VERSION ""

NS_ :

BS_:

BU_: Dummy_FO TestTool_FO LRR_FO RFSRR_FO LFSRR_FO RSRR_FO VIS_FO EOCM_F_FO

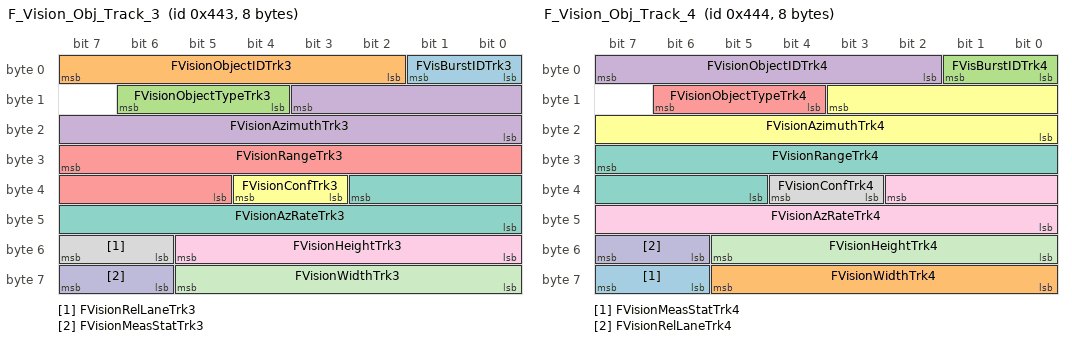
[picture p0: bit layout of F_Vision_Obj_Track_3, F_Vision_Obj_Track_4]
BO_ 1091 F_Vision_Obj_Track_3: 8 VIS_FO
 SG_ FVisBurstIDTrk3 : 1|2@0+ (1,0) [0|3] ""  EOCM_F_FO
 SG_ FVisionObjectIDTrk3 : 7|6@0+ (1,0) [0|63] ""  EOCM_F_FO
 SG_ FVisionObjectTypeTrk3 : 14|3@0+ (1,0) [0|0] ""  EOCM_F_FO
 SG_ FVisionAzimuthTrk3 : 11|12@0- (0.125,0) [-256|255.875] "deg"  EOCM_F_FO
 SG_ FVisionRangeTrk3 : 31|11@0+ (0.125,0) [0|255.875] "m"  EOCM_F_FO
 SG_ FVisionConfTrk3 : 36|2@0+ (1,0) [0|0] ""  EOCM_F_FO
 SG_ FVisionAzRateTrk3 : 34|11@0- (0.125,0) [-128|127.875] "deg/s"  EOCM_F_FO
 SG_ FVisionRelLaneTrk3 : 55|2@0+ (1,0) [0|0] ""  EOCM_F_FO
 SG_ FVisionHeightTrk3 : 53|6@0+ (0.25,0) [0|15.75] "m"  EOCM_F_FO
 SG_ FVisionMeasStatTrk3 : 63|2@0+ (1,0) [0|0] ""  EOCM_F_FO
 SG_ FVisionWidthTrk3 : 61|6@0+ (0.25,0) [0|15.75] "m"  EOCM_F_FO

BO_ 1092 F_Vision_Obj_Track_4: 8 VIS_FO
 SG_ FVisionMeasStatTrk4 : 63|2@0+ (1,0) [0|0] ""  EOCM_F_FO
 SG_ FVisionWidthTrk4 : 61|6@0+ (0.25,0) [0|15.75] "m"  EOCM_F_FO
 SG_ FVisBurstIDTrk4 : 1|2@0+ (1,0) [0|3] ""  EOCM_F_FO
 SG_ FVisionObjectIDTrk4 : 7|6@0+ (1,0) [0|63] ""  EOCM_F_FO
 SG_ FVisionObjectTypeTrk4 : 14|3@0+ (1,0) [0|0] ""  EOCM_F_FO
 SG_ FVisionAzimuthTrk4 : 11|12@0- (0.125,0) [-256|255.875] "deg"  EOCM_F_FO
 SG_ FVisionRangeTrk4 : 31|11@0+ (0.125,0) [0|255.875] "m"  EOCM_F_FO
 SG_ FVisionConfTrk4 : 36|2@0+ (1,0) [0|0] ""  EOCM_F_FO
 SG_ FVisionAzRateTrk4 : 34|11@0- (0.125,0) [-128|127.875] "deg/s"  EOCM_F_FO
 SG_ FVisionRelLaneTrk4 : 55|2@0+ (1,0) [0|0] ""  EOCM_F_FO
 SG_ FVisionHeightTrk4 : 53|6@0+ (0.25,0) [0|15.75] "m"  EOCM_F_FO

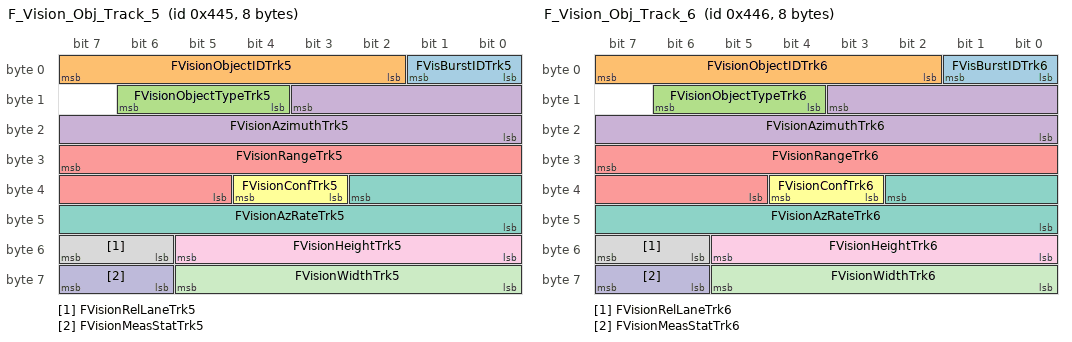
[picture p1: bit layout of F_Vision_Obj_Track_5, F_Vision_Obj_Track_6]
BO_ 1093 F_Vision_Obj_Track_5: 8 VIS_FO
 SG_ FVisBurstIDTrk5 : 1|2@0+ (1,0) [0|3] ""  EOCM_F_FO
 SG_ FVisionObjectIDTrk5 : 7|6@0+ (1,0) [0|63] ""  EOCM_F_FO
 SG_ FVisionObjectTypeTrk5 : 14|3@0+ (1,0) [0|0] ""  EOCM_F_FO
 SG_ FVisionAzimuthTrk5 : 11|12@0- (0.125,0) [-256|255.875] "deg"  EOCM_F_FO
 SG_ FVisionRangeTrk5 : 31|11@0+ (0.125,0) [0|255.875] "m"  EOCM_F_FO
 SG_ FVisionConfTrk5 : 36|2@0+ (1,0) [0|0] ""  EOCM_F_FO
 SG_ FVisionAzRateTrk5 : 34|11@0- (0.125,0) [-128|127.875] "deg/s"  EOCM_F_FO
 SG_ FVisionRelLaneTrk5 : 55|2@0+ (1,0) [0|0] ""  EOCM_F_FO
 SG_ FVisionHeightTrk5 : 53|6@0+ (0.25,0) [0|15.75] "m"  EOCM_F_FO
 SG_ FVisionMeasStatTrk5 : 63|2@0+ (1,0) [0|0] ""  EOCM_F_FO
 SG_ FVisionWidthTrk5 : 61|6@0+ (0.25,0) [0|15.75] "m"  EOCM_F_FO

BO_ 1094 F_Vision_Obj_Track_6: 8 VIS_FO
 SG_ FVisBurstIDTrk6 : 1|2@0+ (1,0) [0|3] ""  EOCM_F_FO
 SG_ FVisionObjectIDTrk6 : 7|6@0+ (1,0) [0|63] ""  EOCM_F_FO
 SG_ FVisionObjectTypeTrk6 : 14|3@0+ (1,0) [0|0] ""  EOCM_F_FO
 SG_ FVisionAzimuthTrk6 : 11|12@0- (0.125,0) [-256|255.875] "deg"  EOCM_F_FO
 SG_ FVisionRangeTrk6 : 31|11@0+ (0.125,0) [0|255.875] "m"  EOCM_F_FO
 SG_ FVisionConfTrk6 : 36|2@0+ (1,0) [0|0] ""  EOCM_F_FO
 SG_ FVisionAzRateTrk6 : 34|11@0- (0.125,0) [-128|127.875] "deg/s"  EOCM_F_FO
 SG_ FVisionRelLaneTrk6 : 55|2@0+ (1,0) [0|0] ""  EOCM_F_FO
 SG_ FVisionHeightTrk6 : 53|6@0+ (0.25,0) [0|15.75] "m"  EOCM_F_FO
 SG_ FVisionMeasStatTrk6 : 63|2@0+ (1,0) [0|0] ""  EOCM_F_FO
 SG_ FVisionWidthTrk6 : 61|6@0+ (0.25,0) [0|15.75] "m"  EOCM_F_FO

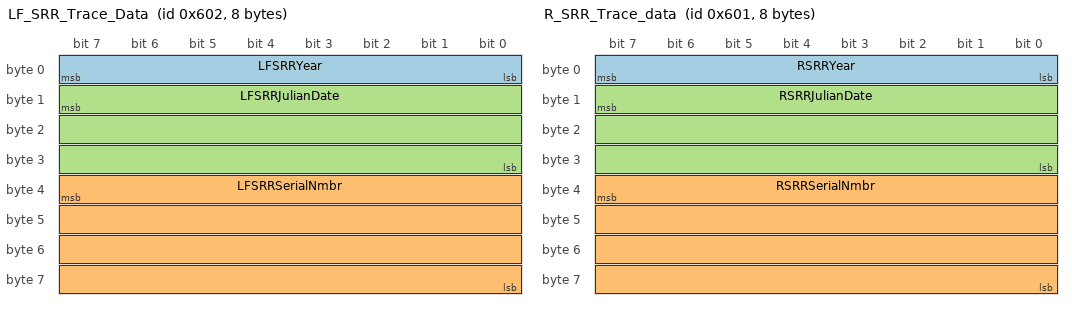
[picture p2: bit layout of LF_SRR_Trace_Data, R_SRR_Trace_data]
BO_ 1538 LF_SRR_Trace_Data: 8 LFSRR_FO
 SG_ LFSRRYear : 7|8@0+ (1,0) [0|0] ""  EOCM_F_FO
 SG_ LFSRRSerialNmbr : 39|32@0+ (1,0) [0|0] ""  EOCM_F_FO
 SG_ LFSRRJulianDate : 15|24@0+ (1,0) [0|0] ""  EOCM_F_FO

BO_ 1537 R_SRR_Trace_data: 8 RSRR_FO
 SG_ RSRRYear : 7|8@0+ (1,0) [0|0] ""  EOCM_F_FO
 SG_ RSRRSerialNmbr : 39|32@0+ (1,0) [0|0] ""  EOCM_F_FO
 SG_ RSRRJulianDate : 15|24@0+ (1,0) [0|0] ""  EOCM_F_FO

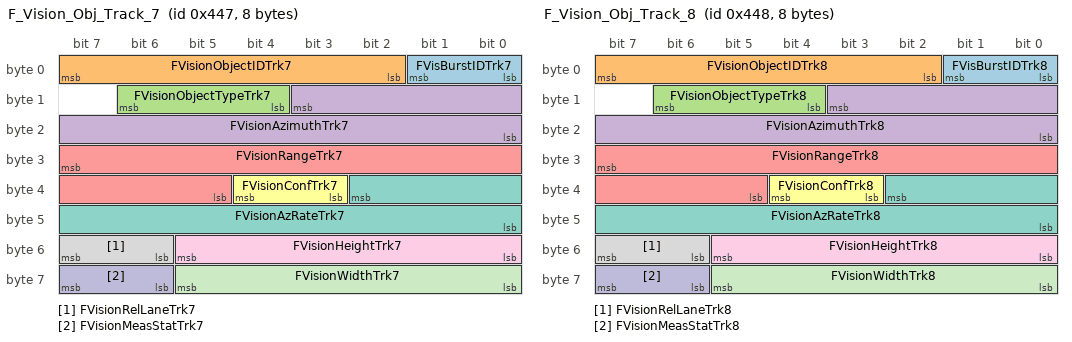
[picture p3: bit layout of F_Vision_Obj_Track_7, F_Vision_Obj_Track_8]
BO_ 1095 F_Vision_Obj_Track_7: 8 VIS_FO
 SG_ FVisBurstIDTrk7 : 1|2@0+ (1,0) [0|3] ""  EOCM_F_FO
 SG_ FVisionObjectIDTrk7 : 7|6@0+ (1,0) [0|63] ""  EOCM_F_FO
 SG_ FVisionObjectTypeTrk7 : 14|3@0+ (1,0) [0|0] ""  EOCM_F_FO
 SG_ FVisionAzimuthTrk7 : 11|12@0- (0.125,0) [-256|255.875] "deg"  EOCM_F_FO
 SG_ FVisionRangeTrk7 : 31|11@0+ (0.125,0) [0|255.875] "m"  EOCM_F_FO
 SG_ FVisionConfTrk7 : 36|2@0+ (1,0) [0|0] ""  EOCM_F_FO
 SG_ FVisionAzRateTrk7 : 34|11@0- (0.125,0) [-128|127.875] "deg/s"  EOCM_F_FO
 SG_ FVisionRelLaneTrk7 : 55|2@0+ (1,0) [0|0] ""  EOCM_F_FO
 SG_ FVisionHeightTrk7 : 53|6@0+ (0.25,0) [0|15.75] "m"  EOCM_F_FO
 SG_ FVisionMeasStatTrk7 : 63|2@0+ (1,0) [0|0] ""  EOCM_F_FO
 SG_ FVisionWidthTrk7 : 61|6@0+ (0.25,0) [0|15.75] "m"  EOCM_F_FO

BO_ 1096 F_Vision_Obj_Track_8: 8 VIS_FO
 SG_ FVisBurstIDTrk8 : 1|2@0+ (1,0) [0|3] ""  EOCM_F_FO
 SG_ FVisionObjectIDTrk8 : 7|6@0+ (1,0) [0|63] ""  EOCM_F_FO
 SG_ FVisionObjectTypeTrk8 : 14|3@0+ (1,0) [0|0] ""  EOCM_F_FO
 SG_ FVisionAzimuthTrk8 : 11|12@0- (0.125,0) [-256|255.875] "deg"  EOCM_F_FO
 SG_ FVisionRangeTrk8 : 31|11@0+ (0.125,0) [0|255.875] "m"  EOCM_F_FO
 SG_ FVisionConfTrk8 : 36|2@0+ (1,0) [0|0] ""  EOCM_F_FO
 SG_ FVisionAzRateTrk8 : 34|11@0- (0.125,0) [-128|127.875] "deg/s"  EOCM_F_FO
 SG_ FVisionRelLaneTrk8 : 55|2@0+ (1,0) [0|0] ""  EOCM_F_FO
 SG_ FVisionHeightTrk8 : 53|6@0+ (0.25,0) [0|15.75] "m"  EOCM_F_FO
 SG_ FVisionMeasStatTrk8 : 63|2@0+ (1,0) [0|0] ""  EOCM_F_FO
 SG_ FVisionWidthTrk8 : 61|6@0+ (0.25,0) [0|15.75] "m"  EOCM_F_FO

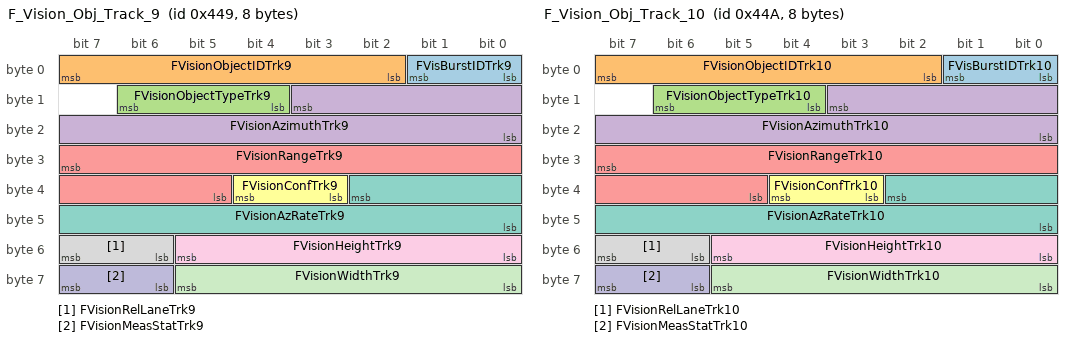
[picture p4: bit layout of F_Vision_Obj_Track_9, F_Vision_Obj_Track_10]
BO_ 1097 F_Vision_Obj_Track_9: 8 VIS_FO
 SG_ FVisBurstIDTrk9 : 1|2@0+ (1,0) [0|3] ""  EOCM_F_FO
 SG_ FVisionObjectIDTrk9 : 7|6@0+ (1,0) [0|63] ""  EOCM_F_FO
 SG_ FVisionObjectTypeTrk9 : 14|3@0+ (1,0) [0|0] ""  EOCM_F_FO
 SG_ FVisionAzimuthTrk9 : 11|12@0- (0.125,0) [-256|255.875] "deg"  EOCM_F_FO
 SG_ FVisionRangeTrk9 : 31|11@0+ (0.125,0) [0|255.875] "m"  EOCM_F_FO
 SG_ FVisionConfTrk9 : 36|2@0+ (1,0) [0|0] ""  EOCM_F_FO
 SG_ FVisionAzRateTrk9 : 34|11@0- (0.125,0) [-128|127.875] "deg/s"  EOCM_F_FO
 SG_ FVisionRelLaneTrk9 : 55|2@0+ (1,0) [0|0] ""  EOCM_F_FO
 SG_ FVisionHeightTrk9 : 53|6@0+ (0.25,0) [0|15.75] "m"  EOCM_F_FO
 SG_ FVisionMeasStatTrk9 : 63|2@0+ (1,0) [0|0] ""  EOCM_F_FO
 SG_ FVisionWidthTrk9 : 61|6@0+ (0.25,0) [0|15.75] "m"  EOCM_F_FO

BO_ 1098 F_Vision_Obj_Track_10: 8 VIS_FO
 SG_ FVisBurstIDTrk10 : 1|2@0+ (1,0) [0|3] ""  EOCM_F_FO
 SG_ FVisionObjectIDTrk10 : 7|6@0+ (1,0) [0|63] ""  EOCM_F_FO
 SG_ FVisionObjectTypeTrk10 : 14|3@0+ (1,0) [0|0] ""  EOCM_F_FO
 SG_ FVisionAzimuthTrk10 : 11|12@0- (0.125,0) [-256|255.875] "deg"  EOCM_F_FO
 SG_ FVisionRangeTrk10 : 31|11@0+ (0.125,0) [0|255.875] "m"  EOCM_F_FO
 SG_ FVisionConfTrk10 : 36|2@0+ (1,0) [0|0] ""  EOCM_F_FO
 SG_ FVisionAzRateTrk10 : 34|11@0- (0.125,0) [-128|127.875] "deg/s"  EOCM_F_FO
 SG_ FVisionRelLaneTrk10 : 55|2@0+ (1,0) [0|0] ""  EOCM_F_FO
 SG_ FVisionHeightTrk10 : 53|6@0+ (0.25,0) [0|15.75] "m"  EOCM_F_FO
 SG_ FVisionMeasStatTrk10 : 63|2@0+ (1,0) [0|0] ""  EOCM_F_FO
 SG_ FVisionWidthTrk10 : 61|6@0+ (0.25,0) [0|15.75] "m"  EOCM_F_FO

BO_ 1120 F_LRR_Obj_Header: 8 LRR_FO
 SG_ FLRRRollingCount : 7|2@0+ (1,0) [0|3] ""  EOCM_F_FO
 SG_ FLRRModeCmdFdbk : 23|3@0+ (1,0) [0|0] ""  EOCM_F_FO
 SG_ FLRRNumValidTargets : 20|5@0+ (1,0) [0|31] ""  EOCM_F_FO
 SG_ FLRRTimeStampV : 31|1@0+ (1,0) [0|1] ""  EOCM_F_FO
 SG_ FLRRTimeStamp : 2|11@0+ (1,0) [0|2047] "ms"  EOCM_F_FO
 SG_ FLRRRoadTypeInfo : 5|3@0+ (1,0) [0|7] ""  EOCM_F_FO
 SG_ FLRRBurstChecksum : 55|16@0+ (1,0) [0|65535] ""  EOCM_F_FO
 SG_ FLRRDiagSpare : 30|1@0+ (1,0) [0|1] ""  EOCM_F_FO
 SG_ FLRRVltgOutRngLo : 44|1@0+ (1,0) [0|1] ""  EOCM_F_FO
 SG_ FLRRVltgOutRngHi : 43|1@0+ (1,0) [0|1] ""  EOCM_F_FO
 SG_ FLRRSvcAlgnInPrcs : 38|1@0+ (1,0) [0|1] ""  EOCM_F_FO
 SG_ FLRRSnsrBlckd : 45|1@0+ (1,0) [0|1] ""  EOCM_F_FO
 SG_ FLRRSnstvFltPrsntInt : 24|1@0+ (1,0) [0|1] ""  EOCM_F_FO
 SG_ FLRRPlntAlgnInProc : 37|1@0+ (1,0) [0|1] ""  EOCM_F_FO
 SG_ FLRRMsalgnYawRt : 47|1@0+ (1,0) [0|1] ""  EOCM_F_FO
 SG_ FLRRMsalgnYawLt : 46|1@0+ (1,0) [0|1] ""  EOCM_F_FO
 SG_ FLRRMsalgnRllRt : 35|1@0+ (1,0) [0|1] ""  EOCM_F_FO
 SG_ FLRRMsalgnRllLt : 34|1@0+ (1,0) [0|1] ""  EOCM_F_FO
 SG_ FLRRMsalgnPtchUp : 32|1@0+ (1,0) [0|1] ""  EOCM_F_FO
 SG_ FLRRMsalgnPtchDn : 33|1@0+ (1,0) [0|1] ""  EOCM_F_FO
 SG_ FLRRInitDiagCmplt : 40|1@0+ (1,0) [0|1] ""  EOCM_F_FO
 SG_ FLRRHWFltPrsntInt : 25|1@0+ (1,0) [0|1] ""  EOCM_F_FO
 SG_ FLRRExtIntrfrnc : 36|1@0+ (1,0) [0|1] ""  EOCM_F_FO
 SG_ FLRRCANSgnlSpvFld : 29|1@0+ (1,0) [0|1] ""  EOCM_F_FO
 SG_ FLRRCANRxErr : 28|1@0+ (1,0) [0|1] ""  EOCM_F_FO
 SG_ FLRRCANIDAddrsUnsbl : 27|1@0+ (1,0) [0|1] ""  EOCM_F_FO
 SG_ FLRRAmbTmpOutRngLw : 42|1@0+ (1,0) [0|1] ""  EOCM_F_FO
 SG_ FLRRAmbTmpOutRngHi : 41|1@0+ (1,0) [0|1] ""  EOCM_F_FO
 SG_ FLRRAntTngFltPrsnt : 26|1@0+ (1,0) [0|1] ""  EOCM_F_FO
 SG_ FLRRAlgnFltPrsnt : 39|1@0+ (1,0) [0|1] ""  EOCM_F_FO

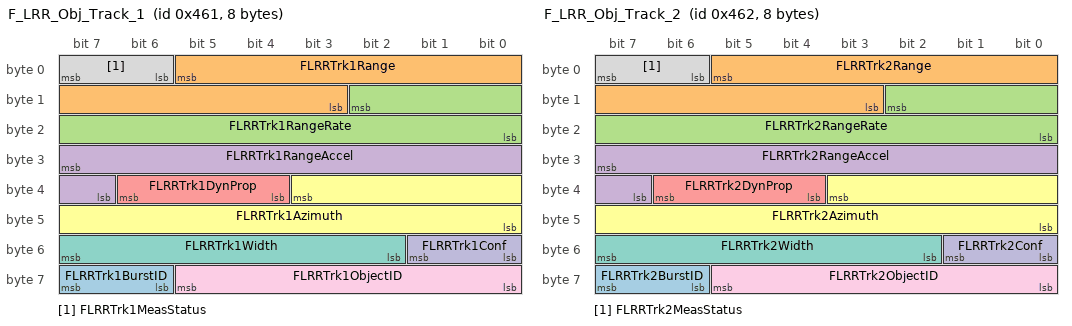
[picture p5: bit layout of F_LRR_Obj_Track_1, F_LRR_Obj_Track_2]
BO_ 1121 F_LRR_Obj_Track_1: 8 LRR_FO
 SG_ FLRRTrk1BurstID : 63|2@0+ (1,0) [0|3] ""  EOCM_F_FO
 SG_ FLRRTrk1Range : 5|11@0+ (0.125,0) [0|255.875] "m"  EOCM_F_FO
 SG_ FLRRTrk1RangeRate : 10|11@0- (0.125,0) [-128|127.875] "m/s"  EOCM_F_FO
 SG_ FLRRTrk1RangeAccel : 31|9@0- (0.125,0) [-32|31.875] "m/s^2"  EOCM_F_FO
 SG_ FLRRTrk1DynProp : 38|3@0+ (1,0) [0|0] ""  EOCM_F_FO
 SG_ FLRRTrk1Azimuth : 35|12@0- (0.125,0) [-256|255.875] "deg"  EOCM_F_FO
 SG_ FLRRTrk1Width : 55|6@0+ (0.25,0) [0|15.75] "m"  EOCM_F_FO
 SG_ FLRRTrk1MeasStatus : 7|2@0+ (1,0) [0|0] ""  EOCM_F_FO
 SG_ FLRRTrk1ObjectID : 61|6@0+ (1,0) [0|63] ""  EOCM_F_FO
 SG_ FLRRTrk1Conf : 49|2@0+ (1,0) [0|0] ""  EOCM_F_FO

BO_ 1122 F_LRR_Obj_Track_2: 8 LRR_FO
 SG_ FLRRTrk2BurstID : 63|2@0+ (1,0) [0|3] ""  EOCM_F_FO
 SG_ FLRRTrk2Range : 5|11@0+ (0.125,0) [0|255.875] "m"  EOCM_F_FO
 SG_ FLRRTrk2RangeRate : 10|11@0- (0.125,0) [-128|127.875] "m/s"  EOCM_F_FO
 SG_ FLRRTrk2RangeAccel : 31|9@0- (0.125,0) [-32|31.875] "m/s^2"  EOCM_F_FO
 SG_ FLRRTrk2DynProp : 38|3@0+ (1,0) [0|0] ""  EOCM_F_FO
 SG_ FLRRTrk2Azimuth : 35|12@0- (0.125,0) [-256|255.875] "deg"  EOCM_F_FO
 SG_ FLRRTrk2Width : 55|6@0+ (0.25,0) [0|15.75] "m"  EOCM_F_FO
 SG_ FLRRTrk2MeasStatus : 7|2@0+ (1,0) [0|0] ""  EOCM_F_FO
 SG_ FLRRTrk2ObjectID : 61|6@0+ (1,0) [0|63] ""  EOCM_F_FO
 SG_ FLRRTrk2Conf : 49|2@0+ (1,0) [0|0] ""  EOCM_F_FO

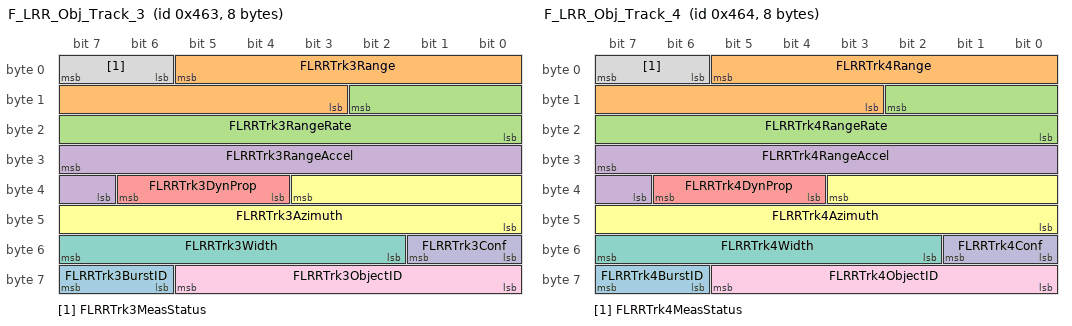
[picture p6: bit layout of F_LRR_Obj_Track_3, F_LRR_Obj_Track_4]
BO_ 1123 F_LRR_Obj_Track_3: 8 LRR_FO
 SG_ FLRRTrk3BurstID : 63|2@0+ (1,0) [0|3] ""  EOCM_F_FO
 SG_ FLRRTrk3Range : 5|11@0+ (0.125,0) [0|255.875] "m"  EOCM_F_FO
 SG_ FLRRTrk3RangeRate : 10|11@0- (0.125,0) [-128|127.875] "m/s"  EOCM_F_FO
 SG_ FLRRTrk3RangeAccel : 31|9@0- (0.125,0) [-32|31.875] "m/s^2"  EOCM_F_FO
 SG_ FLRRTrk3DynProp : 38|3@0+ (1,0) [0|0] ""  EOCM_F_FO
 SG_ FLRRTrk3Azimuth : 35|12@0- (0.125,0) [-256|255.875] "deg"  EOCM_F_FO
 SG_ FLRRTrk3Width : 55|6@0+ (0.25,0) [0|15.75] "m"  EOCM_F_FO
 SG_ FLRRTrk3MeasStatus : 7|2@0+ (1,0) [0|0] ""  EOCM_F_FO
 SG_ FLRRTrk3ObjectID : 61|6@0+ (1,0) [0|63] ""  EOCM_F_FO
 SG_ FLRRTrk3Conf : 49|2@0+ (1,0) [0|0] ""  EOCM_F_FO

BO_ 1124 F_LRR_Obj_Track_4: 8 LRR_FO
 SG_ FLRRTrk4BurstID : 63|2@0+ (1,0) [0|3] ""  EOCM_F_FO
 SG_ FLRRTrk4Range : 5|11@0+ (0.125,0) [0|255.875] "m"  EOCM_F_FO
 SG_ FLRRTrk4RangeRate : 10|11@0- (0.125,0) [-128|127.875] "m/s"  EOCM_F_FO
 SG_ FLRRTrk4RangeAccel : 31|9@0- (0.125,0) [-32|31.875] "m/s^2"  EOCM_F_FO
 SG_ FLRRTrk4DynProp : 38|3@0+ (1,0) [0|0] ""  EOCM_F_FO
 SG_ FLRRTrk4Azimuth : 35|12@0- (0.125,0) [-256|255.875] "deg"  EOCM_F_FO
 SG_ FLRRTrk4Width : 55|6@0+ (0.25,0) [0|15.75] "m"  EOCM_F_FO
 SG_ FLRRTrk4MeasStatus : 7|2@0+ (1,0) [0|0] ""  EOCM_F_FO
 SG_ FLRRTrk4ObjectID : 61|6@0+ (1,0) [0|63] ""  EOCM_F_FO
 SG_ FLRRTrk4Conf : 49|2@0+ (1,0) [0|0] ""  EOCM_F_FO

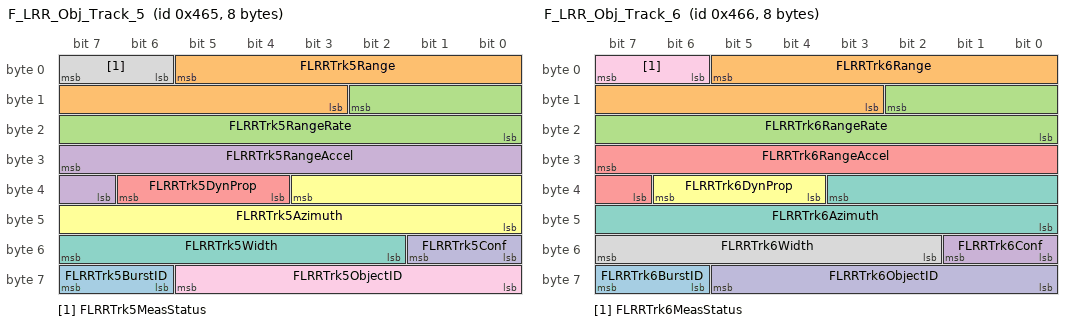
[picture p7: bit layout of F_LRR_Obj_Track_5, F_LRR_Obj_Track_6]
BO_ 1125 F_LRR_Obj_Track_5: 8 LRR_FO
 SG_ FLRRTrk5BurstID : 63|2@0+ (1,0) [0|3] ""  EOCM_F_FO
 SG_ FLRRTrk5Range : 5|11@0+ (0.125,0) [0|255.875] "m"  EOCM_F_FO
 SG_ FLRRTrk5RangeRate : 10|11@0- (0.125,0) [-128|127.875] "m/s"  EOCM_F_FO
 SG_ FLRRTrk5RangeAccel : 31|9@0- (0.125,0) [-32|31.875] "m/s^2"  EOCM_F_FO
 SG_ FLRRTrk5DynProp : 38|3@0+ (1,0) [0|0] ""  EOCM_F_FO
 SG_ FLRRTrk5Azimuth : 35|12@0- (0.125,0) [-256|255.875] "deg"  EOCM_F_FO
 SG_ FLRRTrk5Width : 55|6@0+ (0.25,0) [0|15.75] "m"  EOCM_F_FO
 SG_ FLRRTrk5MeasStatus : 7|2@0+ (1,0) [0|0] ""  EOCM_F_FO
 SG_ FLRRTrk5ObjectID : 61|6@0+ (1,0) [0|63] ""  EOCM_F_FO
 SG_ FLRRTrk5Conf : 49|2@0+ (1,0) [0|0] ""  EOCM_F_FO

BO_ 1126 F_LRR_Obj_Track_6: 8 LRR_FO
 SG_ FLRRTrk6BurstID : 63|2@0+ (1,0) [0|3] ""  EOCM_F_FO
 SG_ FLRRTrk6Range : 5|11@0+ (0.125,0) [0|255.875] "m"  EOCM_F_FO
 SG_ FLRRTrk6RangeRate : 10|11@0- (0.125,0) [-128|127.875] "m/s"  EOCM_F_FO
 SG_ FLRRTrk6Conf : 49|2@0+ (1,0) [0|0] ""  EOCM_F_FO
 SG_ FLRRTrk6RangeAccel : 31|9@0- (0.125,0) [-32|31.875] "m/s^2"  EOCM_F_FO
 SG_ FLRRTrk6DynProp : 38|3@0+ (1,0) [0|0] ""  EOCM_F_FO
 SG_ FLRRTrk6Azimuth : 35|12@0- (0.125,0) [-256|255.875] "deg"  EOCM_F_FO
 SG_ FLRRTrk6Width : 55|6@0+ (0.25,0) [0|15.75] "m"  EOCM_F_FO
 SG_ FLRRTrk6MeasStatus : 7|2@0+ (1,0) [0|0] ""  EOCM_F_FO
 SG_ FLRRTrk6ObjectID : 61|6@0+ (1,0) [0|63] ""  EOCM_F_FO

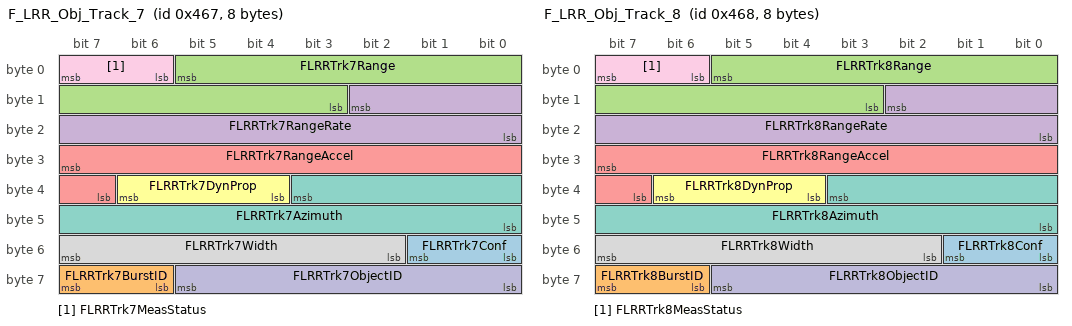
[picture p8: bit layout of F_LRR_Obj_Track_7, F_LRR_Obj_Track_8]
BO_ 1127 F_LRR_Obj_Track_7: 8 LRR_FO
 SG_ FLRRTrk7Conf : 49|2@0+ (1,0) [0|0] ""  EOCM_F_FO
 SG_ FLRRTrk7BurstID : 63|2@0+ (1,0) [0|3] ""  EOCM_F_FO
 SG_ FLRRTrk7Range : 5|11@0+ (0.125,0) [0|255.875] "m"  EOCM_F_FO
 SG_ FLRRTrk7RangeRate : 10|11@0- (0.125,0) [-128|127.875] "m/s"  EOCM_F_FO
 SG_ FLRRTrk7RangeAccel : 31|9@0- (0.125,0) [-32|31.875] "m/s^2"  EOCM_F_FO
 SG_ FLRRTrk7DynProp : 38|3@0+ (1,0) [0|0] ""  EOCM_F_FO
 SG_ FLRRTrk7Azimuth : 35|12@0- (0.125,0) [-256|255.875] "deg"  EOCM_F_FO
 SG_ FLRRTrk7Width : 55|6@0+ (0.25,0) [0|15.75] "m"  EOCM_F_FO
 SG_ FLRRTrk7MeasStatus : 7|2@0+ (1,0) [0|0] ""  EOCM_F_FO
 SG_ FLRRTrk7ObjectID : 61|6@0+ (1,0) [0|63] ""  EOCM_F_FO

BO_ 1128 F_LRR_Obj_Track_8: 8 LRR_FO
 SG_ FLRRTrk8Conf : 49|2@0+ (1,0) [0|0] ""  EOCM_F_FO
 SG_ FLRRTrk8BurstID : 63|2@0+ (1,0) [0|3] ""  EOCM_F_FO
 SG_ FLRRTrk8Range : 5|11@0+ (0.125,0) [0|255.875] "m"  EOCM_F_FO
 SG_ FLRRTrk8RangeRate : 10|11@0- (0.125,0) [-128|127.875] "m/s"  EOCM_F_FO
 SG_ FLRRTrk8RangeAccel : 31|9@0- (0.125,0) [-32|31.875] "m/s^2"  EOCM_F_FO
 SG_ FLRRTrk8DynProp : 38|3@0+ (1,0) [0|0] ""  EOCM_F_FO
 SG_ FLRRTrk8Azimuth : 35|12@0- (0.125,0) [-256|255.875] "deg"  EOCM_F_FO
 SG_ FLRRTrk8Width : 55|6@0+ (0.25,0) [0|15.75] "m"  EOCM_F_FO
 SG_ FLRRTrk8MeasStatus : 7|2@0+ (1,0) [0|0] ""  EOCM_F_FO
 SG_ FLRRTrk8ObjectID : 61|6@0+ (1,0) [0|63] ""  EOCM_F_FO

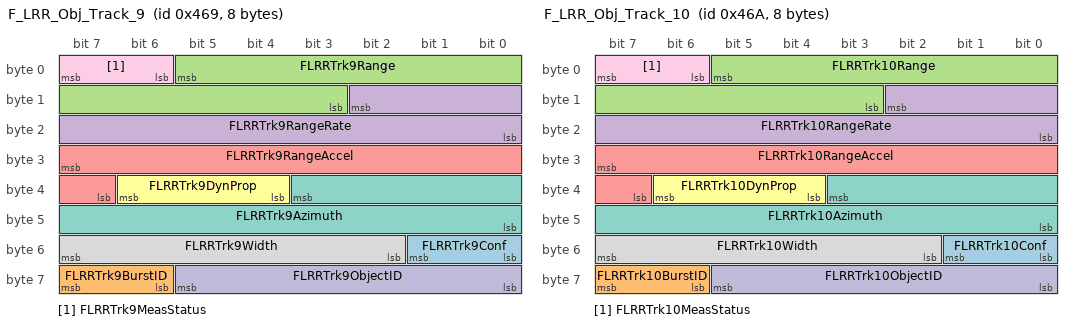
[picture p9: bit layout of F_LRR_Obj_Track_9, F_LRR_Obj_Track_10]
BO_ 1129 F_LRR_Obj_Track_9: 8 LRR_FO
 SG_ FLRRTrk9Conf : 49|2@0+ (1,0) [0|0] ""  EOCM_F_FO
 SG_ FLRRTrk9BurstID : 63|2@0+ (1,0) [0|3] ""  EOCM_F_FO
 SG_ FLRRTrk9Range : 5|11@0+ (0.125,0) [0|255.875] "m"  EOCM_F_FO
 SG_ FLRRTrk9RangeRate : 10|11@0- (0.125,0) [-128|127.875] "m/s"  EOCM_F_FO
 SG_ FLRRTrk9RangeAccel : 31|9@0- (0.125,0) [-32|31.875] "m/s^2"  EOCM_F_FO
 SG_ FLRRTrk9DynProp : 38|3@0+ (1,0) [0|0] ""  EOCM_F_FO
 SG_ FLRRTrk9Azimuth : 35|12@0- (0.125,0) [-256|255.875] "deg"  EOCM_F_FO
 SG_ FLRRTrk9Width : 55|6@0+ (0.25,0) [0|15.75] "m"  EOCM_F_FO
 SG_ FLRRTrk9MeasStatus : 7|2@0+ (1,0) [0|0] ""  EOCM_F_FO
 SG_ FLRRTrk9ObjectID : 61|6@0+ (1,0) [0|63] ""  EOCM_F_FO

BO_ 1130 F_LRR_Obj_Track_10: 8 LRR_FO
 SG_ FLRRTrk10Conf : 49|2@0+ (1,0) [0|0] ""  EOCM_F_FO
 SG_ FLRRTrk10BurstID : 63|2@0+ (1,0) [0|3] ""  EOCM_F_FO
 SG_ FLRRTrk10Range : 5|11@0+ (0.125,0) [0|255.875] "m"  EOCM_F_FO
 SG_ FLRRTrk10RangeRate : 10|11@0- (0.125,0) [-128|127.875] "m/s"  EOCM_F_FO
 SG_ FLRRTrk10RangeAccel : 31|9@0- (0.125,0) [-32|31.875] "m/s^2"  EOCM_F_FO
 SG_ FLRRTrk10DynProp : 38|3@0+ (1,0) [0|0] ""  EOCM_F_FO
 SG_ FLRRTrk10Azimuth : 35|12@0- (0.125,0) [-256|255.875] "deg"  EOCM_F_FO
 SG_ FLRRTrk10Width : 55|6@0+ (0.25,0) [0|15.75] "m"  EOCM_F_FO
 SG_ FLRRTrk10MeasStatus : 7|2@0+ (1,0) [0|0] ""  EOCM_F_FO
 SG_ FLRRTrk10ObjectID : 61|6@0+ (1,0) [0|63] ""  EOCM_F_FO

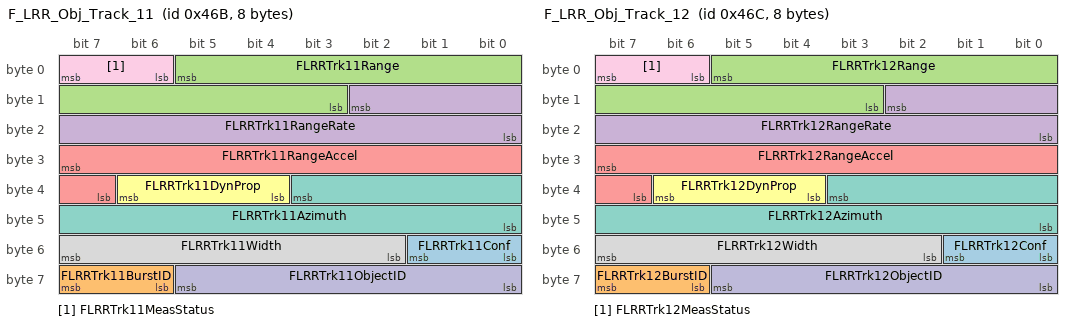
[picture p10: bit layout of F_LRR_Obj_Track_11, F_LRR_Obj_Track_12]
BO_ 1131 F_LRR_Obj_Track_11: 8 LRR_FO
 SG_ FLRRTrk11Conf : 49|2@0+ (1,0) [0|0] ""  EOCM_F_FO
 SG_ FLRRTrk11BurstID : 63|2@0+ (1,0) [0|3] ""  EOCM_F_FO
 SG_ FLRRTrk11Range : 5|11@0+ (0.125,0) [0|255.875] "m"  EOCM_F_FO
 SG_ FLRRTrk11RangeRate : 10|11@0- (0.125,0) [-128|127.875] "m/s"  EOCM_F_FO
 SG_ FLRRTrk11RangeAccel : 31|9@0- (0.125,0) [-32|31.875] "m/s^2"  EOCM_F_FO
 SG_ FLRRTrk11DynProp : 38|3@0+ (1,0) [0|0] ""  EOCM_F_FO
 SG_ FLRRTrk11Azimuth : 35|12@0- (0.125,0) [-256|255.875] "deg"  EOCM_F_FO
 SG_ FLRRTrk11Width : 55|6@0+ (0.25,0) [0|15.75] "m"  EOCM_F_FO
 SG_ FLRRTrk11MeasStatus : 7|2@0+ (1,0) [0|0] ""  EOCM_F_FO
 SG_ FLRRTrk11ObjectID : 61|6@0+ (1,0) [0|63] ""  EOCM_F_FO

BO_ 1132 F_LRR_Obj_Track_12: 8 LRR_FO
 SG_ FLRRTrk12Conf : 49|2@0+ (1,0) [0|0] ""  EOCM_F_FO
 SG_ FLRRTrk12BurstID : 63|2@0+ (1,0) [0|3] ""  EOCM_F_FO
 SG_ FLRRTrk12Range : 5|11@0+ (0.125,0) [0|255.875] "m"  EOCM_F_FO
 SG_ FLRRTrk12RangeRate : 10|11@0- (0.125,0) [-128|127.875] "m/s"  EOCM_F_FO
 SG_ FLRRTrk12RangeAccel : 31|9@0- (0.125,0) [-32|31.875] "m/s^2"  EOCM_F_FO
 SG_ FLRRTrk12DynProp : 38|3@0+ (1,0) [0|0] ""  EOCM_F_FO
 SG_ FLRRTrk12Azimuth : 35|12@0- (0.125,0) [-256|255.875] "deg"  EOCM_F_FO
 SG_ FLRRTrk12Width : 55|6@0+ (0.25,0) [0|15.75] "m"  EOCM_F_FO
 SG_ FLRRTrk12MeasStatus : 7|2@0+ (1,0) [0|0] ""  EOCM_F_FO
 SG_ FLRRTrk12ObjectID : 61|6@0+ (1,0) [0|63] ""  EOCM_F_FO

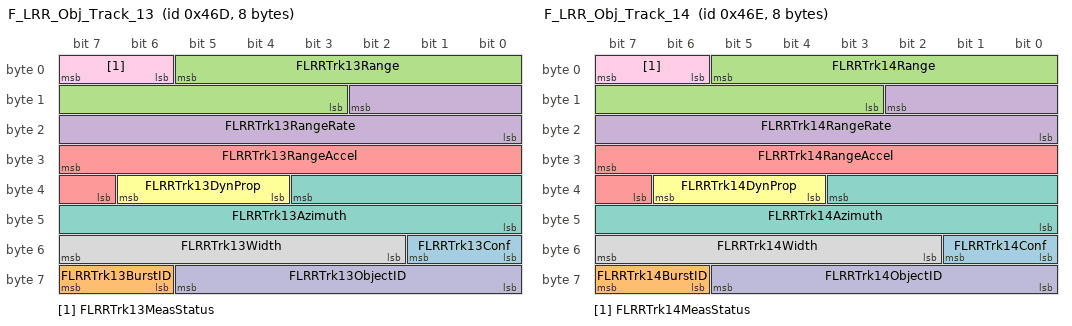
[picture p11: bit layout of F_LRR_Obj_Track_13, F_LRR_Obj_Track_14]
BO_ 1133 F_LRR_Obj_Track_13: 8 LRR_FO
 SG_ FLRRTrk13Conf : 49|2@0+ (1,0) [0|0] ""  EOCM_F_FO
 SG_ FLRRTrk13BurstID : 63|2@0+ (1,0) [0|3] ""  EOCM_F_FO
 SG_ FLRRTrk13Range : 5|11@0+ (0.125,0) [0|255.875] "m"  EOCM_F_FO
 SG_ FLRRTrk13RangeRate : 10|11@0- (0.125,0) [-128|127.875] "m/s"  EOCM_F_FO
 SG_ FLRRTrk13RangeAccel : 31|9@0- (0.125,0) [-32|31.875] "m/s^2"  EOCM_F_FO
 SG_ FLRRTrk13DynProp : 38|3@0+ (1,0) [0|0] ""  EOCM_F_FO
 SG_ FLRRTrk13Azimuth : 35|12@0- (0.125,0) [-256|255.875] "deg"  EOCM_F_FO
 SG_ FLRRTrk13Width : 55|6@0+ (0.25,0) [0|15.75] "m"  EOCM_F_FO
 SG_ FLRRTrk13MeasStatus : 7|2@0+ (1,0) [0|0] ""  EOCM_F_FO
 SG_ FLRRTrk13ObjectID : 61|6@0+ (1,0) [0|63] ""  EOCM_F_FO

BO_ 1134 F_LRR_Obj_Track_14: 8 LRR_FO
 SG_ FLRRTrk14Conf : 49|2@0+ (1,0) [0|0] ""  EOCM_F_FO
 SG_ FLRRTrk14BurstID : 63|2@0+ (1,0) [0|3] ""  EOCM_F_FO
 SG_ FLRRTrk14Range : 5|11@0+ (0.125,0) [0|255.875] "m"  EOCM_F_FO
 SG_ FLRRTrk14RangeRate : 10|11@0- (0.125,0) [-128|127.875] "m/s"  EOCM_F_FO
 SG_ FLRRTrk14RangeAccel : 31|9@0- (0.125,0) [-32|31.875] "m/s^2"  EOCM_F_FO
 SG_ FLRRTrk14DynProp : 38|3@0+ (1,0) [0|0] ""  EOCM_F_FO
 SG_ FLRRTrk14Azimuth : 35|12@0- (0.125,0) [-256|255.875] "deg"  EOCM_F_FO
 SG_ FLRRTrk14Width : 55|6@0+ (0.25,0) [0|15.75] "m"  EOCM_F_FO
 SG_ FLRRTrk14MeasStatus : 7|2@0+ (1,0) [0|0] ""  EOCM_F_FO
 SG_ FLRRTrk14ObjectID : 61|6@0+ (1,0) [0|63] ""  EOCM_F_FO

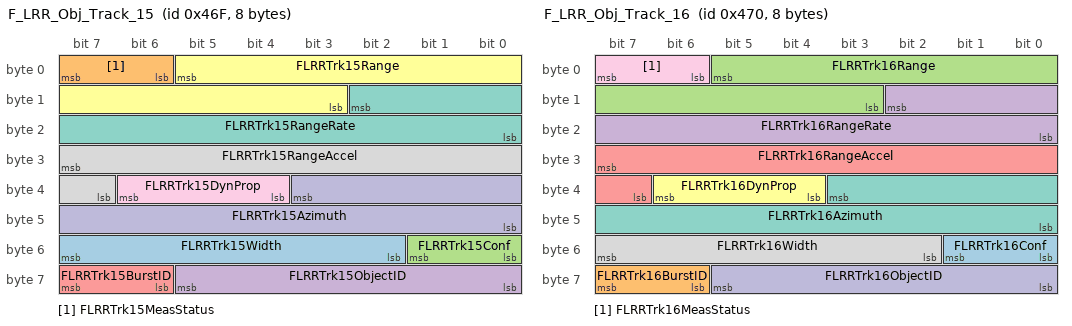
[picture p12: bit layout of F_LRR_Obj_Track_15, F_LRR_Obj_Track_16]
BO_ 1135 F_LRR_Obj_Track_15: 8 LRR_FO
 SG_ FLRRTrk15Width : 55|6@0+ (0.25,0) [0|15.75] "m"  EOCM_F_FO
 SG_ FLRRTrk15MeasStatus : 7|2@0+ (1,0) [0|0] ""  EOCM_F_FO
 SG_ FLRRTrk15Conf : 49|2@0+ (1,0) [0|0] ""  EOCM_F_FO
 SG_ FLRRTrk15ObjectID : 61|6@0+ (1,0) [0|63] ""  EOCM_F_FO
 SG_ FLRRTrk15BurstID : 63|2@0+ (1,0) [0|3] ""  EOCM_F_FO
 SG_ FLRRTrk15Range : 5|11@0+ (0.125,0) [0|255.875] "m"  EOCM_F_FO
 SG_ FLRRTrk15RangeRate : 10|11@0- (0.125,0) [-128|127.875] "m/s"  EOCM_F_FO
 SG_ FLRRTrk15RangeAccel : 31|9@0- (0.125,0) [-32|31.875] "m/s^2"  EOCM_F_FO
 SG_ FLRRTrk15DynProp : 38|3@0+ (1,0) [0|0] ""  EOCM_F_FO
 SG_ FLRRTrk15Azimuth : 35|12@0- (0.125,0) [-256|255.875] "deg"  EOCM_F_FO

BO_ 1136 F_LRR_Obj_Track_16: 8 LRR_FO
 SG_ FLRRTrk16Conf : 49|2@0+ (1,0) [0|0] ""  EOCM_F_FO
 SG_ FLRRTrk16BurstID : 63|2@0+ (1,0) [0|3] ""  EOCM_F_FO
 SG_ FLRRTrk16Range : 5|11@0+ (0.125,0) [0|255.875] "m"  EOCM_F_FO
 SG_ FLRRTrk16RangeRate : 10|11@0- (0.125,0) [-128|127.875] "m/s"  EOCM_F_FO
 SG_ FLRRTrk16RangeAccel : 31|9@0- (0.125,0) [-32|31.875] "m/s^2"  EOCM_F_FO
 SG_ FLRRTrk16DynProp : 38|3@0+ (1,0) [0|0] ""  EOCM_F_FO
 SG_ FLRRTrk16Azimuth : 35|12@0- (0.125,0) [-256|255.875] "deg"  EOCM_F_FO
 SG_ FLRRTrk16Width : 55|6@0+ (0.25,0) [0|15.75] "m"  EOCM_F_FO
 SG_ FLRRTrk16MeasStatus : 7|2@0+ (1,0) [0|0] ""  EOCM_F_FO
 SG_ FLRRTrk16ObjectID : 61|6@0+ (1,0) [0|63] ""  EOCM_F_FO

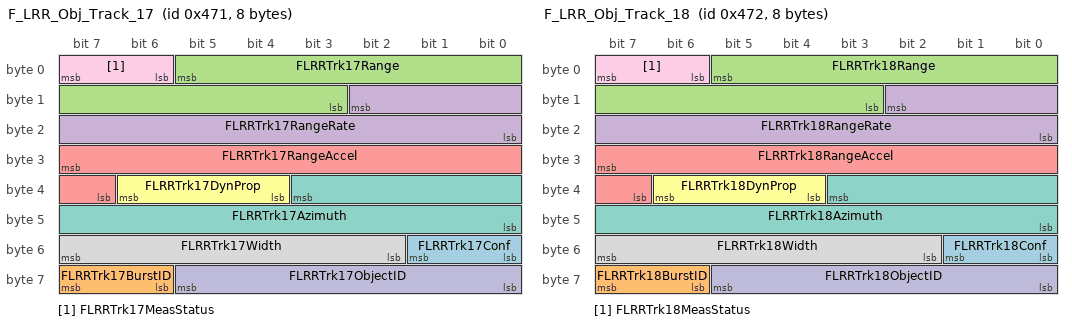
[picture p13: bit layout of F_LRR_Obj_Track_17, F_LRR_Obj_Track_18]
BO_ 1137 F_LRR_Obj_Track_17: 8 LRR_FO
 SG_ FLRRTrk17Conf : 49|2@0+ (1,0) [0|0] ""  EOCM_F_FO
 SG_ FLRRTrk17BurstID : 63|2@0+ (1,0) [0|3] ""  EOCM_F_FO
 SG_ FLRRTrk17Range : 5|11@0+ (0.125,0) [0|255.875] "m"  EOCM_F_FO
 SG_ FLRRTrk17RangeRate : 10|11@0- (0.125,0) [-128|127.875] "m/s"  EOCM_F_FO
 SG_ FLRRTrk17RangeAccel : 31|9@0- (0.125,0) [-32|31.875] "m/s^2"  EOCM_F_FO
 SG_ FLRRTrk17DynProp : 38|3@0+ (1,0) [0|0] ""  EOCM_F_FO
 SG_ FLRRTrk17Azimuth : 35|12@0- (0.125,0) [-256|255.875] "deg"  EOCM_F_FO
 SG_ FLRRTrk17Width : 55|6@0+ (0.25,0) [0|15.75] "m"  EOCM_F_FO
 SG_ FLRRTrk17MeasStatus : 7|2@0+ (1,0) [0|0] ""  EOCM_F_FO
 SG_ FLRRTrk17ObjectID : 61|6@0+ (1,0) [0|63] ""  EOCM_F_FO

BO_ 1138 F_LRR_Obj_Track_18: 8 LRR_FO
 SG_ FLRRTrk18Conf : 49|2@0+ (1,0) [0|0] ""  EOCM_F_FO
 SG_ FLRRTrk18BurstID : 63|2@0+ (1,0) [0|3] ""  EOCM_F_FO
 SG_ FLRRTrk18Range : 5|11@0+ (0.125,0) [0|255.875] "m"  EOCM_F_FO
 SG_ FLRRTrk18RangeRate : 10|11@0- (0.125,0) [-128|127.875] "m/s"  EOCM_F_FO
 SG_ FLRRTrk18RangeAccel : 31|9@0- (0.125,0) [-32|31.875] "m/s^2"  EOCM_F_FO
 SG_ FLRRTrk18DynProp : 38|3@0+ (1,0) [0|0] ""  EOCM_F_FO
 SG_ FLRRTrk18Azimuth : 35|12@0- (0.125,0) [-256|255.875] "deg"  EOCM_F_FO
 SG_ FLRRTrk18Width : 55|6@0+ (0.25,0) [0|15.75] "m"  EOCM_F_FO
 SG_ FLRRTrk18MeasStatus : 7|2@0+ (1,0) [0|0] ""  EOCM_F_FO
 SG_ FLRRTrk18ObjectID : 61|6@0+ (1,0) [0|63] ""  EOCM_F_FO

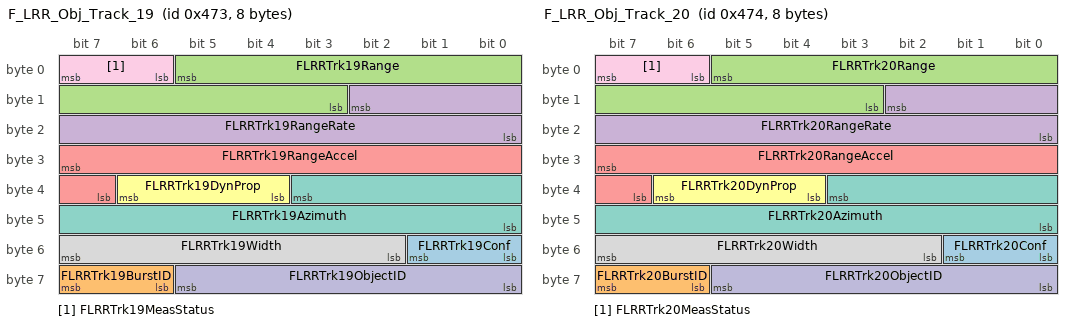
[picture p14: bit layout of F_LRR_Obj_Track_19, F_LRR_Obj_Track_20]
BO_ 1139 F_LRR_Obj_Track_19: 8 LRR_FO
 SG_ FLRRTrk19Conf : 49|2@0+ (1,0) [0|0] ""  EOCM_F_FO
 SG_ FLRRTrk19BurstID : 63|2@0+ (1,0) [0|3] ""  EOCM_F_FO
 SG_ FLRRTrk19Range : 5|11@0+ (0.125,0) [0|255.875] "m"  EOCM_F_FO
 SG_ FLRRTrk19RangeRate : 10|11@0- (0.125,0) [-128|127.875] "m/s"  EOCM_F_FO
 SG_ FLRRTrk19RangeAccel : 31|9@0- (0.125,0) [-32|31.875] "m/s^2"  EOCM_F_FO
 SG_ FLRRTrk19DynProp : 38|3@0+ (1,0) [0|0] ""  EOCM_F_FO
 SG_ FLRRTrk19Azimuth : 35|12@0- (0.125,0) [-256|255.875] "deg"  EOCM_F_FO
 SG_ FLRRTrk19Width : 55|6@0+ (0.25,0) [0|15.75] "m"  EOCM_F_FO
 SG_ FLRRTrk19MeasStatus : 7|2@0+ (1,0) [0|0] ""  EOCM_F_FO
 SG_ FLRRTrk19ObjectID : 61|6@0+ (1,0) [0|63] ""  EOCM_F_FO

BO_ 1140 F_LRR_Obj_Track_20: 8 LRR_FO
 SG_ FLRRTrk20Conf : 49|2@0+ (1,0) [0|0] ""  EOCM_F_FO
 SG_ FLRRTrk20BurstID : 63|2@0+ (1,0) [0|3] ""  EOCM_F_FO
 SG_ FLRRTrk20Range : 5|11@0+ (0.125,0) [0|255.875] "m"  EOCM_F_FO
 SG_ FLRRTrk20RangeRate : 10|11@0- (0.125,0) [-128|127.875] "m/s"  EOCM_F_FO
 SG_ FLRRTrk20RangeAccel : 31|9@0- (0.125,0) [-32|31.875] "m/s^2"  EOCM_F_FO
 SG_ FLRRTrk20DynProp : 38|3@0+ (1,0) [0|0] ""  EOCM_F_FO
 SG_ FLRRTrk20Azimuth : 35|12@0- (0.125,0) [-256|255.875] "deg"  EOCM_F_FO
 SG_ FLRRTrk20Width : 55|6@0+ (0.25,0) [0|15.75] "m"  EOCM_F_FO
 SG_ FLRRTrk20MeasStatus : 7|2@0+ (1,0) [0|0] ""  EOCM_F_FO
 SG_ FLRRTrk20ObjectID : 61|6@0+ (1,0) [0|63] ""  EOCM_F_FO

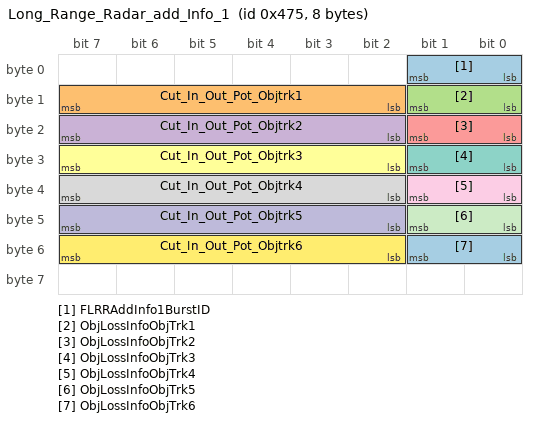
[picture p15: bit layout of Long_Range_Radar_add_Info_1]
BO_ 1141 Long_Range_Radar_add_Info_1: 8 LRR_FO
 SG_ FLRRAddInfo1BurstID : 1|2@0+ (1,0) [0|3] ""  EOCM_F_FO
 SG_ Cut_In_Out_Pot_Objtrk1 : 15|6@0+ (0.02,0) [0|1.26] ""  EOCM_F_FO
 SG_ ObjLossInfoObjTrk1 : 9|2@0+ (1,0) [0|0] ""  EOCM_F_FO
 SG_ Cut_In_Out_Pot_Objtrk2 : 23|6@0+ (0.02,0) [0|1.26] ""  EOCM_F_FO
 SG_ ObjLossInfoObjTrk2 : 17|2@0+ (1,0) [0|0] ""  EOCM_F_FO
 SG_ Cut_In_Out_Pot_Objtrk3 : 31|6@0+ (0.02,0) [0|1.26] ""  EOCM_F_FO
 SG_ ObjLossInfoObjTrk3 : 25|2@0+ (1,0) [0|0] ""  EOCM_F_FO
 SG_ Cut_In_Out_Pot_Objtrk4 : 39|6@0+ (0.02,0) [0|1.26] ""  EOCM_F_FO
 SG_ ObjLossInfoObjTrk4 : 33|2@0+ (1,0) [0|0] ""  EOCM_F_FO
 SG_ Cut_In_Out_Pot_Objtrk5 : 47|6@0+ (0.02,0) [0|1.26] ""  EOCM_F_FO
 SG_ ObjLossInfoObjTrk5 : 41|2@0+ (1,0) [0|0] ""  EOCM_F_FO
 SG_ Cut_In_Out_Pot_Objtrk6 : 55|6@0+ (0.02,0) [0|1.26] ""  EOCM_F_FO
 SG_ ObjLossInfoObjTrk6 : 49|2@0+ (1,0) [0|0] ""  EOCM_F_FO

BO_ 1321 F_Fwd_Fus_Obj_TrackB_9: 7 EOCM_F_FO
 SG_ FwdFusTrkBAnlgRlLn9 : 46|8@0- (0.1,0) [-12.8|12.7] ""  Dummy_FO
 SG_ FwdFusTrkB9RollingCnt : 7|2@0+ (1,0) [0|3] ""  Dummy_FO
 SG_ FwdFusTrkB9Width : 5|6@0+ (0.25,0) [0|15.75] "m"  Dummy_FO
 SG_ FwdFusTrkB9MsgIndex : 15|4@0+ (1,0) [0|15] ""  Dummy_FO
 SG_ FwdFusTrkB9DynProp : 11|3@0+ (1,0) [0|7] ""  Dummy_FO
 SG_ FwdFusTrkB9RelLnAccl : 8|9@0- (0.125,0) [-32|31.875] "m/s^2"  Dummy_FO
 SG_ FwdFusTrkB9RelLane : 31|2@0+ (1,0) [0|3] ""  Dummy_FO
 SG_ FwdFusTrkB9Height : 54|6@0+ (0.25,0) [0|15.75] "m"  Dummy_FO
 SG_ FFusTrkB9ObjSrcLFSrr : 29|1@0+ (1,0) [0|1] ""  Dummy_FO
 SG_ FFusTrkB9ObjSrcLCSrr : 28|1@0+ (1,0) [0|1] ""  Dummy_FO
 SG_ FFusTrkB9ObjSrcRCSrr : 27|1@0+ (1,0) [0|1] ""  Dummy_FO
 SG_ FFusTrkB9ObjSrcRFSrr : 26|1@0+ (1,0) [0|1] ""  Dummy_FO
 SG_ FFusTrkB9ObjSrcVIs : 25|1@0+ (1,0) [0|1] ""  Dummy_FO
 SG_ FwdFusTrkB9ObjSrcLrr : 24|1@0+ (1,0) [0|1] ""  Dummy_FO
 SG_ FwdFusTrkB9NmCycTrkd : 39|3@0+ (1,0) [0|7] ""  Dummy_FO
 SG_ FwdFusTrkB9LatPosDev : 36|3@0+ (1,0) [0|7] ""  Dummy_FO
 SG_ FwdFusTrkB9LngPosDev : 33|3@0+ (1,0) [0|7] ""  Dummy_FO

BO_ 1320 F_Fwd_Fus_Obj_TrackB_8: 7 EOCM_F_FO
 SG_ FwdFusTrkBAnlgRlLn8 : 46|8@0- (0.1,0) [-12.8|12.7] ""  Dummy_FO
 SG_ FwdFusTrkB8RollingCnt : 7|2@0+ (1,0) [0|3] ""  Dummy_FO
 SG_ FwdFusTrkB8Width : 5|6@0+ (0.25,0) [0|15.75] "m"  Dummy_FO
 SG_ FwdFusTrkB8MsgIndex : 15|4@0+ (1,0) [0|15] ""  Dummy_FO
 SG_ FwdFusTrkB8DynProp : 11|3@0+ (1,0) [0|7] ""  Dummy_FO
 SG_ FwdFusTrkB8RelLnAccl : 8|9@0- (0.125,0) [-32|31.875] "m/s^2"  Dummy_FO
 SG_ FwdFusTrkB8RelLane : 31|2@0+ (1,0) [0|3] ""  Dummy_FO
 SG_ FwdFusTrkB8Height : 54|6@0+ (0.25,0) [0|15.75] "m"  Dummy_FO
 SG_ FFusTrkB8ObjSrcLFSrr : 29|1@0+ (1,0) [0|1] ""  Dummy_FO
 SG_ FFusTrkB8ObjSrcLCSrr : 28|1@0+ (1,0) [0|1] ""  Dummy_FO
 SG_ FFusTrkB8ObjSrcRCSrr : 27|1@0+ (1,0) [0|1] ""  Dummy_FO
 SG_ FFusTrkB8ObjSrcRFSrr : 26|1@0+ (1,0) [0|1] ""  Dummy_FO
 SG_ FFusTrkB8ObjSrcVIs : 25|1@0+ (1,0) [0|1] ""  Dummy_FO
 SG_ FwdFusTrkB8ObjSrcLrr : 24|1@0+ (1,0) [0|1] ""  Dummy_FO
 SG_ FwdFusTrkB8NmCycTrkd : 39|3@0+ (1,0) [0|7] ""  Dummy_FO
 SG_ FwdFusTrkB8LatPosDev : 36|3@0+ (1,0) [0|7] ""  Dummy_FO
 SG_ FwdFusTrkB8LngPosDev : 33|3@0+ (1,0) [0|7] ""  Dummy_FO

BO_ 1319 F_Fwd_Fus_Obj_TrackB_7: 7 EOCM_F_FO
 SG_ FwdFusTrkBAnlgRlLn7 : 46|8@0- (0.1,0) [-12.8|12.7] ""  Dummy_FO
 SG_ FwdFusTrkB7RollingCnt : 7|2@0+ (1,0) [0|3] ""  Dummy_FO
 SG_ FwdFusTrkB7Width : 5|6@0+ (0.25,0) [0|15.75] "m"  Dummy_FO
 SG_ FwdFusTrkB7MsgIndex : 15|4@0+ (1,0) [0|15] ""  Dummy_FO
 SG_ FwdFusTrkB7DynProp : 11|3@0+ (1,0) [0|7] ""  Dummy_FO
 SG_ FwdFusTrkB7RelLnAccl : 8|9@0- (0.125,0) [-32|31.875] "m/s^2"  Dummy_FO
 SG_ FwdFusTrkB7RelLane : 31|2@0+ (1,0) [0|3] ""  Dummy_FO
 SG_ FwdFusTrkB7Height : 54|6@0+ (0.25,0) [0|15.75] "m"  Dummy_FO
 SG_ FFusTrkB7ObjSrcLFSrr : 29|1@0+ (1,0) [0|1] ""  Dummy_FO
 SG_ FFusTrkB7ObjSrcLCSrr : 28|1@0+ (1,0) [0|1] ""  Dummy_FO
 SG_ FFusTrkB7ObjSrcRCSrr : 27|1@0+ (1,0) [0|1] ""  Dummy_FO
 SG_ FFusTrkB7ObjSrcRFSrr : 26|1@0+ (1,0) [0|1] ""  Dummy_FO
 SG_ FFusTrkB7ObjSrcVIs : 25|1@0+ (1,0) [0|1] ""  Dummy_FO
 SG_ FwdFusTrkB7ObjSrcLrr : 24|1@0+ (1,0) [0|1] ""  Dummy_FO
 SG_ FwdFusTrkB7NmCycTrkd : 39|3@0+ (1,0) [0|7] ""  Dummy_FO
 SG_ FwdFusTrkB7LatPosDev : 36|3@0+ (1,0) [0|7] ""  Dummy_FO
 SG_ FwdFusTrkB7LngPosDev : 33|3@0+ (1,0) [0|7] ""  Dummy_FO

BO_ 1318 F_Fwd_Fus_Obj_TrackB_6: 7 EOCM_F_FO
 SG_ FwdFusTrkBAnlgRlLn6 : 46|8@0- (0.1,0) [-12.8|12.7] ""  Dummy_FO
 SG_ FwdFusTrkB6RollingCnt : 7|2@0+ (1,0) [0|3] ""  Dummy_FO
 SG_ FwdFusTrkB6Width : 5|6@0+ (0.25,0) [0|15.75] "m"  Dummy_FO
 SG_ FwdFusTrkB6MsgIndex : 15|4@0+ (1,0) [0|15] ""  Dummy_FO
 SG_ FwdFusTrkB6DynProp : 11|3@0+ (1,0) [0|7] ""  Dummy_FO
 SG_ FwdFusTrkB6RelLnAccl : 8|9@0- (0.125,0) [-32|31.875] "m/s^2"  Dummy_FO
 SG_ FwdFusTrkB6RelLane : 31|2@0+ (1,0) [0|3] ""  Dummy_FO
 SG_ FwdFusTrkB6Height : 54|6@0+ (0.25,0) [0|15.75] "m"  Dummy_FO
 SG_ FFusTrkB6ObjSrcLFSrr : 29|1@0+ (1,0) [0|1] ""  Dummy_FO
 SG_ FFusTrkB6ObjSrcLCSrr : 28|1@0+ (1,0) [0|1] ""  Dummy_FO
 SG_ FFusTrkB6ObjSrcRCSrr : 27|1@0+ (1,0) [0|1] ""  Dummy_FO
 SG_ FFusTrkB6ObjSrcRFSrr : 26|1@0+ (1,0) [0|1] ""  Dummy_FO
 SG_ FFusTrkB6ObjSrcVIs : 25|1@0+ (1,0) [0|1] ""  Dummy_FO
 SG_ FwdFusTrkB6ObjSrcLrr : 24|1@0+ (1,0) [0|1] ""  Dummy_FO
 SG_ FwdFusTrkB6NmCycTrkd : 39|3@0+ (1,0) [0|7] ""  Dummy_FO
 SG_ FwdFusTrkB6LatPosDev : 36|3@0+ (1,0) [0|7] ""  Dummy_FO
 SG_ FwdFusTrkB6LngPosDev : 33|3@0+ (1,0) [0|7] ""  Dummy_FO

BO_ 1317 F_Fwd_Fus_Obj_TrackB_5: 7 EOCM_F_FO
 SG_ FwdFusTrkBAnlgRlLn5 : 46|8@0- (0.1,0) [-12.8|12.7] ""  Dummy_FO
 SG_ FwdFusTrkB5RollingCnt : 7|2@0+ (1,0) [0|3] ""  Dummy_FO
 SG_ FwdFusTrkB5Width : 5|6@0+ (0.25,0) [0|15.75] "m"  Dummy_FO
 SG_ FwdFusTrkB5MsgIndex : 15|4@0+ (1,0) [0|15] ""  Dummy_FO
 SG_ FwdFusTrkB5DynProp : 11|3@0+ (1,0) [0|7] ""  Dummy_FO
 SG_ FwdFusTrkB5RelLnAccl : 8|9@0- (0.125,0) [-32|31.875] "m/s^2"  Dummy_FO
 SG_ FwdFusTrkB5RelLane : 31|2@0+ (1,0) [0|3] ""  Dummy_FO
 SG_ FwdFusTrkB5Height : 54|6@0+ (0.25,0) [0|15.75] "m"  Dummy_FO
 SG_ FFusTrkB5ObjSrcLFSrr : 29|1@0+ (1,0) [0|1] ""  Dummy_FO
 SG_ FFusTrkB5ObjSrcLCSrr : 28|1@0+ (1,0) [0|1] ""  Dummy_FO
 SG_ FFusTrkB5ObjSrcRCSrr : 27|1@0+ (1,0) [0|1] ""  Dummy_FO
 SG_ FFusTrkB5ObjSrcRFSrr : 26|1@0+ (1,0) [0|1] ""  Dummy_FO
 SG_ FFusTrkB5ObjSrcVIs : 25|1@0+ (1,0) [0|1] ""  Dummy_FO
 SG_ FwdFusTrkB5ObjSrcLrr : 24|1@0+ (1,0) [0|1] ""  Dummy_FO
 SG_ FwdFusTrkB5NmCycTrkd : 39|3@0+ (1,0) [0|7] ""  Dummy_FO
 SG_ FwdFusTrkB5LatPosDev : 36|3@0+ (1,0) [0|7] ""  Dummy_FO
 SG_ FwdFusTrkB5LngPosDev : 33|3@0+ (1,0) [0|7] ""  Dummy_FO

BO_ 1316 F_Fwd_Fus_Obj_TrackB_4: 7 EOCM_F_FO
 SG_ FwdFusTrkBAnlgRlLn4 : 46|8@0- (0.1,0) [-12.8|12.7] ""  Dummy_FO
 SG_ FwdFusTrkB4RollingCnt : 7|2@0+ (1,0) [0|3] ""  Dummy_FO
 SG_ FwdFusTrkB4Width : 5|6@0+ (0.25,0) [0|15.75] "m"  Dummy_FO
 SG_ FwdFusTrkB4MsgIndex : 15|4@0+ (1,0) [0|15] ""  Dummy_FO
 SG_ FwdFusTrkB4DynProp : 11|3@0+ (1,0) [0|7] ""  Dummy_FO
 SG_ FwdFusTrkB4RelLnAccl : 8|9@0- (0.125,0) [-32|31.875] "m/s^2"  Dummy_FO
 SG_ FwdFusTrkB4RelLane : 31|2@0+ (1,0) [0|3] ""  Dummy_FO
 SG_ FwdFusTrkB4Height : 54|6@0+ (0.25,0) [0|15.75] "m"  Dummy_FO
 SG_ FFusTrkB4ObjSrcLFSrr : 29|1@0+ (1,0) [0|1] ""  Dummy_FO
 SG_ FFusTrkB4ObjSrcLCSrr : 28|1@0+ (1,0) [0|1] ""  Dummy_FO
 SG_ FFusTrkB4ObjSrcRCSrr : 27|1@0+ (1,0) [0|1] ""  Dummy_FO
 SG_ FFusTrkB4ObjSrcRFSrr : 26|1@0+ (1,0) [0|1] ""  Dummy_FO
 SG_ FFusTrkB4ObjSrcVIs : 25|1@0+ (1,0) [0|1] ""  Dummy_FO
 SG_ FwdFusTrkB4ObjSrcLrr : 24|1@0+ (1,0) [0|1] ""  Dummy_FO
 SG_ FwdFusTrkB4NmCycTrkd : 39|3@0+ (1,0) [0|7] ""  Dummy_FO
 SG_ FwdFusTrkB4LatPosDev : 36|3@0+ (1,0) [0|7] ""  Dummy_FO
 SG_ FwdFusTrkB4LngPosDev : 33|3@0+ (1,0) [0|7] ""  Dummy_FO

BO_ 1315 F_Fwd_Fus_Obj_TrackB_3: 7 EOCM_F_FO
 SG_ FwdFusTrkBAnlgRlLn3 : 46|8@0- (0.1,0) [-12.8|12.7] ""  Dummy_FO
 SG_ FwdFusTrkB3RollingCnt : 7|2@0+ (1,0) [0|3] ""  Dummy_FO
 SG_ FwdFusTrkB3Width : 5|6@0+ (0.25,0) [0|15.75] "m"  Dummy_FO
 SG_ FwdFusTrkB3MsgIndex : 15|4@0+ (1,0) [0|15] ""  Dummy_FO
 SG_ FwdFusTrkB3DynProp : 11|3@0+ (1,0) [0|7] ""  Dummy_FO
 SG_ FwdFusTrkB3RelLnAccl : 8|9@0- (0.125,0) [-32|31.875] "m/s^2"  Dummy_FO
 SG_ FwdFusTrkB3RelLane : 31|2@0+ (1,0) [0|3] ""  Dummy_FO
 SG_ FwdFusTrkB3Height : 54|6@0+ (0.25,0) [0|15.75] "m"  Dummy_FO
 SG_ FFusTrkB3ObjSrcLFSrr : 29|1@0+ (1,0) [0|1] ""  Dummy_FO
 SG_ FFusTrkB3ObjSrcLCSrr : 28|1@0+ (1,0) [0|1] ""  Dummy_FO
 SG_ FFusTrkB3ObjSrcRCSrr : 27|1@0+ (1,0) [0|1] ""  Dummy_FO
 SG_ FFusTrkB3ObjSrcRFSrr : 26|1@0+ (1,0) [0|1] ""  Dummy_FO
 SG_ FFusTrkB3ObjSrcVIs : 25|1@0+ (1,0) [0|1] ""  Dummy_FO
 SG_ FwdFusTrkB3ObjSrcLrr : 24|1@0+ (1,0) [0|1] ""  Dummy_FO
 SG_ FwdFusTrkB3NmCycTrkd : 39|3@0+ (1,0) [0|7] ""  Dummy_FO
 SG_ FwdFusTrkB3LatPosDev : 36|3@0+ (1,0) [0|7] ""  Dummy_FO
 SG_ FwdFusTrkB3LngPosDev : 33|3@0+ (1,0) [0|7] ""  Dummy_FO

BO_ 1314 F_Fwd_Fus_Obj_TrackB_2: 7 EOCM_F_FO
 SG_ FwdFusTrkBAnlgRlLn2 : 46|8@0- (0.1,0) [-12.8|12.7] ""  Dummy_FO
 SG_ FwdFusTrkB2RollingCnt : 7|2@0+ (1,0) [0|3] ""  Dummy_FO
 SG_ FwdFusTrkB2Width : 5|6@0+ (0.25,0) [0|15.75] "m"  Dummy_FO
 SG_ FwdFusTrkB2MsgIndex : 15|4@0+ (1,0) [0|15] ""  Dummy_FO
 SG_ FwdFusTrkB2DynProp : 11|3@0+ (1,0) [0|7] ""  Dummy_FO
 SG_ FwdFusTrkB2RelLnAccl : 8|9@0- (0.125,0) [-32|31.875] "m/s^2"  Dummy_FO
 SG_ FwdFusTrkB2RelLane : 31|2@0+ (1,0) [0|3] ""  Dummy_FO
 SG_ FwdFusTrkB2Height : 54|6@0+ (0.25,0) [0|15.75] "m"  Dummy_FO
 SG_ FFusTrkB2ObjSrcLFSrr : 29|1@0+ (1,0) [0|1] ""  Dummy_FO
 SG_ FFusTrkB2ObjSrcLCSrr : 28|1@0+ (1,0) [0|1] ""  Dummy_FO
 SG_ FFusTrkB2ObjSrcRCSrr : 27|1@0+ (1,0) [0|1] ""  Dummy_FO
 SG_ FFusTrkB2ObjSrcRFSrr : 26|1@0+ (1,0) [0|1] ""  Dummy_FO
 SG_ FFusTrkB2ObjSrcVIs : 25|1@0+ (1,0) [0|1] ""  Dummy_FO
 SG_ FwdFusTrkB2ObjSrcLrr : 24|1@0+ (1,0) [0|1] ""  Dummy_FO
 SG_ FwdFusTrkB2NmCycTrkd : 39|3@0+ (1,0) [0|7] ""  Dummy_FO
 SG_ FwdFusTrkB2LatPosDev : 36|3@0+ (1,0) [0|7] ""  Dummy_FO
 SG_ FwdFusTrkB2LngPosDev : 33|3@0+ (1,0) [0|7] ""  Dummy_FO

BO_ 1327 F_Fwd_Fus_Obj_TrackB_15: 7 EOCM_F_FO
 SG_ FwdFusTrkBAnlgRlLn15 : 46|8@0- (0.1,0) [-12.8|12.7] ""  Dummy_FO
 SG_ FwdFusTrkB15RollingCnt : 7|2@0+ (1,0) [0|3] ""  Dummy_FO
 SG_ FwdFusTrkB15Width : 5|6@0+ (0.25,0) [0|15.75] "m"  Dummy_FO
 SG_ FwdFusTrkB15MsgIndex : 15|4@0+ (1,0) [0|15] ""  Dummy_FO
 SG_ FwdFusTrkB15DynProp : 11|3@0+ (1,0) [0|7] ""  Dummy_FO
 SG_ FwdFusTrkB15RelLnAccl : 8|9@0- (0.125,0) [-32|31.875] "m/s^2"  Dummy_FO
 SG_ FwdFusTrkB15RelLane : 31|2@0+ (1,0) [0|3] ""  Dummy_FO
 SG_ FwdFusTrkB15Height : 54|6@0+ (0.25,0) [0|15.75] "m"  Dummy_FO
 SG_ FFusTrkB15ObjSrcLFSrr : 29|1@0+ (1,0) [0|1] ""  Dummy_FO
 SG_ FFusTrkB15ObjSrcLCSrr : 28|1@0+ (1,0) [0|1] ""  Dummy_FO
 SG_ FFusTrkB15ObjSrcRCSrr : 27|1@0+ (1,0) [0|1] ""  Dummy_FO
 SG_ FFusTrkB15ObjSrcRFSrr : 26|1@0+ (1,0) [0|1] ""  Dummy_FO
 SG_ FFusTkB15ObjSrcVIs : 25|1@0+ (1,0) [0|1] ""  Dummy_FO
 SG_ FwdFusTrkB15ObjSrcLrr : 24|1@0+ (1,0) [0|1] ""  Dummy_FO
 SG_ FwdFusTrkB15NmCycTrkd : 39|3@0+ (1,0) [0|7] ""  Dummy_FO
 SG_ FwdFusTrkB15LatPosDev : 36|3@0+ (1,0) [0|7] ""  Dummy_FO
 SG_ FwdFusTrkB15LngPosDev : 33|3@0+ (1,0) [0|7] ""  Dummy_FO

BO_ 1326 F_Fwd_Fus_Obj_TrackB_14: 7 EOCM_F_FO
 SG_ FwdFusTrkBAnlgRlLn14 : 46|8@0- (0.1,0) [-12.8|12.7] ""  Dummy_FO
 SG_ FwdFusTrkB14RollingCnt : 7|2@0+ (1,0) [0|3] ""  Dummy_FO
 SG_ FwdFusTrkB14Width : 5|6@0+ (0.25,0) [0|15.75] "m"  Dummy_FO
 SG_ FwdFusTrkB14MsgIndex : 15|4@0+ (1,0) [0|15] ""  Dummy_FO
 SG_ FwdFusTrkB14DynProp : 11|3@0+ (1,0) [0|7] ""  Dummy_FO
 SG_ FwdFusTrkB14RelLnAccl : 8|9@0- (0.125,0) [-32|31.875] "m/s^2"  Dummy_FO
 SG_ FwdFusTrkB14RelLane : 31|2@0+ (1,0) [0|3] ""  Dummy_FO
 SG_ FwdFusTrkB14Height : 54|6@0+ (0.25,0) [0|15.75] "m"  Dummy_FO
 SG_ FFusTrkB14ObjSrcLFSrr : 29|1@0+ (1,0) [0|1] ""  Dummy_FO
 SG_ FFusTrkB14ObjSrcLCSrr : 28|1@0+ (1,0) [0|1] ""  Dummy_FO
 SG_ FFusTrkB14ObjSrcRCSrr : 27|1@0+ (1,0) [0|1] ""  Dummy_FO
 SG_ FFusTrkB14ObjSrcRFSrr : 26|1@0+ (1,0) [0|1] ""  Dummy_FO
 SG_ FFusTrkB14ObjSrcVIs : 25|1@0+ (1,0) [0|1] ""  Dummy_FO
 SG_ FwdFusTrkB14ObjSrcLrr : 24|1@0+ (1,0) [0|1] ""  Dummy_FO
 SG_ FwdFusTrkB14NmCycTrkd : 39|3@0+ (1,0) [0|7] ""  Dummy_FO
 SG_ FwdFusTrkB14LatPosDev : 36|3@0+ (1,0) [0|7] ""  Dummy_FO
 SG_ FwdFusTrkB14LngPosDev : 33|3@0+ (1,0) [0|7] ""  Dummy_FO

BO_ 1325 F_Fwd_Fus_Obj_TrackB_13: 7 EOCM_F_FO
 SG_ FwdFusTrkBAnlgRlLn13 : 46|8@0- (0.1,0) [-12.8|12.7] ""  Dummy_FO
 SG_ FwdFusTrkB13RollingCnt : 7|2@0+ (1,0) [0|3] ""  Dummy_FO
 SG_ FwdFusTrkB13Width : 5|6@0+ (0.25,0) [0|15.75] "m"  Dummy_FO
 SG_ FwdFusTrkB13MsgIndex : 15|4@0+ (1,0) [0|15] ""  Dummy_FO
 SG_ FwdFusTrkB13DynProp : 11|3@0+ (1,0) [0|7] ""  Dummy_FO
 SG_ FwdFusTrkB13RelLnAccl : 8|9@0- (0.125,0) [-32|31.875] "m/s^2"  Dummy_FO
 SG_ FwdFusTrkB13RelLane : 31|2@0+ (1,0) [0|3] ""  Dummy_FO
 SG_ FwdFusTrkB13Height : 54|6@0+ (0.25,0) [0|15.75] "m"  Dummy_FO
 SG_ FFusTrkB13ObjSrcLFSrr : 29|1@0+ (1,0) [0|1] ""  Dummy_FO
 SG_ FFusTrkB13ObjSrcLCSrr : 28|1@0+ (1,0) [0|1] ""  Dummy_FO
 SG_ FFusTrkB13ObjSrcRCSrr : 27|1@0+ (1,0) [0|1] ""  Dummy_FO
 SG_ FFusTrkB13ObjSrcRFSrr : 26|1@0+ (1,0) [0|1] ""  Dummy_FO
 SG_ FFusTrkB13ObjSrcVIs : 25|1@0+ (1,0) [0|1] ""  Dummy_FO
 SG_ FwdFusTrkB13ObjSrcLrr : 24|1@0+ (1,0) [0|1] ""  Dummy_FO
 SG_ FwdFusTrkB13NmCycTrkd : 39|3@0+ (1,0) [0|7] ""  Dummy_FO
 SG_ FwdFusTrkB13LatPosDev : 36|3@0+ (1,0) [0|7] ""  Dummy_FO
 SG_ FwdFusTrkB13LngPosDev : 33|3@0+ (1,0) [0|7] ""  Dummy_FO

BO_ 1324 F_Fwd_Fus_Obj_TrackB_12: 7 EOCM_F_FO
 SG_ FwdFusTrkBAnlgRlLn12 : 46|8@0- (0.1,0) [-12.8|12.7] ""  Dummy_FO
 SG_ FwdFusTrkB12RollingCnt : 7|2@0+ (1,0) [0|3] ""  Dummy_FO
 SG_ FwdFusTrkB12Width : 5|6@0+ (0.25,0) [0|15.75] "m"  Dummy_FO
 SG_ FwdFusTrkB12MsgIndex : 15|4@0+ (1,0) [0|15] ""  Dummy_FO
 SG_ FwdFusTrkB12DynProp : 11|3@0+ (1,0) [0|7] ""  Dummy_FO
 SG_ FwdFusTrkB12RelLnAccl : 8|9@0- (0.125,0) [-32|31.875] "m/s^2"  Dummy_FO
 SG_ FwdFusTrkB12RelLane : 31|2@0+ (1,0) [0|3] ""  Dummy_FO
 SG_ FwdFusTrkB12Height : 54|6@0+ (0.25,0) [0|15.75] "m"  Dummy_FO
 SG_ FFusTrkB12ObjSrcLFSrr : 29|1@0+ (1,0) [0|1] ""  Dummy_FO
 SG_ FFusTrkB12ObjSrcLCSrr : 28|1@0+ (1,0) [0|1] ""  Dummy_FO
 SG_ FFusTrkB12ObjSrcRCSrr : 27|1@0+ (1,0) [0|1] ""  Dummy_FO
 SG_ FFusTrkB12ObjSrcRFSrr : 26|1@0+ (1,0) [0|1] ""  Dummy_FO
 SG_ FFusTrkB12ObjSrcVIs : 25|1@0+ (1,0) [0|1] ""  Dummy_FO
 SG_ FwdFusTrkB12ObjSrcLrr : 24|1@0+ (1,0) [0|1] ""  Dummy_FO
 SG_ FwdFusTrkB12NmCycTrkd : 39|3@0+ (1,0) [0|7] ""  Dummy_FO
 SG_ FwdFusTrkB12LatPosDev : 36|3@0+ (1,0) [0|7] ""  Dummy_FO
 SG_ FwdFusTrkB12LngPosDev : 33|3@0+ (1,0) [0|7] ""  Dummy_FO

BA_DEF_ SG_  "VNSigSLHSSharedDiagnostic" ENUM  "No","Yes";
BA_DEF_ SG_  "SignalType" STRING ;
BA_DEF_ SG_  "PacketOrder" INT 0 65535;
BA_DEF_ SG_  "SignalLongName" STRING ;
BA_DEF_ SG_  "GenSigStartValue" INT 0 65535;
BA_DEF_ SG_  "VNSigAllNodes" ENUM  "No","Yes";
BA_DEF_ SG_  "GenSigSendType" ENUM  "not used","not used","not used","not used","not used","not used","not used","NoSigSendType","not used","not used","OnAnyChange","OnChangeIfActive","OnDelta";
BA_DEF_ SG_  "GenSigSendOnInit" ENUM  "Not Initialized","Application","Handler";
BA_DEF_ BO_  "GenMsgILSupport" ENUM  "No","Yes";
BA_DEF_ BO_  "TpApplType" STRING ;
BA_DEF_ BO_  "Prio" INT 0 7;
BA_DEF_ BO_  "MessageSubnet" ENUM  "LS","MS","HS","CE","PE","HV","FO";
BA_DEF_ BO_  "DiagState" ENUM  "No","Yes";
BA_DEF_ BO_  "GenMsgDelayTime" INT 0 100000;
BA_DEF_ BO_  "GenMsgCycleTime" INT 0 100000;
BA_DEF_ BO_  "GenMsgCycleTimeFast" INT 0 100000;
BA_DEF_ BO_  "GenMsgSendType" ENUM  "cyclicX","spontanX","cyclicIfActiveX","spontanWithDelay","cyclicAndSpontanX","cyclicAndSpontanWithDelay","spontanWithRepitition","cyclicIfActiveAndSpontanWD";
BA_DEF_ BO_  "DiagResponse" ENUM  "No","Yes";
BA_DEF_ BO_  "DiagRequest" ENUM  "No","Yes";
BA_DEF_ BO_  "NmMessage" ENUM  "No","Yes";
BA_DEF_REL_ BU_SG_REL_  "GenSigSuprvRespComment" STRING ;
BA_DEF_REL_ BU_SG_REL_  "GenSigVBitResp" ENUM  "No","Yes";
BA_DEF_REL_ BU_SG_REL_  "GenSigVBitRespComment" STRING ;
BA_DEF_REL_ BU_SG_REL_  "GenSigVDAFailComment" STRING ;
BA_DEF_REL_ BU_SG_REL_  "GenSigSuprvResp" ENUM  "None","Notify App","Substitute Default";
BA_DEF_REL_ BU_SG_REL_  "GenSigTimeoutMsg" HEX -2147483648 268435455;
BA_DEF_REL_ BU_SG_REL_  "GenSigTimeoutTime" INT 0 15000;
BA_DEF_DEF_  "VNSigSLHSSharedDiagnostic" "No";
BA_DEF_DEF_  "SignalType" "";
BA_DEF_DEF_  "PacketOrder" 0;
BA_DEF_DEF_  "SignalLongName" "";
BA_DEF_DEF_  "GenSigStartValue" 0;
BA_DEF_DEF_  "VNSigAllNodes" "No";
BA_DEF_DEF_  "GenSigSendType" "NoSigSendType";
BA_DEF_DEF_  "GenSigSendOnInit" "Not Initialized";
BA_DEF_DEF_  "GenMsgILSupport" "Yes";
BA_DEF_DEF_  "TpApplType" "";
BA_DEF_DEF_  "Prio" 4;
BA_DEF_DEF_  "MessageSubnet" "FO";
BA_DEF_DEF_  "DiagState" "No";
BA_DEF_DEF_  "GenMsgDelayTime" 0;
BA_DEF_DEF_  "GenMsgCycleTime" 0;
BA_DEF_DEF_  "GenMsgCycleTimeFast" 0;
BA_DEF_DEF_  "GenMsgSendType" "spontanX";
BA_DEF_DEF_  "DiagResponse" "No";
BA_DEF_DEF_  "DiagRequest" "No";
BA_DEF_DEF_  "NmMessage" "No";
BA_DEF_DEF_REL_ "GenSigSuprvRespComment" "";
BA_DEF_DEF_REL_ "GenSigVBitResp" "No";
BA_DEF_DEF_REL_ "GenSigVBitRespComment" "";
BA_DEF_DEF_REL_ "GenSigVDAFailComment" "";
BA_DEF_DEF_REL_ "GenSigSuprvResp" "None";
BA_DEF_DEF_REL_ "GenSigTimeoutMsg" 0;
BA_DEF_DEF_REL_ "GenSigTimeoutTime" 0;
BA_ "Prio" BO_ 1091 0;
BA_ "GenMsgDelayTime" BO_ 1091 55;
BA_ "Prio" BO_ 1092 0;
BA_ "GenMsgDelayTime" BO_ 1092 55;
BA_ "Prio" BO_ 1093 0;
BA_ "GenMsgDelayTime" BO_ 1093 55;
BA_ "Prio" BO_ 1094 0;
BA_ "GenMsgDelayTime" BO_ 1094 55;
BA_ "Prio" BO_ 1538 0;
BA_ "GenMsgDelayTime" BO_ 1538 10;
BA_ "Prio" BO_ 1537 0;
BA_ "GenMsgDelayTime" BO_ 1537 10;
BA_ "Prio" BO_ 1095 0;
BA_ "GenMsgDelayTime" BO_ 1095 55;
BA_ "Prio" BO_ 1096 0;
BA_ "GenMsgDelayTime" BO_ 1096 55;
BA_ "Prio" BO_ 1097 0;
BA_ "GenMsgDelayTime" BO_ 1097 55;
BA_ "Prio" BO_ 1098 0;
BA_ "GenMsgDelayTime" BO_ 1098 55;
BA_ "Prio" BO_ 1120 0;
BA_ "GenMsgDelayTime" BO_ 1120 60;
BA_ "Prio" BO_ 1121 0;
BA_ "GenMsgDelayTime" BO_ 1121 60;
BA_ "Prio" BO_ 1122 0;
BA_ "GenMsgDelayTime" BO_ 1122 60;
BA_ "Prio" BO_ 1123 0;
BA_ "GenMsgDelayTime" BO_ 1123 60;
BA_ "Prio" BO_ 1124 0;
BA_ "GenMsgDelayTime" BO_ 1124 60;
BA_ "Prio" BO_ 1125 0;
BA_ "GenMsgDelayTime" BO_ 1125 60;
BA_ "Prio" BO_ 1126 0;
BA_ "GenMsgDelayTime" BO_ 1126 60;
BA_ "Prio" BO_ 1127 0;
BA_ "GenMsgDelayTime" BO_ 1127 60;
BA_ "Prio" BO_ 1128 0;
BA_ "GenMsgDelayTime" BO_ 1128 60;
BA_ "Prio" BO_ 1129 0;
BA_ "GenMsgDelayTime" BO_ 1129 60;
BA_ "Prio" BO_ 1130 0;
BA_ "GenMsgDelayTime" BO_ 1130 60;
BA_ "Prio" BO_ 1131 0;
BA_ "GenMsgDelayTime" BO_ 1131 60;
BA_ "Prio" BO_ 1132 0;
BA_ "GenMsgDelayTime" BO_ 1132 60;
BA_ "Prio" BO_ 1133 0;
BA_ "GenMsgDelayTime" BO_ 1133 60;
BA_ "Prio" BO_ 1134 0;
BA_ "GenMsgDelayTime" BO_ 1134 60;
BA_ "Prio" BO_ 1135 0;
BA_ "GenMsgDelayTime" BO_ 1135 60;
BA_ "Prio" BO_ 1136 0;
BA_ "GenMsgDelayTime" BO_ 1136 60;
BA_ "Prio" BO_ 1137 0;
BA_ "GenMsgDelayTime" BO_ 1137 60;
BA_ "Prio" BO_ 1138 0;
BA_ "GenMsgDelayTime" BO_ 1138 60;
BA_ "Prio" BO_ 1139 0;
BA_ "GenMsgDelayTime" BO_ 1139 60;
BA_ "Prio" BO_ 1140 0;
BA_ "GenMsgDelayTime" BO_ 1140 60;
BA_ "Prio" BO_ 1141 0;
BA_ "GenMsgDelayTime" BO_ 1141 60;
BA_ "Prio" BO_ 1321 0;
BA_ "GenMsgCycleTime" BO_ 1321 80;
BA_ "GenMsgSendType" BO_ 1321 0;
BA_ "Prio" BO_ 1320 0;
BA_ "GenMsgCycleTime" BO_ 1320 80;
BA_ "GenMsgSendType" BO_ 1320 0;
BA_ "Prio" BO_ 1319 0;
BA_ "GenMsgCycleTime" BO_ 1319 80;
BA_ "GenMsgSendType" BO_ 1319 0;
BA_ "Prio" BO_ 1318 0;
BA_ "GenMsgCycleTime" BO_ 1318 80;
BA_ "GenMsgSendType" BO_ 1318 0;
BA_ "Prio" BO_ 1317 0;
BA_ "GenMsgCycleTime" BO_ 1317 80;
BA_ "GenMsgSendType" BO_ 1317 0;
BA_ "Prio" BO_ 1316 0;
BA_ "GenMsgCycleTime" BO_ 1316 80;
BA_ "GenMsgSendType" BO_ 1316 0;
BA_ "Prio" BO_ 1315 0;
BA_ "GenMsgCycleTime" BO_ 1315 80;
BA_ "GenMsgSendType" BO_ 1315 0;
BA_ "Prio" BO_ 1314 0;
BA_ "GenMsgCycleTime" BO_ 1314 80;
BA_ "GenMsgSendType" BO_ 1314 0;
BA_ "Prio" BO_ 1327 0;
BA_ "GenMsgCycleTime" BO_ 1327 80;
BA_ "GenMsgSendType" BO_ 1327 0;
BA_ "Prio" BO_ 1326 0;
BA_ "GenMsgCycleTime" BO_ 1326 80;
BA_ "GenMsgSendType" BO_ 1326 0;
BA_ "Prio" BO_ 1325 0;
BA_ "GenMsgCycleTime" BO_ 1325 80;
BA_ "GenMsgSendType" BO_ 1325 0;
BA_ "Prio" BO_ 1324 0;
BA_ "GenMsgCycleTime" BO_ 1324 80;
BA_ "GenMsgSendType" BO_ 1324 0;
BA_ "SignalType" SG_ 1091 FVisBurstIDTrk3 "UNM";
BA_ "SignalLongName" SG_ 1091 FVisBurstIDTrk3 "Front Vision Burst ID Track 3";
BA_ "VNSigAllNodes" SG_ 1091 FVisBurstIDTrk3 1;
BA_ "SignalType" SG_ 1091 FVisionObjectIDTrk3 "UNM";
BA_ "SignalLongName" SG_ 1091 FVisionObjectIDTrk3 "Forward Vision Object ID Track 3";
BA_ "VNSigAllNodes" SG_ 1091 FVisionObjectIDTrk3 1;
BA_ "SignalType" SG_ 1091 FVisionObjectTypeTrk3 "ENM";
BA_ "SignalLongName" SG_ 1091 FVisionObjectTypeTrk3 "Forward Vision Object Type Track 3";
BA_ "VNSigAllNodes" SG_ 1091 FVisionObjectTypeTrk3 1;
BA_ "SignalType" SG_ 1091 FVisionAzimuthTrk3 "SNM";
BA_ "SignalLongName" SG_ 1091 FVisionAzimuthTrk3 "Forward Vision Azimuth Track 3";
BA_ "VNSigAllNodes" SG_ 1091 FVisionAzimuthTrk3 1;
BA_ "SignalType" SG_ 1091 FVisionRangeTrk3 "UNM";
BA_ "SignalLongName" SG_ 1091 FVisionRangeTrk3 "Forward Vision Range Track 3";
BA_ "GenSigStartValue" SG_ 1091 FVisionRangeTrk3 1;
BA_ "VNSigAllNodes" SG_ 1091 FVisionRangeTrk3 1;
BA_ "SignalType" SG_ 1091 FVisionConfTrk3 "ENM";
BA_ "SignalLongName" SG_ 1091 FVisionConfTrk3 "Forward Vision Confidence Track 3";
BA_ "VNSigAllNodes" SG_ 1091 FVisionConfTrk3 1;
BA_ "SignalType" SG_ 1091 FVisionAzRateTrk3 "SNM";
BA_ "SignalLongName" SG_ 1091 FVisionAzRateTrk3 "Forward Vision Azimuth Rate Track 3";
BA_ "VNSigAllNodes" SG_ 1091 FVisionAzRateTrk3 1;
BA_ "SignalType" SG_ 1091 FVisionRelLaneTrk3 "ENM";
BA_ "SignalLongName" SG_ 1091 FVisionRelLaneTrk3 "Forward Vision Relative Lane Track 3";
BA_ "VNSigAllNodes" SG_ 1091 FVisionRelLaneTrk3 1;
BA_ "SignalType" SG_ 1091 FVisionHeightTrk3 "UNM";
BA_ "SignalLongName" SG_ 1091 FVisionHeightTrk3 "Forward Vision Height Track 3";
BA_ "GenSigStartValue" SG_ 1091 FVisionHeightTrk3 1;
BA_ "VNSigAllNodes" SG_ 1091 FVisionHeightTrk3 1;
BA_ "SignalType" SG_ 1091 FVisionMeasStatTrk3 "ENM";
BA_ "SignalLongName" SG_ 1091 FVisionMeasStatTrk3 "Forward Vision Measurement Status Track 3";
BA_ "VNSigAllNodes" SG_ 1091 FVisionMeasStatTrk3 1;
BA_ "SignalType" SG_ 1091 FVisionWidthTrk3 "UNM";
BA_ "SignalLongName" SG_ 1091 FVisionWidthTrk3 "Forward Vision Width Track 3";
BA_ "GenSigStartValue" SG_ 1091 FVisionWidthTrk3 1;
BA_ "VNSigAllNodes" SG_ 1091 FVisionWidthTrk3 1;
BA_ "SignalType" SG_ 1092 FVisionMeasStatTrk4 "ENM";
BA_ "SignalLongName" SG_ 1092 FVisionMeasStatTrk4 "Forward Vision Measurement Status Track 4";
BA_ "VNSigAllNodes" SG_ 1092 FVisionMeasStatTrk4 1;
BA_ "SignalType" SG_ 1092 FVisionWidthTrk4 "UNM";
BA_ "SignalLongName" SG_ 1092 FVisionWidthTrk4 "Forward Vision Width Track 4";
BA_ "GenSigStartValue" SG_ 1092 FVisionWidthTrk4 1;
BA_ "VNSigAllNodes" SG_ 1092 FVisionWidthTrk4 1;
BA_ "SignalType" SG_ 1092 FVisBurstIDTrk4 "UNM";
BA_ "SignalLongName" SG_ 1092 FVisBurstIDTrk4 "Front Vision Burst ID Track 4";
BA_ "VNSigAllNodes" SG_ 1092 FVisBurstIDTrk4 1;
BA_ "SignalType" SG_ 1092 FVisionObjectIDTrk4 "UNM";
BA_ "SignalLongName" SG_ 1092 FVisionObjectIDTrk4 "Forward Vision Object ID Track 4";
BA_ "VNSigAllNodes" SG_ 1092 FVisionObjectIDTrk4 1;
BA_ "SignalType" SG_ 1092 FVisionObjectTypeTrk4 "ENM";
BA_ "SignalLongName" SG_ 1092 FVisionObjectTypeTrk4 "Forward Vision Object Type Track 4";
BA_ "VNSigAllNodes" SG_ 1092 FVisionObjectTypeTrk4 1;
BA_ "SignalType" SG_ 1092 FVisionAzimuthTrk4 "SNM";
BA_ "SignalLongName" SG_ 1092 FVisionAzimuthTrk4 "Forward Vision Azimuth Track 4";
BA_ "VNSigAllNodes" SG_ 1092 FVisionAzimuthTrk4 1;
BA_ "SignalType" SG_ 1092 FVisionRangeTrk4 "UNM";
BA_ "SignalLongName" SG_ 1092 FVisionRangeTrk4 "Forward Vision Range Track 4";
BA_ "GenSigStartValue" SG_ 1092 FVisionRangeTrk4 1;
BA_ "VNSigAllNodes" SG_ 1092 FVisionRangeTrk4 1;
BA_ "SignalType" SG_ 1092 FVisionConfTrk4 "ENM";
BA_ "SignalLongName" SG_ 1092 FVisionConfTrk4 "Forward Vision Confidence Track 4";
BA_ "VNSigAllNodes" SG_ 1092 FVisionConfTrk4 1;
BA_ "SignalType" SG_ 1092 FVisionAzRateTrk4 "SNM";
BA_ "SignalLongName" SG_ 1092 FVisionAzRateTrk4 "Forward Vision Azimuth Rate Track 4";
BA_ "VNSigAllNodes" SG_ 1092 FVisionAzRateTrk4 1;
BA_ "SignalType" SG_ 1092 FVisionRelLaneTrk4 "ENM";
BA_ "SignalLongName" SG_ 1092 FVisionRelLaneTrk4 "Forward Vision Relative Lane Track 4";
BA_ "VNSigAllNodes" SG_ 1092 FVisionRelLaneTrk4 1;
BA_ "SignalType" SG_ 1092 FVisionHeightTrk4 "UNM";
BA_ "SignalLongName" SG_ 1092 FVisionHeightTrk4 "Forward Vision Height Track 4";
BA_ "GenSigStartValue" SG_ 1092 FVisionHeightTrk4 1;
BA_ "VNSigAllNodes" SG_ 1092 FVisionHeightTrk4 1;
BA_ "SignalType" SG_ 1093 FVisBurstIDTrk5 "UNM";
BA_ "SignalLongName" SG_ 1093 FVisBurstIDTrk5 "Front Vision Burst ID Track 5";
BA_ "VNSigAllNodes" SG_ 1093 FVisBurstIDTrk5 1;
BA_ "SignalType" SG_ 1093 FVisionObjectIDTrk5 "UNM";
BA_ "SignalLongName" SG_ 1093 FVisionObjectIDTrk5 "Forward Vision Object ID Track 5";
BA_ "VNSigAllNodes" SG_ 1093 FVisionObjectIDTrk5 1;
BA_ "SignalType" SG_ 1093 FVisionObjectTypeTrk5 "ENM";
BA_ "SignalLongName" SG_ 1093 FVisionObjectTypeTrk5 "Forward Vision Object Type Track 5";
BA_ "VNSigAllNodes" SG_ 1093 FVisionObjectTypeTrk5 1;
BA_ "SignalType" SG_ 1093 FVisionAzimuthTrk5 "SNM";
BA_ "SignalLongName" SG_ 1093 FVisionAzimuthTrk5 "Forward Vision Azimuth Track 5";
BA_ "VNSigAllNodes" SG_ 1093 FVisionAzimuthTrk5 1;
BA_ "SignalType" SG_ 1093 FVisionRangeTrk5 "UNM";
BA_ "SignalLongName" SG_ 1093 FVisionRangeTrk5 "Forward Vision Range Track 5";
BA_ "GenSigStartValue" SG_ 1093 FVisionRangeTrk5 1;
BA_ "VNSigAllNodes" SG_ 1093 FVisionRangeTrk5 1;
BA_ "SignalType" SG_ 1093 FVisionConfTrk5 "ENM";
BA_ "SignalLongName" SG_ 1093 FVisionConfTrk5 "Forward Vision Confidence Track 5";
BA_ "VNSigAllNodes" SG_ 1093 FVisionConfTrk5 1;
BA_ "SignalType" SG_ 1093 FVisionAzRateTrk5 "SNM";
BA_ "SignalLongName" SG_ 1093 FVisionAzRateTrk5 "Forward Vision Azimuth Rate Track 5";
BA_ "VNSigAllNodes" SG_ 1093 FVisionAzRateTrk5 1;
BA_ "SignalType" SG_ 1093 FVisionRelLaneTrk5 "ENM";
BA_ "SignalLongName" SG_ 1093 FVisionRelLaneTrk5 "Forward Vision Relative Lane Track 5";
BA_ "VNSigAllNodes" SG_ 1093 FVisionRelLaneTrk5 1;
BA_ "SignalType" SG_ 1093 FVisionHeightTrk5 "UNM";
BA_ "SignalLongName" SG_ 1093 FVisionHeightTrk5 "Forward Vision Height Track 5";
BA_ "GenSigStartValue" SG_ 1093 FVisionHeightTrk5 1;
BA_ "VNSigAllNodes" SG_ 1093 FVisionHeightTrk5 1;
BA_ "SignalType" SG_ 1093 FVisionMeasStatTrk5 "ENM";
BA_ "SignalLongName" SG_ 1093 FVisionMeasStatTrk5 "Forward Vision Measurement Status Track 5";
BA_ "VNSigAllNodes" SG_ 1093 FVisionMeasStatTrk5 1;
BA_ "SignalType" SG_ 1093 FVisionWidthTrk5 "UNM";
BA_ "SignalLongName" SG_ 1093 FVisionWidthTrk5 "Forward Vision Width Track 5";
BA_ "GenSigStartValue" SG_ 1093 FVisionWidthTrk5 1;
BA_ "VNSigAllNodes" SG_ 1093 FVisionWidthTrk5 1;
BA_ "SignalType" SG_ 1094 FVisBurstIDTrk6 "UNM";
BA_ "SignalLongName" SG_ 1094 FVisBurstIDTrk6 "Front Vision Burst ID Track 6";
BA_ "VNSigAllNodes" SG_ 1094 FVisBurstIDTrk6 1;
BA_ "SignalType" SG_ 1094 FVisionObjectIDTrk6 "UNM";
BA_ "SignalLongName" SG_ 1094 FVisionObjectIDTrk6 "Forward Vision Object ID Track 6";
BA_ "VNSigAllNodes" SG_ 1094 FVisionObjectIDTrk6 1;
BA_ "SignalType" SG_ 1094 FVisionObjectTypeTrk6 "ENM";
BA_ "SignalLongName" SG_ 1094 FVisionObjectTypeTrk6 "Forward Vision Object Type Track 6";
BA_ "VNSigAllNodes" SG_ 1094 FVisionObjectTypeTrk6 1;
BA_ "SignalType" SG_ 1094 FVisionAzimuthTrk6 "SNM";
BA_ "SignalLongName" SG_ 1094 FVisionAzimuthTrk6 "Forward Vision Azimuth Track 6";
BA_ "VNSigAllNodes" SG_ 1094 FVisionAzimuthTrk6 1;
BA_ "SignalType" SG_ 1094 FVisionRangeTrk6 "UNM";
BA_ "SignalLongName" SG_ 1094 FVisionRangeTrk6 "Forward Vision Range Track 6";
BA_ "GenSigStartValue" SG_ 1094 FVisionRangeTrk6 1;
BA_ "VNSigAllNodes" SG_ 1094 FVisionRangeTrk6 1;
BA_ "SignalType" SG_ 1094 FVisionConfTrk6 "ENM";
BA_ "SignalLongName" SG_ 1094 FVisionConfTrk6 "Forward Vision Confidence Track 6";
BA_ "VNSigAllNodes" SG_ 1094 FVisionConfTrk6 1;
BA_ "SignalType" SG_ 1094 FVisionAzRateTrk6 "SNM";
BA_ "SignalLongName" SG_ 1094 FVisionAzRateTrk6 "Forward Vision Azimuth Rate Track 6";
BA_ "VNSigAllNodes" SG_ 1094 FVisionAzRateTrk6 1;
BA_ "SignalType" SG_ 1094 FVisionRelLaneTrk6 "ENM";
BA_ "SignalLongName" SG_ 1094 FVisionRelLaneTrk6 "Forward Vision Relative Lane Track 6";
BA_ "VNSigAllNodes" SG_ 1094 FVisionRelLaneTrk6 1;
BA_ "SignalType" SG_ 1094 FVisionHeightTrk6 "UNM";
BA_ "SignalLongName" SG_ 1094 FVisionHeightTrk6 "Forward Vision Height Track 6";
BA_ "GenSigStartValue" SG_ 1094 FVisionHeightTrk6 1;
BA_ "VNSigAllNodes" SG_ 1094 FVisionHeightTrk6 1;
BA_ "SignalType" SG_ 1094 FVisionMeasStatTrk6 "ENM";
BA_ "SignalLongName" SG_ 1094 FVisionMeasStatTrk6 "Forward Vision Measurement Status Track 6";
BA_ "VNSigAllNodes" SG_ 1094 FVisionMeasStatTrk6 1;
BA_ "SignalType" SG_ 1094 FVisionWidthTrk6 "UNM";
BA_ "SignalLongName" SG_ 1094 FVisionWidthTrk6 "Forward Vision Width Track 6";
BA_ "GenSigStartValue" SG_ 1094 FVisionWidthTrk6 1;
BA_ "VNSigAllNodes" SG_ 1094 FVisionWidthTrk6 1;
BA_ "GenSigSendType" SG_ 1538 LFSRRYear 10;
BA_ "SignalType" SG_ 1538 LFSRRYear "ASC";
BA_ "SignalLongName" SG_ 1538 LFSRRYear "Left Front Short Range Radar Year";
BA_ "VNSigAllNodes" SG_ 1538 LFSRRYear 1;
BA_ "GenSigSendType" SG_ 1538 LFSRRSerialNmbr 10;
BA_ "SignalType" SG_ 1538 LFSRRSerialNmbr "ASC";
BA_ "SignalLongName" SG_ 1538 LFSRRSerialNmbr "Left Front Short Range Radar Serial Number";
BA_ "VNSigAllNodes" SG_ 1538 LFSRRSerialNmbr 1;
BA_ "GenSigSendType" SG_ 1538 LFSRRJulianDate 10;
BA_ "SignalType" SG_ 1538 LFSRRJulianDate "ASC";
BA_ "SignalLongName" SG_ 1538 LFSRRJulianDate "Left Front Short Range Radar Julian Date";
BA_ "VNSigAllNodes" SG_ 1538 LFSRRJulianDate 1;
BA_ "GenSigSendType" SG_ 1537 RSRRYear 10;
BA_ "SignalType" SG_ 1537 RSRRYear "ASC";
BA_ "SignalLongName" SG_ 1537 RSRRYear "Rear Short Range Radar Year";
BA_ "VNSigAllNodes" SG_ 1537 RSRRYear 1;
BA_ "GenSigSendType" SG_ 1537 RSRRSerialNmbr 10;
BA_ "SignalType" SG_ 1537 RSRRSerialNmbr "ASC";
BA_ "SignalLongName" SG_ 1537 RSRRSerialNmbr "Rear Short Range Radar Serial Number";
BA_ "VNSigAllNodes" SG_ 1537 RSRRSerialNmbr 1;
BA_ "GenSigSendType" SG_ 1537 RSRRJulianDate 10;
BA_ "SignalType" SG_ 1537 RSRRJulianDate "ASC";
BA_ "SignalLongName" SG_ 1537 RSRRJulianDate "Rear Short Range Radar Julian Date";
BA_ "VNSigAllNodes" SG_ 1537 RSRRJulianDate 1;
BA_ "SignalType" SG_ 1095 FVisBurstIDTrk7 "UNM";
BA_ "SignalLongName" SG_ 1095 FVisBurstIDTrk7 "Front Vision Burst ID Track 7";
BA_ "VNSigAllNodes" SG_ 1095 FVisBurstIDTrk7 1;
BA_ "SignalType" SG_ 1095 FVisionObjectIDTrk7 "UNM";
BA_ "SignalLongName" SG_ 1095 FVisionObjectIDTrk7 "Forward Vision Object ID Track 7";
BA_ "VNSigAllNodes" SG_ 1095 FVisionObjectIDTrk7 1;
BA_ "SignalType" SG_ 1095 FVisionObjectTypeTrk7 "ENM";
BA_ "SignalLongName" SG_ 1095 FVisionObjectTypeTrk7 "Forward Vision Object Type Track 7";
BA_ "VNSigAllNodes" SG_ 1095 FVisionObjectTypeTrk7 1;
BA_ "SignalType" SG_ 1095 FVisionAzimuthTrk7 "SNM";
BA_ "SignalLongName" SG_ 1095 FVisionAzimuthTrk7 "Forward Vision Azimuth Track 7";
BA_ "VNSigAllNodes" SG_ 1095 FVisionAzimuthTrk7 1;
BA_ "SignalType" SG_ 1095 FVisionRangeTrk7 "UNM";
BA_ "SignalLongName" SG_ 1095 FVisionRangeTrk7 "Forward Vision Range Track 7";
BA_ "GenSigStartValue" SG_ 1095 FVisionRangeTrk7 1;
BA_ "VNSigAllNodes" SG_ 1095 FVisionRangeTrk7 1;
BA_ "SignalType" SG_ 1095 FVisionConfTrk7 "ENM";
BA_ "SignalLongName" SG_ 1095 FVisionConfTrk7 "Forward Vision Confidence Track 7";
BA_ "VNSigAllNodes" SG_ 1095 FVisionConfTrk7 1;
BA_ "SignalType" SG_ 1095 FVisionAzRateTrk7 "SNM";
BA_ "SignalLongName" SG_ 1095 FVisionAzRateTrk7 "Forward Vision Azimuth Rate Track 7";
BA_ "VNSigAllNodes" SG_ 1095 FVisionAzRateTrk7 1;
BA_ "SignalType" SG_ 1095 FVisionRelLaneTrk7 "ENM";
BA_ "SignalLongName" SG_ 1095 FVisionRelLaneTrk7 "Forward Vision Relative Lane Track 7";
BA_ "VNSigAllNodes" SG_ 1095 FVisionRelLaneTrk7 1;
BA_ "SignalType" SG_ 1095 FVisionHeightTrk7 "UNM";
BA_ "SignalLongName" SG_ 1095 FVisionHeightTrk7 "Forward Vision Height Track 7";
BA_ "GenSigStartValue" SG_ 1095 FVisionHeightTrk7 1;
BA_ "VNSigAllNodes" SG_ 1095 FVisionHeightTrk7 1;
BA_ "SignalType" SG_ 1095 FVisionMeasStatTrk7 "ENM";
BA_ "SignalLongName" SG_ 1095 FVisionMeasStatTrk7 "Forward Vision Measurement Status Track 7";
BA_ "VNSigAllNodes" SG_ 1095 FVisionMeasStatTrk7 1;
BA_ "SignalType" SG_ 1095 FVisionWidthTrk7 "UNM";
BA_ "SignalLongName" SG_ 1095 FVisionWidthTrk7 "Forward Vision Width Track 7";
BA_ "GenSigStartValue" SG_ 1095 FVisionWidthTrk7 1;
BA_ "VNSigAllNodes" SG_ 1095 FVisionWidthTrk7 1;
BA_ "SignalType" SG_ 1096 FVisBurstIDTrk8 "UNM";
BA_ "SignalLongName" SG_ 1096 FVisBurstIDTrk8 "Front Vision Burst ID Track 8";
BA_ "VNSigAllNodes" SG_ 1096 FVisBurstIDTrk8 1;
BA_ "SignalType" SG_ 1096 FVisionObjectIDTrk8 "UNM";
BA_ "SignalLongName" SG_ 1096 FVisionObjectIDTrk8 "Forward Vision Object ID Track 8";
BA_ "VNSigAllNodes" SG_ 1096 FVisionObjectIDTrk8 1;
BA_ "SignalType" SG_ 1096 FVisionObjectTypeTrk8 "ENM";
BA_ "SignalLongName" SG_ 1096 FVisionObjectTypeTrk8 "Forward Vision Object Type Track 8";
BA_ "VNSigAllNodes" SG_ 1096 FVisionObjectTypeTrk8 1;
BA_ "SignalType" SG_ 1096 FVisionAzimuthTrk8 "SNM";
BA_ "SignalLongName" SG_ 1096 FVisionAzimuthTrk8 "Forward Vision Azimuth Track 8";
BA_ "VNSigAllNodes" SG_ 1096 FVisionAzimuthTrk8 1;
BA_ "SignalType" SG_ 1096 FVisionRangeTrk8 "UNM";
BA_ "SignalLongName" SG_ 1096 FVisionRangeTrk8 "Forward Vision Range Track 8";
BA_ "GenSigStartValue" SG_ 1096 FVisionRangeTrk8 1;
BA_ "VNSigAllNodes" SG_ 1096 FVisionRangeTrk8 1;
BA_ "SignalType" SG_ 1096 FVisionConfTrk8 "ENM";
BA_ "SignalLongName" SG_ 1096 FVisionConfTrk8 "Forward Vision Confidence Track 8";
BA_ "VNSigAllNodes" SG_ 1096 FVisionConfTrk8 1;
BA_ "SignalType" SG_ 1096 FVisionAzRateTrk8 "SNM";
BA_ "SignalLongName" SG_ 1096 FVisionAzRateTrk8 "Forward Vision Azimuth Rate Track 8";
BA_ "VNSigAllNodes" SG_ 1096 FVisionAzRateTrk8 1;
BA_ "SignalType" SG_ 1096 FVisionRelLaneTrk8 "ENM";
BA_ "SignalLongName" SG_ 1096 FVisionRelLaneTrk8 "Forward Vision Relative Lane Track 8";
BA_ "VNSigAllNodes" SG_ 1096 FVisionRelLaneTrk8 1;
BA_ "SignalType" SG_ 1096 FVisionHeightTrk8 "UNM";
BA_ "SignalLongName" SG_ 1096 FVisionHeightTrk8 "Forward Vision Height Track 8";
BA_ "GenSigStartValue" SG_ 1096 FVisionHeightTrk8 1;
BA_ "VNSigAllNodes" SG_ 1096 FVisionHeightTrk8 1;
BA_ "SignalType" SG_ 1096 FVisionMeasStatTrk8 "ENM";
BA_ "SignalLongName" SG_ 1096 FVisionMeasStatTrk8 "Forward Vision Measurement Status Track 8";
BA_ "VNSigAllNodes" SG_ 1096 FVisionMeasStatTrk8 1;
BA_ "SignalType" SG_ 1096 FVisionWidthTrk8 "UNM";
BA_ "SignalLongName" SG_ 1096 FVisionWidthTrk8 "Forward Vision Width Track 8";
BA_ "GenSigStartValue" SG_ 1096 FVisionWidthTrk8 1;
BA_ "VNSigAllNodes" SG_ 1096 FVisionWidthTrk8 1;
BA_ "SignalType" SG_ 1097 FVisBurstIDTrk9 "UNM";
BA_ "SignalLongName" SG_ 1097 FVisBurstIDTrk9 "Front Vision Burst ID Track 9";
BA_ "VNSigAllNodes" SG_ 1097 FVisBurstIDTrk9 1;
BA_ "SignalType" SG_ 1097 FVisionObjectIDTrk9 "UNM";
BA_ "SignalLongName" SG_ 1097 FVisionObjectIDTrk9 "Forward Vision Object ID Track 9";
BA_ "VNSigAllNodes" SG_ 1097 FVisionObjectIDTrk9 1;
BA_ "SignalType" SG_ 1097 FVisionObjectTypeTrk9 "ENM";
BA_ "SignalLongName" SG_ 1097 FVisionObjectTypeTrk9 "Forward Vision Object Type Track 9";
BA_ "VNSigAllNodes" SG_ 1097 FVisionObjectTypeTrk9 1;
BA_ "SignalType" SG_ 1097 FVisionAzimuthTrk9 "SNM";
BA_ "SignalLongName" SG_ 1097 FVisionAzimuthTrk9 "Forward Vision Azimuth Track 9";
BA_ "VNSigAllNodes" SG_ 1097 FVisionAzimuthTrk9 1;
BA_ "SignalType" SG_ 1097 FVisionRangeTrk9 "UNM";
BA_ "SignalLongName" SG_ 1097 FVisionRangeTrk9 "Forward Vision Range Track 9";
BA_ "GenSigStartValue" SG_ 1097 FVisionRangeTrk9 1;
BA_ "VNSigAllNodes" SG_ 1097 FVisionRangeTrk9 1;
BA_ "SignalType" SG_ 1097 FVisionConfTrk9 "ENM";
BA_ "SignalLongName" SG_ 1097 FVisionConfTrk9 "Forward Vision Confidence Track 9";
BA_ "VNSigAllNodes" SG_ 1097 FVisionConfTrk9 1;
BA_ "SignalType" SG_ 1097 FVisionAzRateTrk9 "SNM";
BA_ "SignalLongName" SG_ 1097 FVisionAzRateTrk9 "Forward Vision Azimuth Rate Track 9";
BA_ "VNSigAllNodes" SG_ 1097 FVisionAzRateTrk9 1;
BA_ "SignalType" SG_ 1097 FVisionRelLaneTrk9 "ENM";
BA_ "SignalLongName" SG_ 1097 FVisionRelLaneTrk9 "Forward Vision Relative Lane Track 9";
BA_ "VNSigAllNodes" SG_ 1097 FVisionRelLaneTrk9 1;
BA_ "SignalType" SG_ 1097 FVisionHeightTrk9 "UNM";
BA_ "SignalLongName" SG_ 1097 FVisionHeightTrk9 "Forward Vision Height Track 9";
BA_ "GenSigStartValue" SG_ 1097 FVisionHeightTrk9 1;
BA_ "VNSigAllNodes" SG_ 1097 FVisionHeightTrk9 1;
BA_ "SignalType" SG_ 1097 FVisionMeasStatTrk9 "ENM";
BA_ "SignalLongName" SG_ 1097 FVisionMeasStatTrk9 "Forward Vision Measurement Status Track 9";
BA_ "VNSigAllNodes" SG_ 1097 FVisionMeasStatTrk9 1;
BA_ "SignalType" SG_ 1097 FVisionWidthTrk9 "UNM";
BA_ "SignalLongName" SG_ 1097 FVisionWidthTrk9 "Forward Vision Width Track 9";
BA_ "GenSigStartValue" SG_ 1097 FVisionWidthTrk9 1;
BA_ "VNSigAllNodes" SG_ 1097 FVisionWidthTrk9 1;
BA_ "SignalType" SG_ 1098 FVisBurstIDTrk10 "UNM";
BA_ "SignalLongName" SG_ 1098 FVisBurstIDTrk10 "Front Vision Burst ID Track 10";
BA_ "VNSigAllNodes" SG_ 1098 FVisBurstIDTrk10 1;
BA_ "SignalType" SG_ 1098 FVisionObjectIDTrk10 "UNM";
BA_ "SignalLongName" SG_ 1098 FVisionObjectIDTrk10 "Forward Vision Object ID Track 10";
BA_ "VNSigAllNodes" SG_ 1098 FVisionObjectIDTrk10 1;
BA_ "SignalType" SG_ 1098 FVisionObjectTypeTrk10 "ENM";
BA_ "SignalLongName" SG_ 1098 FVisionObjectTypeTrk10 "Forward Vision Object Type Track 10";
BA_ "VNSigAllNodes" SG_ 1098 FVisionObjectTypeTrk10 1;
BA_ "SignalType" SG_ 1098 FVisionAzimuthTrk10 "SNM";
BA_ "SignalLongName" SG_ 1098 FVisionAzimuthTrk10 "Forward Vision Azimuth Track 10";
BA_ "VNSigAllNodes" SG_ 1098 FVisionAzimuthTrk10 1;
BA_ "SignalType" SG_ 1098 FVisionRangeTrk10 "UNM";
BA_ "SignalLongName" SG_ 1098 FVisionRangeTrk10 "Forward Vision Range Track 10";
BA_ "GenSigStartValue" SG_ 1098 FVisionRangeTrk10 1;
BA_ "VNSigAllNodes" SG_ 1098 FVisionRangeTrk10 1;
BA_ "SignalType" SG_ 1098 FVisionConfTrk10 "ENM";
BA_ "SignalLongName" SG_ 1098 FVisionConfTrk10 "Forward Vision Confidence Track 10";
BA_ "VNSigAllNodes" SG_ 1098 FVisionConfTrk10 1;
BA_ "SignalType" SG_ 1098 FVisionAzRateTrk10 "SNM";
BA_ "SignalLongName" SG_ 1098 FVisionAzRateTrk10 "Forward Vision Azimuth Rate Track 10";
BA_ "VNSigAllNodes" SG_ 1098 FVisionAzRateTrk10 1;
BA_ "SignalType" SG_ 1098 FVisionRelLaneTrk10 "ENM";
BA_ "SignalLongName" SG_ 1098 FVisionRelLaneTrk10 "Forward Vision Relative Lane Track 10";
BA_ "VNSigAllNodes" SG_ 1098 FVisionRelLaneTrk10 1;
BA_ "SignalType" SG_ 1098 FVisionHeightTrk10 "UNM";
BA_ "SignalLongName" SG_ 1098 FVisionHeightTrk10 "Forward Vision Height Track 10";
BA_ "GenSigStartValue" SG_ 1098 FVisionHeightTrk10 1;
BA_ "VNSigAllNodes" SG_ 1098 FVisionHeightTrk10 1;
BA_ "SignalType" SG_ 1098 FVisionMeasStatTrk10 "ENM";
BA_ "SignalLongName" SG_ 1098 FVisionMeasStatTrk10 "Forward Vision Measurement Status Track 10";
BA_ "VNSigAllNodes" SG_ 1098 FVisionMeasStatTrk10 1;
BA_ "SignalType" SG_ 1098 FVisionWidthTrk10 "UNM";
BA_ "SignalLongName" SG_ 1098 FVisionWidthTrk10 "Forward Vision Width Track 10";
BA_ "GenSigStartValue" SG_ 1098 FVisionWidthTrk10 1;
BA_ "VNSigAllNodes" SG_ 1098 FVisionWidthTrk10 1;
BA_ "SignalType" SG_ 1120 FLRRRollingCount "UNM";
BA_ "SignalLongName" SG_ 1120 FLRRRollingCount "Front Long Range Radar Rolling Count";
BA_ "VNSigAllNodes" SG_ 1120 FLRRRollingCount 1;
BA_ "SignalType" SG_ 1120 FLRRModeCmdFdbk "ENM";
BA_ "SignalLongName" SG_ 1120 FLRRModeCmdFdbk "Front Long Range Radar Sensor Mode Comand Status";
BA_ "VNSigAllNodes" SG_ 1120 FLRRModeCmdFdbk 1;
BA_ "SignalType" SG_ 1120 FLRRNumValidTargets "UNM";
BA_ "SignalLongName" SG_ 1120 FLRRNumValidTargets "Front Long Range Radar Number of Valid Targets";
BA_ "VNSigAllNodes" SG_ 1120 FLRRNumValidTargets 1;
BA_ "SignalType" SG_ 1120 FLRRTimeStampV "ENM";
BA_ "SignalLongName" SG_ 1120 FLRRTimeStampV "Front Long Range Radar Time Stamp Validity";
BA_ "VNSigAllNodes" SG_ 1120 FLRRTimeStampV 1;
BA_ "SignalType" SG_ 1120 FLRRTimeStamp "UNM";
BA_ "SignalLongName" SG_ 1120 FLRRTimeStamp "Front Long Range Radar Time Stamp";
BA_ "VNSigAllNodes" SG_ 1120 FLRRTimeStamp 1;
BA_ "SignalType" SG_ 1120 FLRRRoadTypeInfo "ENM";
BA_ "SignalLongName" SG_ 1120 FLRRRoadTypeInfo "Front Long Range Radar Road type information";
BA_ "VNSigAllNodes" SG_ 1120 FLRRRoadTypeInfo 1;
BA_ "SignalType" SG_ 1120 FLRRBurstChecksum "UNM";
BA_ "SignalLongName" SG_ 1120 FLRRBurstChecksum "Front Long Range Radar Burst Checksum";
BA_ "VNSigAllNodes" SG_ 1120 FLRRBurstChecksum 1;
BA_ "SignalType" SG_ 1120 FLRRDiagSpare "BLN";
BA_ "SignalLongName" SG_ 1120 FLRRDiagSpare "Front Long Range Radar Diagnostic Spare";
BA_ "VNSigAllNodes" SG_ 1120 FLRRDiagSpare 1;
BA_ "SignalType" SG_ 1120 FLRRVltgOutRngLo "BLN";
BA_ "SignalLongName" SG_ 1120 FLRRVltgOutRngLo "Front Long Range Radar Voltage Out Of Range Low";
BA_ "VNSigAllNodes" SG_ 1120 FLRRVltgOutRngLo 1;
BA_ "SignalType" SG_ 1120 FLRRVltgOutRngHi "BLN";
BA_ "SignalLongName" SG_ 1120 FLRRVltgOutRngHi "Front Long Range Radar Voltage out of Range High";
BA_ "VNSigAllNodes" SG_ 1120 FLRRVltgOutRngHi 1;
BA_ "SignalType" SG_ 1120 FLRRSvcAlgnInPrcs "BLN";
BA_ "SignalLongName" SG_ 1120 FLRRSvcAlgnInPrcs "Front Long Range Radar Service Alignment in Process";
BA_ "VNSigAllNodes" SG_ 1120 FLRRSvcAlgnInPrcs 1;
BA_ "SignalType" SG_ 1120 FLRRSnsrBlckd "BLN";
BA_ "SignalLongName" SG_ 1120 FLRRSnsrBlckd "Front Long Range Radar Sensor Blocked";
BA_ "VNSigAllNodes" SG_ 1120 FLRRSnsrBlckd 1;
BA_ "SignalType" SG_ 1120 FLRRSnstvFltPrsntInt "BLN";
BA_ "SignalLongName" SG_ 1120 FLRRSnstvFltPrsntInt "Front Long Range Radar Sensitivity Fault Present, Internal";
BA_ "VNSigAllNodes" SG_ 1120 FLRRSnstvFltPrsntInt 1;
BA_ "SignalType" SG_ 1120 FLRRPlntAlgnInProc "BLN";
BA_ "SignalLongName" SG_ 1120 FLRRPlntAlgnInProc "Front Long Range Radar Plant Alignment in Process";
BA_ "VNSigAllNodes" SG_ 1120 FLRRPlntAlgnInProc 1;
BA_ "SignalType" SG_ 1120 FLRRMsalgnYawRt "BLN";
BA_ "SignalLongName" SG_ 1120 FLRRMsalgnYawRt "Front Long Range Radar Misalignment Yaw Right";
BA_ "VNSigAllNodes" SG_ 1120 FLRRMsalgnYawRt 1;
BA_ "SignalType" SG_ 1120 FLRRMsalgnYawLt "BLN";
BA_ "SignalLongName" SG_ 1120 FLRRMsalgnYawLt "Front Long Range Radar Misalignment Yaw Left";
BA_ "VNSigAllNodes" SG_ 1120 FLRRMsalgnYawLt 1;
BA_ "SignalType" SG_ 1120 FLRRMsalgnRllRt "BLN";
BA_ "SignalLongName" SG_ 1120 FLRRMsalgnRllRt "Front Long Range Radar Misalignment Roll Right";
BA_ "VNSigAllNodes" SG_ 1120 FLRRMsalgnRllRt 1;
BA_ "SignalType" SG_ 1120 FLRRMsalgnRllLt "BLN";
BA_ "SignalLongName" SG_ 1120 FLRRMsalgnRllLt "Front Long Range Radar Misalignment Roll Left";
BA_ "VNSigAllNodes" SG_ 1120 FLRRMsalgnRllLt 1;
BA_ "SignalType" SG_ 1120 FLRRMsalgnPtchUp "BLN";
BA_ "SignalLongName" SG_ 1120 FLRRMsalgnPtchUp "Front Long Range Radar Misalignment Pitch Up";
BA_ "VNSigAllNodes" SG_ 1120 FLRRMsalgnPtchUp 1;
BA_ "SignalType" SG_ 1120 FLRRMsalgnPtchDn "BLN";
BA_ "SignalLongName" SG_ 1120 FLRRMsalgnPtchDn "Front Long Range Radar Misalignment Pitch Down";
BA_ "VNSigAllNodes" SG_ 1120 FLRRMsalgnPtchDn 1;
BA_ "SignalType" SG_ 1120 FLRRInitDiagCmplt "BLN";
BA_ "SignalLongName" SG_ 1120 FLRRInitDiagCmplt "Front Long Range Radar Initialization Diagnostics Successfully Completed";
BA_ "VNSigAllNodes" SG_ 1120 FLRRInitDiagCmplt 1;
BA_ "SignalType" SG_ 1120 FLRRHWFltPrsntInt "BLN";
BA_ "SignalLongName" SG_ 1120 FLRRHWFltPrsntInt "Front Long Range Radar Hardware Fault Present, Internal";
BA_ "VNSigAllNodes" SG_ 1120 FLRRHWFltPrsntInt 1;
BA_ "SignalType" SG_ 1120 FLRRExtIntrfrnc "BLN";
BA_ "SignalLongName" SG_ 1120 FLRRExtIntrfrnc "Front Long Range Radar External Interference";
BA_ "VNSigAllNodes" SG_ 1120 FLRRExtIntrfrnc 1;
BA_ "SignalType" SG_ 1120 FLRRCANSgnlSpvFld "BLN";
BA_ "SignalLongName" SG_ 1120 FLRRCANSgnlSpvFld "Front Long Range Radar CAN Signal Supervision Failed";
BA_ "VNSigAllNodes" SG_ 1120 FLRRCANSgnlSpvFld 1;
BA_ "SignalType" SG_ 1120 FLRRCANRxErr "BLN";
BA_ "SignalLongName" SG_ 1120 FLRRCANRxErr "Front Long Range Radar CAN Rx Error";
BA_ "VNSigAllNodes" SG_ 1120 FLRRCANRxErr 1;
BA_ "SignalType" SG_ 1120 FLRRCANIDAddrsUnsbl "BLN";
BA_ "SignalLongName" SG_ 1120 FLRRCANIDAddrsUnsbl "Front Long Range Radar CAN ID Address Unstable";
BA_ "VNSigAllNodes" SG_ 1120 FLRRCANIDAddrsUnsbl 1;
BA_ "SignalType" SG_ 1120 FLRRAmbTmpOutRngLw "BLN";
BA_ "SignalLongName" SG_ 1120 FLRRAmbTmpOutRngLw "Front Long Range Radar Ambient Temperature Out of Range Low";
BA_ "VNSigAllNodes" SG_ 1120 FLRRAmbTmpOutRngLw 1;
BA_ "SignalType" SG_ 1120 FLRRAmbTmpOutRngHi "BLN";
BA_ "SignalLongName" SG_ 1120 FLRRAmbTmpOutRngHi "Front Long Range Radar Ambient Temperature Out of Range High";
BA_ "VNSigAllNodes" SG_ 1120 FLRRAmbTmpOutRngHi 1;
BA_ "SignalType" SG_ 1120 FLRRAntTngFltPrsnt "BLN";
BA_ "SignalLongName" SG_ 1120 FLRRAntTngFltPrsnt "Front Long Range Radar Antenna Tuning Fault Present";
BA_ "VNSigAllNodes" SG_ 1120 FLRRAntTngFltPrsnt 1;
BA_ "SignalType" SG_ 1120 FLRRAlgnFltPrsnt "BLN";
BA_ "SignalLongName" SG_ 1120 FLRRAlgnFltPrsnt "Front Long Range Radar Alignment Fault Present";
BA_ "VNSigAllNodes" SG_ 1120 FLRRAlgnFltPrsnt 1;
BA_ "SignalType" SG_ 1121 FLRRTrk1BurstID "UNM";
BA_ "SignalLongName" SG_ 1121 FLRRTrk1BurstID "Front Long Range Radar Track 1 Burst ID";
BA_ "VNSigAllNodes" SG_ 1121 FLRRTrk1BurstID 1;
BA_ "SignalType" SG_ 1121 FLRRTrk1Range "UNM";
BA_ "SignalLongName" SG_ 1121 FLRRTrk1Range "Front Long Range Radar Track 1 Range";
BA_ "GenSigStartValue" SG_ 1121 FLRRTrk1Range 1;
BA_ "VNSigAllNodes" SG_ 1121 FLRRTrk1Range 1;
BA_ "SignalType" SG_ 1121 FLRRTrk1RangeRate "SNM";
BA_ "SignalLongName" SG_ 1121 FLRRTrk1RangeRate "Front Long Range Radar Track 1 Range Rate";
BA_ "VNSigAllNodes" SG_ 1121 FLRRTrk1RangeRate 1;
BA_ "SignalType" SG_ 1121 FLRRTrk1RangeAccel "SNM";
BA_ "SignalLongName" SG_ 1121 FLRRTrk1RangeAccel "Front Long Range Radar Track 1 Range Acceleration";
BA_ "VNSigAllNodes" SG_ 1121 FLRRTrk1RangeAccel 1;
BA_ "SignalType" SG_ 1121 FLRRTrk1DynProp "ENM";
BA_ "SignalLongName" SG_ 1121 FLRRTrk1DynProp "Front Long Range Radar Dynamic Property Track 1 ";
BA_ "VNSigAllNodes" SG_ 1121 FLRRTrk1DynProp 1;
BA_ "SignalType" SG_ 1121 FLRRTrk1Azimuth "SNM";
BA_ "SignalLongName" SG_ 1121 FLRRTrk1Azimuth "Front Long Range Radar Azimuth Track 1";
BA_ "VNSigAllNodes" SG_ 1121 FLRRTrk1Azimuth 1;
BA_ "SignalType" SG_ 1121 FLRRTrk1Width "UNM";
BA_ "SignalLongName" SG_ 1121 FLRRTrk1Width "Front Long Range Radar Track 1 Width";
BA_ "GenSigStartValue" SG_ 1121 FLRRTrk1Width 1;
BA_ "VNSigAllNodes" SG_ 1121 FLRRTrk1Width 1;
BA_ "SignalType" SG_ 1121 FLRRTrk1MeasStatus "ENM";
BA_ "SignalLongName" SG_ 1121 FLRRTrk1MeasStatus "Front Long Range Radar Measurement Status Track 1";
BA_ "VNSigAllNodes" SG_ 1121 FLRRTrk1MeasStatus 1;
BA_ "SignalType" SG_ 1121 FLRRTrk1ObjectID "UNM";
BA_ "SignalLongName" SG_ 1121 FLRRTrk1ObjectID "Front Long Range Radar Track 1 Object ID";
BA_ "VNSigAllNodes" SG_ 1121 FLRRTrk1ObjectID 1;
BA_ "SignalType" SG_ 1121 FLRRTrk1Conf "ENM";
BA_ "SignalLongName" SG_ 1121 FLRRTrk1Conf "Front Long Range Radar Track 1 Confidence";
BA_ "VNSigAllNodes" SG_ 1121 FLRRTrk1Conf 1;
BA_ "SignalType" SG_ 1122 FLRRTrk2BurstID "UNM";
BA_ "SignalLongName" SG_ 1122 FLRRTrk2BurstID "Front Long Range Radar Track 2 Burst ID";
BA_ "VNSigAllNodes" SG_ 1122 FLRRTrk2BurstID 1;
BA_ "SignalType" SG_ 1122 FLRRTrk2Range "UNM";
BA_ "SignalLongName" SG_ 1122 FLRRTrk2Range "Front Long Range Radar Track 2 Range";
BA_ "GenSigStartValue" SG_ 1122 FLRRTrk2Range 1;
BA_ "VNSigAllNodes" SG_ 1122 FLRRTrk2Range 1;
BA_ "SignalType" SG_ 1122 FLRRTrk2RangeRate "SNM";
BA_ "SignalLongName" SG_ 1122 FLRRTrk2RangeRate "Front Long Range Radar Track 2 Range Rate";
BA_ "VNSigAllNodes" SG_ 1122 FLRRTrk2RangeRate 1;
BA_ "SignalType" SG_ 1122 FLRRTrk2RangeAccel "SNM";
BA_ "SignalLongName" SG_ 1122 FLRRTrk2RangeAccel "Front Long Range Radar Track 2 Range Acceleration";
BA_ "VNSigAllNodes" SG_ 1122 FLRRTrk2RangeAccel 1;
BA_ "SignalType" SG_ 1122 FLRRTrk2DynProp "ENM";
BA_ "SignalLongName" SG_ 1122 FLRRTrk2DynProp "Front Long Range Radar Dynamic Property Track 2";
BA_ "VNSigAllNodes" SG_ 1122 FLRRTrk2DynProp 1;
BA_ "SignalType" SG_ 1122 FLRRTrk2Azimuth "SNM";
BA_ "SignalLongName" SG_ 1122 FLRRTrk2Azimuth "Front Long Range Radar Azimuth Track 2";
BA_ "VNSigAllNodes" SG_ 1122 FLRRTrk2Azimuth 1;
BA_ "SignalType" SG_ 1122 FLRRTrk2Width "UNM";
BA_ "SignalLongName" SG_ 1122 FLRRTrk2Width "Front Long Range Radar Track 2 Width";
BA_ "GenSigStartValue" SG_ 1122 FLRRTrk2Width 1;
BA_ "VNSigAllNodes" SG_ 1122 FLRRTrk2Width 1;
BA_ "SignalType" SG_ 1122 FLRRTrk2MeasStatus "ENM";
BA_ "SignalLongName" SG_ 1122 FLRRTrk2MeasStatus "Front Long Range Radar Measurement Status Track 2";
BA_ "VNSigAllNodes" SG_ 1122 FLRRTrk2MeasStatus 1;
BA_ "SignalType" SG_ 1122 FLRRTrk2ObjectID "UNM";
BA_ "SignalLongName" SG_ 1122 FLRRTrk2ObjectID "Front Long Range Radar Track 2 Object ID";
BA_ "VNSigAllNodes" SG_ 1122 FLRRTrk2ObjectID 1;
BA_ "SignalType" SG_ 1122 FLRRTrk2Conf "ENM";
BA_ "SignalLongName" SG_ 1122 FLRRTrk2Conf "Front Long Range Radar Track 2 Confidence";
BA_ "VNSigAllNodes" SG_ 1122 FLRRTrk2Conf 1;
BA_ "SignalType" SG_ 1123 FLRRTrk3BurstID "UNM";
BA_ "SignalLongName" SG_ 1123 FLRRTrk3BurstID "Front Long Range Radar Track 3 Burst ID";
BA_ "VNSigAllNodes" SG_ 1123 FLRRTrk3BurstID 1;
BA_ "SignalType" SG_ 1123 FLRRTrk3Range "UNM";
BA_ "SignalLongName" SG_ 1123 FLRRTrk3Range "Front Long Range Radar Track 3 Range";
BA_ "GenSigStartValue" SG_ 1123 FLRRTrk3Range 1;
BA_ "VNSigAllNodes" SG_ 1123 FLRRTrk3Range 1;
BA_ "SignalType" SG_ 1123 FLRRTrk3RangeRate "SNM";
BA_ "SignalLongName" SG_ 1123 FLRRTrk3RangeRate "Front Long Range Radar Track 3 Range Rate";
BA_ "VNSigAllNodes" SG_ 1123 FLRRTrk3RangeRate 1;
BA_ "SignalType" SG_ 1123 FLRRTrk3RangeAccel "SNM";
BA_ "SignalLongName" SG_ 1123 FLRRTrk3RangeAccel "Front Long Range Radar Track 3 Range Acceleration";
BA_ "VNSigAllNodes" SG_ 1123 FLRRTrk3RangeAccel 1;
BA_ "SignalType" SG_ 1123 FLRRTrk3DynProp "ENM";
BA_ "SignalLongName" SG_ 1123 FLRRTrk3DynProp "Front Long Range Radar Dynamic Property Track 3";
BA_ "VNSigAllNodes" SG_ 1123 FLRRTrk3DynProp 1;
BA_ "SignalType" SG_ 1123 FLRRTrk3Azimuth "SNM";
BA_ "SignalLongName" SG_ 1123 FLRRTrk3Azimuth "Front Long Range Radar Azimuth Track 3";
BA_ "VNSigAllNodes" SG_ 1123 FLRRTrk3Azimuth 1;
BA_ "SignalType" SG_ 1123 FLRRTrk3Width "UNM";
BA_ "SignalLongName" SG_ 1123 FLRRTrk3Width "Front Long Range Radar Track 3 Width";
BA_ "GenSigStartValue" SG_ 1123 FLRRTrk3Width 1;
BA_ "VNSigAllNodes" SG_ 1123 FLRRTrk3Width 1;
BA_ "SignalType" SG_ 1123 FLRRTrk3MeasStatus "ENM";
BA_ "SignalLongName" SG_ 1123 FLRRTrk3MeasStatus "Front Long Range Radar Measurement Status Track 3";
BA_ "VNSigAllNodes" SG_ 1123 FLRRTrk3MeasStatus 1;
BA_ "SignalType" SG_ 1123 FLRRTrk3ObjectID "UNM";
BA_ "SignalLongName" SG_ 1123 FLRRTrk3ObjectID "Front Long Range Radar Track 3 Object ID";
BA_ "VNSigAllNodes" SG_ 1123 FLRRTrk3ObjectID 1;
BA_ "SignalType" SG_ 1123 FLRRTrk3Conf "ENM";
BA_ "SignalLongName" SG_ 1123 FLRRTrk3Conf "Front Long Range Radar Track 3 Confidence";
BA_ "VNSigAllNodes" SG_ 1123 FLRRTrk3Conf 1;
BA_ "SignalType" SG_ 1124 FLRRTrk4BurstID "UNM";
BA_ "SignalLongName" SG_ 1124 FLRRTrk4BurstID "Front Long Range Radar Track 4 Burst ID";
BA_ "VNSigAllNodes" SG_ 1124 FLRRTrk4BurstID 1;
BA_ "SignalType" SG_ 1124 FLRRTrk4Range "UNM";
BA_ "SignalLongName" SG_ 1124 FLRRTrk4Range "Front Long Range Radar Track 4 Range";
BA_ "GenSigStartValue" SG_ 1124 FLRRTrk4Range 1;
BA_ "VNSigAllNodes" SG_ 1124 FLRRTrk4Range 1;
BA_ "SignalType" SG_ 1124 FLRRTrk4RangeRate "SNM";
BA_ "SignalLongName" SG_ 1124 FLRRTrk4RangeRate "Front Long Range Radar Track 4 Range Rate";
BA_ "VNSigAllNodes" SG_ 1124 FLRRTrk4RangeRate 1;
BA_ "SignalType" SG_ 1124 FLRRTrk4RangeAccel "SNM";
BA_ "SignalLongName" SG_ 1124 FLRRTrk4RangeAccel "Front Long Range Radar Track 4 Range Acceleration";
BA_ "VNSigAllNodes" SG_ 1124 FLRRTrk4RangeAccel 1;
BA_ "SignalType" SG_ 1124 FLRRTrk4DynProp "ENM";
BA_ "SignalLongName" SG_ 1124 FLRRTrk4DynProp "Front Long Range Radar Dynamic Property Track 4";
BA_ "VNSigAllNodes" SG_ 1124 FLRRTrk4DynProp 1;
BA_ "SignalType" SG_ 1124 FLRRTrk4Azimuth "SNM";
BA_ "SignalLongName" SG_ 1124 FLRRTrk4Azimuth "Front Long Range Radar Azimuth Track 4";
BA_ "VNSigAllNodes" SG_ 1124 FLRRTrk4Azimuth 1;
BA_ "SignalType" SG_ 1124 FLRRTrk4Width "UNM";
BA_ "SignalLongName" SG_ 1124 FLRRTrk4Width "Front Long Range Radar Track 4 Width";
BA_ "GenSigStartValue" SG_ 1124 FLRRTrk4Width 1;
BA_ "VNSigAllNodes" SG_ 1124 FLRRTrk4Width 1;
BA_ "SignalType" SG_ 1124 FLRRTrk4MeasStatus "ENM";
BA_ "SignalLongName" SG_ 1124 FLRRTrk4MeasStatus "Front Long Range Radar Measurement Status Track 4";
BA_ "VNSigAllNodes" SG_ 1124 FLRRTrk4MeasStatus 1;
BA_ "SignalType" SG_ 1124 FLRRTrk4ObjectID "UNM";
BA_ "SignalLongName" SG_ 1124 FLRRTrk4ObjectID "Front Long Range Radar Track 4 Object ID";
BA_ "VNSigAllNodes" SG_ 1124 FLRRTrk4ObjectID 1;
BA_ "SignalType" SG_ 1124 FLRRTrk4Conf "ENM";
BA_ "SignalLongName" SG_ 1124 FLRRTrk4Conf "Front Long Range Radar Track 4 Confidence";
BA_ "VNSigAllNodes" SG_ 1124 FLRRTrk4Conf 1;
BA_ "SignalType" SG_ 1125 FLRRTrk5BurstID "UNM";
BA_ "SignalLongName" SG_ 1125 FLRRTrk5BurstID "Front Long Range Radar Track 5 Burst ID";
BA_ "VNSigAllNodes" SG_ 1125 FLRRTrk5BurstID 1;
BA_ "SignalType" SG_ 1125 FLRRTrk5Range "UNM";
BA_ "SignalLongName" SG_ 1125 FLRRTrk5Range "Front Long Range Radar Track 5 Range";
BA_ "GenSigStartValue" SG_ 1125 FLRRTrk5Range 1;
BA_ "VNSigAllNodes" SG_ 1125 FLRRTrk5Range 1;
BA_ "SignalType" SG_ 1125 FLRRTrk5RangeRate "SNM";
BA_ "SignalLongName" SG_ 1125 FLRRTrk5RangeRate "Front Long Range Radar Track 5 RangeRate";
BA_ "VNSigAllNodes" SG_ 1125 FLRRTrk5RangeRate 1;
BA_ "SignalType" SG_ 1125 FLRRTrk5RangeAccel "SNM";
BA_ "SignalLongName" SG_ 1125 FLRRTrk5RangeAccel "Front Long Range Radar Track 5 Range Acceleration";
BA_ "VNSigAllNodes" SG_ 1125 FLRRTrk5RangeAccel 1;
BA_ "SignalType" SG_ 1125 FLRRTrk5DynProp "ENM";
BA_ "SignalLongName" SG_ 1125 FLRRTrk5DynProp "Front Long Range Radar Dynamic Property Track 5";
BA_ "VNSigAllNodes" SG_ 1125 FLRRTrk5DynProp 1;
BA_ "SignalType" SG_ 1125 FLRRTrk5Azimuth "SNM";
BA_ "SignalLongName" SG_ 1125 FLRRTrk5Azimuth "Front Long Range Radar Azimuth Track 5";
BA_ "VNSigAllNodes" SG_ 1125 FLRRTrk5Azimuth 1;
BA_ "SignalType" SG_ 1125 FLRRTrk5Width "UNM";
BA_ "SignalLongName" SG_ 1125 FLRRTrk5Width "Front Long Range Radar Track 5 Width";
BA_ "GenSigStartValue" SG_ 1125 FLRRTrk5Width 1;
BA_ "VNSigAllNodes" SG_ 1125 FLRRTrk5Width 1;
BA_ "SignalType" SG_ 1125 FLRRTrk5MeasStatus "ENM";
BA_ "SignalLongName" SG_ 1125 FLRRTrk5MeasStatus "Front Long Range Radar Measurement Status Track 5";
BA_ "VNSigAllNodes" SG_ 1125 FLRRTrk5MeasStatus 1;
BA_ "SignalType" SG_ 1125 FLRRTrk5ObjectID "UNM";
BA_ "SignalLongName" SG_ 1125 FLRRTrk5ObjectID "Front Long Range Radar Track 5 ObjectID";
BA_ "VNSigAllNodes" SG_ 1125 FLRRTrk5ObjectID 1;
BA_ "SignalType" SG_ 1125 FLRRTrk5Conf "ENM";
BA_ "SignalLongName" SG_ 1125 FLRRTrk5Conf "Front Long Range Radar Track 5 Confidence";
BA_ "VNSigAllNodes" SG_ 1125 FLRRTrk5Conf 1;
BA_ "SignalType" SG_ 1126 FLRRTrk6BurstID "UNM";
BA_ "SignalLongName" SG_ 1126 FLRRTrk6BurstID "Front Long Range Radar Track 6 Burst ID";
BA_ "VNSigAllNodes" SG_ 1126 FLRRTrk6BurstID 1;
BA_ "SignalType" SG_ 1126 FLRRTrk6Range "UNM";
BA_ "SignalLongName" SG_ 1126 FLRRTrk6Range "Front Long Range Radar Track 6 Range";
BA_ "GenSigStartValue" SG_ 1126 FLRRTrk6Range 1;
BA_ "VNSigAllNodes" SG_ 1126 FLRRTrk6Range 1;
BA_ "SignalType" SG_ 1126 FLRRTrk6RangeRate "SNM";
BA_ "SignalLongName" SG_ 1126 FLRRTrk6RangeRate "Front Long Range Radar Track 6 Range Rate";
BA_ "VNSigAllNodes" SG_ 1126 FLRRTrk6RangeRate 1;
BA_ "SignalType" SG_ 1126 FLRRTrk6Conf "ENM";
BA_ "SignalLongName" SG_ 1126 FLRRTrk6Conf "Front Long Range Radar Track 6 Confidence";
BA_ "VNSigAllNodes" SG_ 1126 FLRRTrk6Conf 1;
BA_ "SignalType" SG_ 1126 FLRRTrk6RangeAccel "SNM";
BA_ "SignalLongName" SG_ 1126 FLRRTrk6RangeAccel "Front Long Range Radar Track 6 Range Acceleration";
BA_ "VNSigAllNodes" SG_ 1126 FLRRTrk6RangeAccel 1;
BA_ "SignalType" SG_ 1126 FLRRTrk6DynProp "ENM";
BA_ "SignalLongName" SG_ 1126 FLRRTrk6DynProp "Front Long Range Radar Dynamic Property Track 6";
BA_ "VNSigAllNodes" SG_ 1126 FLRRTrk6DynProp 1;
BA_ "SignalType" SG_ 1126 FLRRTrk6Azimuth "SNM";
BA_ "SignalLongName" SG_ 1126 FLRRTrk6Azimuth "Front Long Range Radar Azimuth Track 6";
BA_ "VNSigAllNodes" SG_ 1126 FLRRTrk6Azimuth 1;
BA_ "SignalType" SG_ 1126 FLRRTrk6Width "UNM";
BA_ "SignalLongName" SG_ 1126 FLRRTrk6Width "Front Long Range Radar Track 6 Width";
BA_ "GenSigStartValue" SG_ 1126 FLRRTrk6Width 1;
BA_ "VNSigAllNodes" SG_ 1126 FLRRTrk6Width 1;
BA_ "SignalType" SG_ 1126 FLRRTrk6MeasStatus "ENM";
BA_ "SignalLongName" SG_ 1126 FLRRTrk6MeasStatus "Front Long Range Radar Measurement Status Track 6";
BA_ "VNSigAllNodes" SG_ 1126 FLRRTrk6MeasStatus 1;
BA_ "SignalType" SG_ 1126 FLRRTrk6ObjectID "UNM";
BA_ "SignalLongName" SG_ 1126 FLRRTrk6ObjectID "Front Long Range Radar Track 6 Object ID";
BA_ "VNSigAllNodes" SG_ 1126 FLRRTrk6ObjectID 1;
BA_ "SignalType" SG_ 1127 FLRRTrk7Conf "ENM";
BA_ "SignalLongName" SG_ 1127 FLRRTrk7Conf "Front Long Range Radar Track 7 Confidence";
BA_ "VNSigAllNodes" SG_ 1127 FLRRTrk7Conf 1;
BA_ "SignalType" SG_ 1127 FLRRTrk7BurstID "UNM";
BA_ "SignalLongName" SG_ 1127 FLRRTrk7BurstID "Front Long Range Radar Track 7 Burst ID";
BA_ "VNSigAllNodes" SG_ 1127 FLRRTrk7BurstID 1;
BA_ "SignalType" SG_ 1127 FLRRTrk7Range "UNM";
BA_ "SignalLongName" SG_ 1127 FLRRTrk7Range "Front Long Range Radar Track 7 Range";
BA_ "GenSigStartValue" SG_ 1127 FLRRTrk7Range 1;
BA_ "VNSigAllNodes" SG_ 1127 FLRRTrk7Range 1;
BA_ "SignalType" SG_ 1127 FLRRTrk7RangeRate "SNM";
BA_ "SignalLongName" SG_ 1127 FLRRTrk7RangeRate "Front Long Range Radar Track 7 Range Rate";
BA_ "VNSigAllNodes" SG_ 1127 FLRRTrk7RangeRate 1;
BA_ "SignalType" SG_ 1127 FLRRTrk7RangeAccel "SNM";
BA_ "SignalLongName" SG_ 1127 FLRRTrk7RangeAccel "Front Long Range Radar Track 7 Range Acceleration";
BA_ "VNSigAllNodes" SG_ 1127 FLRRTrk7RangeAccel 1;
BA_ "SignalType" SG_ 1127 FLRRTrk7DynProp "ENM";
BA_ "SignalLongName" SG_ 1127 FLRRTrk7DynProp "Front Long Range Radar Dynamic Property Track 7";
BA_ "VNSigAllNodes" SG_ 1127 FLRRTrk7DynProp 1;
BA_ "SignalType" SG_ 1127 FLRRTrk7Azimuth "SNM";
BA_ "SignalLongName" SG_ 1127 FLRRTrk7Azimuth "Front Long Range Radar Azimuth Track 7";
BA_ "VNSigAllNodes" SG_ 1127 FLRRTrk7Azimuth 1;
BA_ "SignalType" SG_ 1127 FLRRTrk7Width "UNM";
BA_ "SignalLongName" SG_ 1127 FLRRTrk7Width "Front Long Range Radar Track 7 Width";
BA_ "GenSigStartValue" SG_ 1127 FLRRTrk7Width 1;
BA_ "VNSigAllNodes" SG_ 1127 FLRRTrk7Width 1;
BA_ "SignalType" SG_ 1127 FLRRTrk7MeasStatus "ENM";
BA_ "SignalLongName" SG_ 1127 FLRRTrk7MeasStatus "Front Long Range Radar Measurement Status Track 7";
BA_ "VNSigAllNodes" SG_ 1127 FLRRTrk7MeasStatus 1;
BA_ "SignalType" SG_ 1127 FLRRTrk7ObjectID "UNM";
BA_ "SignalLongName" SG_ 1127 FLRRTrk7ObjectID "Front Long Range Radar Track 7 Object ID";
BA_ "VNSigAllNodes" SG_ 1127 FLRRTrk7ObjectID 1;
BA_ "SignalType" SG_ 1128 FLRRTrk8Conf "ENM";
BA_ "SignalLongName" SG_ 1128 FLRRTrk8Conf "Front Long Range Radar Track 8 Confidence";
BA_ "VNSigAllNodes" SG_ 1128 FLRRTrk8Conf 1;
BA_ "SignalType" SG_ 1128 FLRRTrk8BurstID "UNM";
BA_ "SignalLongName" SG_ 1128 FLRRTrk8BurstID "Front Long Range Radar Track 8 Burst ID";
BA_ "VNSigAllNodes" SG_ 1128 FLRRTrk8BurstID 1;
BA_ "SignalType" SG_ 1128 FLRRTrk8Range "UNM";
BA_ "SignalLongName" SG_ 1128 FLRRTrk8Range "Front Long Range Radar Track 8 Range";
BA_ "GenSigStartValue" SG_ 1128 FLRRTrk8Range 1;
BA_ "VNSigAllNodes" SG_ 1128 FLRRTrk8Range 1;
BA_ "SignalType" SG_ 1128 FLRRTrk8RangeRate "SNM";
BA_ "SignalLongName" SG_ 1128 FLRRTrk8RangeRate "Front Long Range Radar Track 8 Range Rate";
BA_ "VNSigAllNodes" SG_ 1128 FLRRTrk8RangeRate 1;
BA_ "SignalType" SG_ 1128 FLRRTrk8RangeAccel "SNM";
BA_ "SignalLongName" SG_ 1128 FLRRTrk8RangeAccel "Front Long Range Radar Track 8 Range Acceleration";
BA_ "VNSigAllNodes" SG_ 1128 FLRRTrk8RangeAccel 1;
BA_ "SignalType" SG_ 1128 FLRRTrk8DynProp "ENM";
BA_ "SignalLongName" SG_ 1128 FLRRTrk8DynProp "Front Long Range Radar Dynamic Property Track 8";
BA_ "VNSigAllNodes" SG_ 1128 FLRRTrk8DynProp 1;
BA_ "SignalType" SG_ 1128 FLRRTrk8Azimuth "SNM";
BA_ "SignalLongName" SG_ 1128 FLRRTrk8Azimuth "Front Long Range Radar Azimuth Track 8";
BA_ "VNSigAllNodes" SG_ 1128 FLRRTrk8Azimuth 1;
BA_ "SignalType" SG_ 1128 FLRRTrk8Width "UNM";
BA_ "SignalLongName" SG_ 1128 FLRRTrk8Width "Front Long Range Radar Track 8 Width";
BA_ "GenSigStartValue" SG_ 1128 FLRRTrk8Width 1;
BA_ "VNSigAllNodes" SG_ 1128 FLRRTrk8Width 1;
BA_ "SignalType" SG_ 1128 FLRRTrk8MeasStatus "ENM";
BA_ "SignalLongName" SG_ 1128 FLRRTrk8MeasStatus "Front Long Range Radar Measurement Status Track 8";
BA_ "VNSigAllNodes" SG_ 1128 FLRRTrk8MeasStatus 1;
BA_ "SignalType" SG_ 1128 FLRRTrk8ObjectID "UNM";
BA_ "SignalLongName" SG_ 1128 FLRRTrk8ObjectID "Front Long Range Radar Track 8 Object ID";
BA_ "VNSigAllNodes" SG_ 1128 FLRRTrk8ObjectID 1;
BA_ "SignalType" SG_ 1129 FLRRTrk9Conf "ENM";
BA_ "SignalLongName" SG_ 1129 FLRRTrk9Conf "Front Long Range Radar Track 9 Confidence";
BA_ "VNSigAllNodes" SG_ 1129 FLRRTrk9Conf 1;
BA_ "SignalType" SG_ 1129 FLRRTrk9BurstID "UNM";
BA_ "SignalLongName" SG_ 1129 FLRRTrk9BurstID "Front Long Range Radar Track 9 Burst ID";
BA_ "VNSigAllNodes" SG_ 1129 FLRRTrk9BurstID 1;
BA_ "SignalType" SG_ 1129 FLRRTrk9Range "UNM";
BA_ "SignalLongName" SG_ 1129 FLRRTrk9Range "Front Long Range Radar Track 9 Range";
BA_ "GenSigStartValue" SG_ 1129 FLRRTrk9Range 1;
BA_ "VNSigAllNodes" SG_ 1129 FLRRTrk9Range 1;
BA_ "SignalType" SG_ 1129 FLRRTrk9RangeRate "SNM";
BA_ "SignalLongName" SG_ 1129 FLRRTrk9RangeRate "Front Long Range Radar Track 9 Range Rate";
BA_ "VNSigAllNodes" SG_ 1129 FLRRTrk9RangeRate 1;
BA_ "SignalType" SG_ 1129 FLRRTrk9RangeAccel "SNM";
BA_ "SignalLongName" SG_ 1129 FLRRTrk9RangeAccel "Front Long Range Radar Track 9 Range Acceleration";
BA_ "VNSigAllNodes" SG_ 1129 FLRRTrk9RangeAccel 1;
BA_ "SignalType" SG_ 1129 FLRRTrk9DynProp "ENM";
BA_ "SignalLongName" SG_ 1129 FLRRTrk9DynProp "Front Long Range Radar Dynamic Property Track 9";
BA_ "VNSigAllNodes" SG_ 1129 FLRRTrk9DynProp 1;
BA_ "SignalType" SG_ 1129 FLRRTrk9Azimuth "SNM";
BA_ "SignalLongName" SG_ 1129 FLRRTrk9Azimuth "Front Long Range Radar Azimuth Track 9";
BA_ "VNSigAllNodes" SG_ 1129 FLRRTrk9Azimuth 1;
BA_ "SignalType" SG_ 1129 FLRRTrk9Width "UNM";
BA_ "SignalLongName" SG_ 1129 FLRRTrk9Width "Front Long Range Radar Track 9 Width";
BA_ "GenSigStartValue" SG_ 1129 FLRRTrk9Width 1;
BA_ "VNSigAllNodes" SG_ 1129 FLRRTrk9Width 1;
BA_ "SignalType" SG_ 1129 FLRRTrk9MeasStatus "ENM";
BA_ "SignalLongName" SG_ 1129 FLRRTrk9MeasStatus "Front Long Range Radar Measurement Status Track 9";
BA_ "VNSigAllNodes" SG_ 1129 FLRRTrk9MeasStatus 1;
BA_ "SignalType" SG_ 1129 FLRRTrk9ObjectID "UNM";
BA_ "SignalLongName" SG_ 1129 FLRRTrk9ObjectID "Front Long Range Radar Track 9 Object ID";
BA_ "VNSigAllNodes" SG_ 1129 FLRRTrk9ObjectID 1;
BA_ "SignalType" SG_ 1130 FLRRTrk10Conf "ENM";
BA_ "SignalLongName" SG_ 1130 FLRRTrk10Conf "Front Long Range Radar Track 10 Confidence";
BA_ "VNSigAllNodes" SG_ 1130 FLRRTrk10Conf 1;
BA_ "SignalType" SG_ 1130 FLRRTrk10BurstID "UNM";
BA_ "SignalLongName" SG_ 1130 FLRRTrk10BurstID "Front Long Range Radar Track 10 Burst ID";
BA_ "VNSigAllNodes" SG_ 1130 FLRRTrk10BurstID 1;
BA_ "SignalType" SG_ 1130 FLRRTrk10Range "UNM";
BA_ "SignalLongName" SG_ 1130 FLRRTrk10Range "Front Long Range Radar Track 10 Range";
BA_ "GenSigStartValue" SG_ 1130 FLRRTrk10Range 1;
BA_ "VNSigAllNodes" SG_ 1130 FLRRTrk10Range 1;
BA_ "SignalType" SG_ 1130 FLRRTrk10RangeRate "SNM";
BA_ "SignalLongName" SG_ 1130 FLRRTrk10RangeRate "Front Long Range Radar Track 10 Range Rate";
BA_ "VNSigAllNodes" SG_ 1130 FLRRTrk10RangeRate 1;
BA_ "SignalType" SG_ 1130 FLRRTrk10RangeAccel "SNM";
BA_ "SignalLongName" SG_ 1130 FLRRTrk10RangeAccel "Front Long Range Radar Track 10 Range Acceleration";
BA_ "VNSigAllNodes" SG_ 1130 FLRRTrk10RangeAccel 1;
BA_ "SignalType" SG_ 1130 FLRRTrk10DynProp "ENM";
BA_ "SignalLongName" SG_ 1130 FLRRTrk10DynProp "Front Long Range Radar Dynamic Property Track 10";
BA_ "VNSigAllNodes" SG_ 1130 FLRRTrk10DynProp 1;
BA_ "SignalType" SG_ 1130 FLRRTrk10Azimuth "SNM";
BA_ "SignalLongName" SG_ 1130 FLRRTrk10Azimuth "Front Long Range Radar Azimuth Track 10";
BA_ "VNSigAllNodes" SG_ 1130 FLRRTrk10Azimuth 1;
BA_ "SignalType" SG_ 1130 FLRRTrk10Width "UNM";
BA_ "SignalLongName" SG_ 1130 FLRRTrk10Width "Front Long Range Radar Track 10 Width";
BA_ "GenSigStartValue" SG_ 1130 FLRRTrk10Width 1;
BA_ "VNSigAllNodes" SG_ 1130 FLRRTrk10Width 1;
BA_ "SignalType" SG_ 1130 FLRRTrk10MeasStatus "ENM";
BA_ "SignalLongName" SG_ 1130 FLRRTrk10MeasStatus "Front Long Range Radar Measurement Status Track 10";
BA_ "VNSigAllNodes" SG_ 1130 FLRRTrk10MeasStatus 1;
BA_ "SignalType" SG_ 1130 FLRRTrk10ObjectID "UNM";
BA_ "SignalLongName" SG_ 1130 FLRRTrk10ObjectID "Front Long Range Radar Track 10 Object ID";
BA_ "VNSigAllNodes" SG_ 1130 FLRRTrk10ObjectID 1;
BA_ "SignalType" SG_ 1131 FLRRTrk11Conf "ENM";
BA_ "SignalLongName" SG_ 1131 FLRRTrk11Conf "Front Long Range Radar Track 11 Confidence";
BA_ "VNSigAllNodes" SG_ 1131 FLRRTrk11Conf 1;
BA_ "SignalType" SG_ 1131 FLRRTrk11BurstID "UNM";
BA_ "SignalLongName" SG_ 1131 FLRRTrk11BurstID "Front Long Range Radar Track 11 Burst ID";
BA_ "VNSigAllNodes" SG_ 1131 FLRRTrk11BurstID 1;
BA_ "SignalType" SG_ 1131 FLRRTrk11Range "UNM";
BA_ "SignalLongName" SG_ 1131 FLRRTrk11Range "Front Long Range Radar Track 11 Range";
BA_ "GenSigStartValue" SG_ 1131 FLRRTrk11Range 1;
BA_ "VNSigAllNodes" SG_ 1131 FLRRTrk11Range 1;
BA_ "SignalType" SG_ 1131 FLRRTrk11RangeRate "SNM";
BA_ "SignalLongName" SG_ 1131 FLRRTrk11RangeRate "Front Long Range Radar Track 11 Range Rate";
BA_ "VNSigAllNodes" SG_ 1131 FLRRTrk11RangeRate 1;
BA_ "SignalType" SG_ 1131 FLRRTrk11RangeAccel "SNM";
BA_ "SignalLongName" SG_ 1131 FLRRTrk11RangeAccel "Front Long Range Radar Track 11 Range Acceleration";
BA_ "VNSigAllNodes" SG_ 1131 FLRRTrk11RangeAccel 1;
BA_ "SignalType" SG_ 1131 FLRRTrk11DynProp "ENM";
BA_ "SignalLongName" SG_ 1131 FLRRTrk11DynProp "Front Long Range Radar Dynamic Property Track 11";
BA_ "VNSigAllNodes" SG_ 1131 FLRRTrk11DynProp 1;
BA_ "SignalType" SG_ 1131 FLRRTrk11Azimuth "SNM";
BA_ "SignalLongName" SG_ 1131 FLRRTrk11Azimuth "Front Long Range Radar Azimuth Track 11";
BA_ "VNSigAllNodes" SG_ 1131 FLRRTrk11Azimuth 1;
BA_ "SignalType" SG_ 1131 FLRRTrk11Width "UNM";
BA_ "SignalLongName" SG_ 1131 FLRRTrk11Width "Front Long Range Radar Track 11 Width";
BA_ "GenSigStartValue" SG_ 1131 FLRRTrk11Width 1;
BA_ "VNSigAllNodes" SG_ 1131 FLRRTrk11Width 1;
BA_ "SignalType" SG_ 1131 FLRRTrk11MeasStatus "ENM";
BA_ "SignalLongName" SG_ 1131 FLRRTrk11MeasStatus "Front Long Range Radar Measurement Status Track 11";
BA_ "VNSigAllNodes" SG_ 1131 FLRRTrk11MeasStatus 1;
BA_ "SignalType" SG_ 1131 FLRRTrk11ObjectID "UNM";
BA_ "SignalLongName" SG_ 1131 FLRRTrk11ObjectID "Front Long Range Radar Track 11 Object ID";
BA_ "VNSigAllNodes" SG_ 1131 FLRRTrk11ObjectID 1;
BA_ "SignalType" SG_ 1132 FLRRTrk12Conf "ENM";
BA_ "SignalLongName" SG_ 1132 FLRRTrk12Conf "Front Long Range Radar Track 12 Confidence";
BA_ "VNSigAllNodes" SG_ 1132 FLRRTrk12Conf 1;
BA_ "SignalType" SG_ 1132 FLRRTrk12BurstID "UNM";
BA_ "SignalLongName" SG_ 1132 FLRRTrk12BurstID "Front Long Range Radar Track 12 Burst ID";
BA_ "VNSigAllNodes" SG_ 1132 FLRRTrk12BurstID 1;
BA_ "SignalType" SG_ 1132 FLRRTrk12Range "UNM";
BA_ "SignalLongName" SG_ 1132 FLRRTrk12Range "Front Long Range Radar Track 12 Range";
BA_ "GenSigStartValue" SG_ 1132 FLRRTrk12Range 1;
BA_ "VNSigAllNodes" SG_ 1132 FLRRTrk12Range 1;
BA_ "SignalType" SG_ 1132 FLRRTrk12RangeRate "SNM";
BA_ "SignalLongName" SG_ 1132 FLRRTrk12RangeRate "Front Long Range Radar Track 12 Range Rate";
BA_ "VNSigAllNodes" SG_ 1132 FLRRTrk12RangeRate 1;
BA_ "SignalType" SG_ 1132 FLRRTrk12RangeAccel "SNM";
BA_ "SignalLongName" SG_ 1132 FLRRTrk12RangeAccel "Front Long Range Radar Track 12 Range Acceleration";
BA_ "VNSigAllNodes" SG_ 1132 FLRRTrk12RangeAccel 1;
BA_ "SignalType" SG_ 1132 FLRRTrk12DynProp "ENM";
BA_ "SignalLongName" SG_ 1132 FLRRTrk12DynProp "Front Long Range Radar Dynamic Property Track 12";
BA_ "VNSigAllNodes" SG_ 1132 FLRRTrk12DynProp 1;
BA_ "SignalType" SG_ 1132 FLRRTrk12Azimuth "SNM";
BA_ "SignalLongName" SG_ 1132 FLRRTrk12Azimuth "Front Long Range Radar Azimuth Track 12";
BA_ "VNSigAllNodes" SG_ 1132 FLRRTrk12Azimuth 1;
BA_ "SignalType" SG_ 1132 FLRRTrk12Width "UNM";
BA_ "SignalLongName" SG_ 1132 FLRRTrk12Width "Front Long Range Radar Track 12 Width";
BA_ "GenSigStartValue" SG_ 1132 FLRRTrk12Width 1;
BA_ "VNSigAllNodes" SG_ 1132 FLRRTrk12Width 1;
BA_ "SignalType" SG_ 1132 FLRRTrk12MeasStatus "ENM";
BA_ "SignalLongName" SG_ 1132 FLRRTrk12MeasStatus "Front Long Range Radar Measurement Status Track 12";
BA_ "VNSigAllNodes" SG_ 1132 FLRRTrk12MeasStatus 1;
BA_ "SignalType" SG_ 1132 FLRRTrk12ObjectID "UNM";
BA_ "SignalLongName" SG_ 1132 FLRRTrk12ObjectID "Front Long Range Radar Track 12 Object ID";
BA_ "VNSigAllNodes" SG_ 1132 FLRRTrk12ObjectID 1;
BA_ "SignalType" SG_ 1133 FLRRTrk13Conf "ENM";
BA_ "SignalLongName" SG_ 1133 FLRRTrk13Conf "Front Long Range Radar Track 13 Confidence";
BA_ "VNSigAllNodes" SG_ 1133 FLRRTrk13Conf 1;
BA_ "SignalType" SG_ 1133 FLRRTrk13BurstID "UNM";
BA_ "SignalLongName" SG_ 1133 FLRRTrk13BurstID "Front Long Range Radar Track 13 Burst ID";
BA_ "VNSigAllNodes" SG_ 1133 FLRRTrk13BurstID 1;
BA_ "SignalType" SG_ 1133 FLRRTrk13Range "UNM";
BA_ "SignalLongName" SG_ 1133 FLRRTrk13Range "Front Long Range Radar Track 13 Range";
BA_ "GenSigStartValue" SG_ 1133 FLRRTrk13Range 1;
BA_ "VNSigAllNodes" SG_ 1133 FLRRTrk13Range 1;
BA_ "SignalType" SG_ 1133 FLRRTrk13RangeRate "SNM";
BA_ "SignalLongName" SG_ 1133 FLRRTrk13RangeRate "Front Long Range Radar Track 13 Range Rate";
BA_ "VNSigAllNodes" SG_ 1133 FLRRTrk13RangeRate 1;
BA_ "SignalType" SG_ 1133 FLRRTrk13RangeAccel "SNM";
BA_ "SignalLongName" SG_ 1133 FLRRTrk13RangeAccel "Front Long Range Radar Track 13 Range Acceleration";
BA_ "VNSigAllNodes" SG_ 1133 FLRRTrk13RangeAccel 1;
BA_ "SignalType" SG_ 1133 FLRRTrk13DynProp "ENM";
BA_ "SignalLongName" SG_ 1133 FLRRTrk13DynProp "Front Long Range Radar Dynamic Property Track 13";
BA_ "VNSigAllNodes" SG_ 1133 FLRRTrk13DynProp 1;
BA_ "SignalType" SG_ 1133 FLRRTrk13Azimuth "SNM";
BA_ "SignalLongName" SG_ 1133 FLRRTrk13Azimuth "Front Long Range Radar Azimuth Track 13";
BA_ "VNSigAllNodes" SG_ 1133 FLRRTrk13Azimuth 1;
BA_ "SignalType" SG_ 1133 FLRRTrk13Width "UNM";
BA_ "SignalLongName" SG_ 1133 FLRRTrk13Width "Front Long Range Radar Track 13 Width";
BA_ "GenSigStartValue" SG_ 1133 FLRRTrk13Width 1;
BA_ "VNSigAllNodes" SG_ 1133 FLRRTrk13Width 1;
BA_ "SignalType" SG_ 1133 FLRRTrk13MeasStatus "ENM";
BA_ "SignalLongName" SG_ 1133 FLRRTrk13MeasStatus "Front Long Range Radar Measurement Status Track 13";
BA_ "VNSigAllNodes" SG_ 1133 FLRRTrk13MeasStatus 1;
BA_ "SignalType" SG_ 1133 FLRRTrk13ObjectID "UNM";
BA_ "SignalLongName" SG_ 1133 FLRRTrk13ObjectID "Front Long Range Radar Track 13 Object ID";
BA_ "VNSigAllNodes" SG_ 1133 FLRRTrk13ObjectID 1;
BA_ "SignalType" SG_ 1134 FLRRTrk14Conf "ENM";
BA_ "SignalLongName" SG_ 1134 FLRRTrk14Conf "Front Long Range Radar Track 14 Confidence";
BA_ "VNSigAllNodes" SG_ 1134 FLRRTrk14Conf 1;
BA_ "SignalType" SG_ 1134 FLRRTrk14BurstID "UNM";
BA_ "SignalLongName" SG_ 1134 FLRRTrk14BurstID "Front Long Range Radar Track 14 Burst ID";
BA_ "VNSigAllNodes" SG_ 1134 FLRRTrk14BurstID 1;
BA_ "SignalType" SG_ 1134 FLRRTrk14Range "UNM";
BA_ "SignalLongName" SG_ 1134 FLRRTrk14Range "Front Long Range Radar Track 14 Range";
BA_ "GenSigStartValue" SG_ 1134 FLRRTrk14Range 1;
BA_ "VNSigAllNodes" SG_ 1134 FLRRTrk14Range 1;
BA_ "SignalType" SG_ 1134 FLRRTrk14RangeRate "SNM";
BA_ "SignalLongName" SG_ 1134 FLRRTrk14RangeRate "Front Long Range Radar Track 14 Range Rate";
BA_ "VNSigAllNodes" SG_ 1134 FLRRTrk14RangeRate 1;
BA_ "SignalType" SG_ 1134 FLRRTrk14RangeAccel "SNM";
BA_ "SignalLongName" SG_ 1134 FLRRTrk14RangeAccel "Front Long Range Radar Track 14 Range Acceleration";
BA_ "VNSigAllNodes" SG_ 1134 FLRRTrk14RangeAccel 1;
BA_ "SignalType" SG_ 1134 FLRRTrk14DynProp "ENM";
BA_ "SignalLongName" SG_ 1134 FLRRTrk14DynProp "Front Long Range Radar Dynamic Property Track 14";
BA_ "VNSigAllNodes" SG_ 1134 FLRRTrk14DynProp 1;
BA_ "SignalType" SG_ 1134 FLRRTrk14Azimuth "SNM";
BA_ "SignalLongName" SG_ 1134 FLRRTrk14Azimuth "Front Long Range Radar Azimuth Track 14";
BA_ "VNSigAllNodes" SG_ 1134 FLRRTrk14Azimuth 1;
BA_ "SignalType" SG_ 1134 FLRRTrk14Width "UNM";
BA_ "SignalLongName" SG_ 1134 FLRRTrk14Width "Front Long Range Radar Track 14 Width";
BA_ "GenSigStartValue" SG_ 1134 FLRRTrk14Width 1;
BA_ "VNSigAllNodes" SG_ 1134 FLRRTrk14Width 1;
BA_ "SignalType" SG_ 1134 FLRRTrk14MeasStatus "ENM";
BA_ "SignalLongName" SG_ 1134 FLRRTrk14MeasStatus "Front Long Range Radar Measurement Status Track 14";
BA_ "VNSigAllNodes" SG_ 1134 FLRRTrk14MeasStatus 1;
BA_ "SignalType" SG_ 1134 FLRRTrk14ObjectID "UNM";
BA_ "SignalLongName" SG_ 1134 FLRRTrk14ObjectID "Front Long Range Radar Track 14 Object ID";
BA_ "VNSigAllNodes" SG_ 1134 FLRRTrk14ObjectID 1;
BA_ "SignalType" SG_ 1135 FLRRTrk15Width "UNM";
BA_ "SignalLongName" SG_ 1135 FLRRTrk15Width "Front Long Range Radar Track 15 Width";
BA_ "GenSigStartValue" SG_ 1135 FLRRTrk15Width 1;
BA_ "VNSigAllNodes" SG_ 1135 FLRRTrk15Width 1;
BA_ "SignalType" SG_ 1135 FLRRTrk15MeasStatus "ENM";
BA_ "SignalLongName" SG_ 1135 FLRRTrk15MeasStatus "Front Long Range Radar Measurement Status Track 15";
BA_ "VNSigAllNodes" SG_ 1135 FLRRTrk15MeasStatus 1;
BA_ "SignalType" SG_ 1135 FLRRTrk15Conf "ENM";
BA_ "SignalLongName" SG_ 1135 FLRRTrk15Conf "Front Long Range Radar Track 15 Confidence";
BA_ "VNSigAllNodes" SG_ 1135 FLRRTrk15Conf 1;
BA_ "SignalType" SG_ 1135 FLRRTrk15ObjectID "UNM";
BA_ "SignalLongName" SG_ 1135 FLRRTrk15ObjectID "Front Long Range Radar Track 15 Object ID";
BA_ "VNSigAllNodes" SG_ 1135 FLRRTrk15ObjectID 1;
BA_ "SignalType" SG_ 1135 FLRRTrk15BurstID "UNM";
BA_ "SignalLongName" SG_ 1135 FLRRTrk15BurstID "Front Long Range Radar Track 15 Burst ID";
BA_ "VNSigAllNodes" SG_ 1135 FLRRTrk15BurstID 1;
BA_ "SignalType" SG_ 1135 FLRRTrk15Range "UNM";
BA_ "SignalLongName" SG_ 1135 FLRRTrk15Range "Front Long Range Radar Track 15 Range";
BA_ "GenSigStartValue" SG_ 1135 FLRRTrk15Range 1;
BA_ "VNSigAllNodes" SG_ 1135 FLRRTrk15Range 1;
BA_ "SignalType" SG_ 1135 FLRRTrk15RangeRate "SNM";
BA_ "SignalLongName" SG_ 1135 FLRRTrk15RangeRate "Front Long Range Radar Track 15 Range Rate";
BA_ "VNSigAllNodes" SG_ 1135 FLRRTrk15RangeRate 1;
BA_ "SignalType" SG_ 1135 FLRRTrk15RangeAccel "SNM";
BA_ "SignalLongName" SG_ 1135 FLRRTrk15RangeAccel "Front Long Range Radar Track 15 Range Acceleration";
BA_ "VNSigAllNodes" SG_ 1135 FLRRTrk15RangeAccel 1;
BA_ "SignalType" SG_ 1135 FLRRTrk15DynProp "ENM";
BA_ "SignalLongName" SG_ 1135 FLRRTrk15DynProp "Front Long Range Radar Dynamic Property Track 15";
BA_ "VNSigAllNodes" SG_ 1135 FLRRTrk15DynProp 1;
BA_ "SignalType" SG_ 1135 FLRRTrk15Azimuth "SNM";
BA_ "SignalLongName" SG_ 1135 FLRRTrk15Azimuth "Front Long Range Radar Azimuth Track 15";
BA_ "VNSigAllNodes" SG_ 1135 FLRRTrk15Azimuth 1;
BA_ "SignalType" SG_ 1136 FLRRTrk16Conf "ENM";
BA_ "SignalLongName" SG_ 1136 FLRRTrk16Conf "Front Long Range Radar Track 16 Confidence";
BA_ "VNSigAllNodes" SG_ 1136 FLRRTrk16Conf 1;
BA_ "SignalType" SG_ 1136 FLRRTrk16BurstID "UNM";
BA_ "SignalLongName" SG_ 1136 FLRRTrk16BurstID "Front Long Range Radar Track 16 Burst ID";
BA_ "VNSigAllNodes" SG_ 1136 FLRRTrk16BurstID 1;
BA_ "SignalType" SG_ 1136 FLRRTrk16Range "UNM";
BA_ "SignalLongName" SG_ 1136 FLRRTrk16Range "Front Long Range Radar Track 16 Range";
BA_ "GenSigStartValue" SG_ 1136 FLRRTrk16Range 1;
BA_ "VNSigAllNodes" SG_ 1136 FLRRTrk16Range 1;
BA_ "SignalType" SG_ 1136 FLRRTrk16RangeRate "SNM";
BA_ "SignalLongName" SG_ 1136 FLRRTrk16RangeRate "Front Long Range Radar Track 16 Range Rate";
BA_ "VNSigAllNodes" SG_ 1136 FLRRTrk16RangeRate 1;
BA_ "SignalType" SG_ 1136 FLRRTrk16RangeAccel "SNM";
BA_ "SignalLongName" SG_ 1136 FLRRTrk16RangeAccel "Front Long Range Radar Track 16 Range Acceleration";
BA_ "VNSigAllNodes" SG_ 1136 FLRRTrk16RangeAccel 1;
BA_ "SignalType" SG_ 1136 FLRRTrk16DynProp "ENM";
BA_ "SignalLongName" SG_ 1136 FLRRTrk16DynProp "Front Long Range Radar Dynamic Property Track 16";
BA_ "VNSigAllNodes" SG_ 1136 FLRRTrk16DynProp 1;
BA_ "SignalType" SG_ 1136 FLRRTrk16Azimuth "SNM";
BA_ "SignalLongName" SG_ 1136 FLRRTrk16Azimuth "Front Long Range Radar Azimuth Track 16";
BA_ "VNSigAllNodes" SG_ 1136 FLRRTrk16Azimuth 1;
BA_ "SignalType" SG_ 1136 FLRRTrk16Width "UNM";
BA_ "SignalLongName" SG_ 1136 FLRRTrk16Width "Front Long Range Radar Track 16 Width";
BA_ "GenSigStartValue" SG_ 1136 FLRRTrk16Width 1;
BA_ "VNSigAllNodes" SG_ 1136 FLRRTrk16Width 1;
BA_ "SignalType" SG_ 1136 FLRRTrk16MeasStatus "ENM";
BA_ "SignalLongName" SG_ 1136 FLRRTrk16MeasStatus "Front Long Range Radar Measurement Status Track 16";
BA_ "VNSigAllNodes" SG_ 1136 FLRRTrk16MeasStatus 1;
BA_ "SignalType" SG_ 1136 FLRRTrk16ObjectID "UNM";
BA_ "SignalLongName" SG_ 1136 FLRRTrk16ObjectID "Front Long Range Radar Track 16 Object ID";
BA_ "VNSigAllNodes" SG_ 1136 FLRRTrk16ObjectID 1;
BA_ "SignalType" SG_ 1137 FLRRTrk17Conf "ENM";
BA_ "SignalLongName" SG_ 1137 FLRRTrk17Conf "Front Long Range Radar Track 17 Confidence";
BA_ "VNSigAllNodes" SG_ 1137 FLRRTrk17Conf 1;
BA_ "SignalType" SG_ 1137 FLRRTrk17BurstID "UNM";
BA_ "SignalLongName" SG_ 1137 FLRRTrk17BurstID "Front Long Range Radar Track 17 Burst ID";
BA_ "VNSigAllNodes" SG_ 1137 FLRRTrk17BurstID 1;
BA_ "SignalType" SG_ 1137 FLRRTrk17Range "UNM";
BA_ "SignalLongName" SG_ 1137 FLRRTrk17Range "Front Long Range Radar Track 17 Range";
BA_ "GenSigStartValue" SG_ 1137 FLRRTrk17Range 1;
BA_ "VNSigAllNodes" SG_ 1137 FLRRTrk17Range 1;
BA_ "SignalType" SG_ 1137 FLRRTrk17RangeRate "SNM";
BA_ "SignalLongName" SG_ 1137 FLRRTrk17RangeRate "Front Long Range Radar Track 17 Range Rate";
BA_ "VNSigAllNodes" SG_ 1137 FLRRTrk17RangeRate 1;
BA_ "SignalType" SG_ 1137 FLRRTrk17RangeAccel "SNM";
BA_ "SignalLongName" SG_ 1137 FLRRTrk17RangeAccel "Front Long Range Radar Track 17 Range Acceleration";
BA_ "VNSigAllNodes" SG_ 1137 FLRRTrk17RangeAccel 1;
BA_ "SignalType" SG_ 1137 FLRRTrk17DynProp "ENM";
BA_ "SignalLongName" SG_ 1137 FLRRTrk17DynProp "Front Long Range Radar Dynamic Property Track 17";
BA_ "VNSigAllNodes" SG_ 1137 FLRRTrk17DynProp 1;
BA_ "SignalType" SG_ 1137 FLRRTrk17Azimuth "SNM";
BA_ "SignalLongName" SG_ 1137 FLRRTrk17Azimuth "Front Long Range Radar Azimuth Track 17";
BA_ "VNSigAllNodes" SG_ 1137 FLRRTrk17Azimuth 1;
BA_ "SignalType" SG_ 1137 FLRRTrk17Width "UNM";
BA_ "SignalLongName" SG_ 1137 FLRRTrk17Width "Front Long Range Radar Track 17 Width";
BA_ "GenSigStartValue" SG_ 1137 FLRRTrk17Width 1;
BA_ "VNSigAllNodes" SG_ 1137 FLRRTrk17Width 1;
BA_ "SignalType" SG_ 1137 FLRRTrk17MeasStatus "ENM";
BA_ "SignalLongName" SG_ 1137 FLRRTrk17MeasStatus "Front Long Range Radar Measurement Status Track 17";
BA_ "VNSigAllNodes" SG_ 1137 FLRRTrk17MeasStatus 1;
BA_ "SignalType" SG_ 1137 FLRRTrk17ObjectID "UNM";
BA_ "SignalLongName" SG_ 1137 FLRRTrk17ObjectID "Front Long Range Radar Track 17 Object ID";
BA_ "VNSigAllNodes" SG_ 1137 FLRRTrk17ObjectID 1;
BA_ "SignalType" SG_ 1138 FLRRTrk18Conf "ENM";
BA_ "SignalLongName" SG_ 1138 FLRRTrk18Conf "Front Long Range Radar Track 18 Confidence";
BA_ "VNSigAllNodes" SG_ 1138 FLRRTrk18Conf 1;
BA_ "SignalType" SG_ 1138 FLRRTrk18BurstID "UNM";
BA_ "SignalLongName" SG_ 1138 FLRRTrk18BurstID "Front Long Range Radar Track 18 Burst ID";
BA_ "VNSigAllNodes" SG_ 1138 FLRRTrk18BurstID 1;
BA_ "SignalType" SG_ 1138 FLRRTrk18Range "UNM";
BA_ "SignalLongName" SG_ 1138 FLRRTrk18Range "Front Long Range Radar Track 18 Range";
BA_ "GenSigStartValue" SG_ 1138 FLRRTrk18Range 1;
BA_ "VNSigAllNodes" SG_ 1138 FLRRTrk18Range 1;
BA_ "SignalType" SG_ 1138 FLRRTrk18RangeRate "SNM";
BA_ "SignalLongName" SG_ 1138 FLRRTrk18RangeRate "Front Long Range Radar Track 18 Range Rate";
BA_ "VNSigAllNodes" SG_ 1138 FLRRTrk18RangeRate 1;
BA_ "SignalType" SG_ 1138 FLRRTrk18RangeAccel "SNM";
BA_ "SignalLongName" SG_ 1138 FLRRTrk18RangeAccel "Front Long Range Radar Track 18 Range Acceleration";
BA_ "VNSigAllNodes" SG_ 1138 FLRRTrk18RangeAccel 1;
BA_ "SignalType" SG_ 1138 FLRRTrk18DynProp "ENM";
BA_ "SignalLongName" SG_ 1138 FLRRTrk18DynProp "Front Long Range Radar Dynamic Property Track 18";
BA_ "VNSigAllNodes" SG_ 1138 FLRRTrk18DynProp 1;
BA_ "SignalType" SG_ 1138 FLRRTrk18Azimuth "SNM";
BA_ "SignalLongName" SG_ 1138 FLRRTrk18Azimuth "Front Long Range Radar Azimuth Track 18";
BA_ "VNSigAllNodes" SG_ 1138 FLRRTrk18Azimuth 1;
BA_ "SignalType" SG_ 1138 FLRRTrk18Width "UNM";
BA_ "SignalLongName" SG_ 1138 FLRRTrk18Width "Front Long Range Radar Track 18 Width";
BA_ "GenSigStartValue" SG_ 1138 FLRRTrk18Width 1;
BA_ "VNSigAllNodes" SG_ 1138 FLRRTrk18Width 1;
BA_ "SignalType" SG_ 1138 FLRRTrk18MeasStatus "ENM";
BA_ "SignalLongName" SG_ 1138 FLRRTrk18MeasStatus "Front Long Range Radar Measurement Status Track 18";
BA_ "VNSigAllNodes" SG_ 1138 FLRRTrk18MeasStatus 1;
BA_ "SignalType" SG_ 1138 FLRRTrk18ObjectID "UNM";
BA_ "SignalLongName" SG_ 1138 FLRRTrk18ObjectID "Front Long Range Radar Track 18 Object ID";
BA_ "VNSigAllNodes" SG_ 1138 FLRRTrk18ObjectID 1;
BA_ "SignalType" SG_ 1139 FLRRTrk19Conf "ENM";
BA_ "SignalLongName" SG_ 1139 FLRRTrk19Conf "Front Long Range Radar Track 19 Confidence";
BA_ "VNSigAllNodes" SG_ 1139 FLRRTrk19Conf 1;
BA_ "SignalType" SG_ 1139 FLRRTrk19BurstID "UNM";
BA_ "SignalLongName" SG_ 1139 FLRRTrk19BurstID "Front Long Range Radar Track 19 Burst ID";
BA_ "VNSigAllNodes" SG_ 1139 FLRRTrk19BurstID 1;
BA_ "SignalType" SG_ 1139 FLRRTrk19Range "UNM";
BA_ "SignalLongName" SG_ 1139 FLRRTrk19Range "Front Long Range Radar Track 19 Range";
BA_ "GenSigStartValue" SG_ 1139 FLRRTrk19Range 1;
BA_ "VNSigAllNodes" SG_ 1139 FLRRTrk19Range 1;
BA_ "SignalType" SG_ 1139 FLRRTrk19RangeRate "SNM";
BA_ "SignalLongName" SG_ 1139 FLRRTrk19RangeRate "Front Long Range Radar Track 19 Range Rate";
BA_ "VNSigAllNodes" SG_ 1139 FLRRTrk19RangeRate 1;
BA_ "SignalType" SG_ 1139 FLRRTrk19RangeAccel "SNM";
BA_ "SignalLongName" SG_ 1139 FLRRTrk19RangeAccel "Front Long Range Radar Track 19 Range Acceleration";
BA_ "VNSigAllNodes" SG_ 1139 FLRRTrk19RangeAccel 1;
BA_ "SignalType" SG_ 1139 FLRRTrk19DynProp "ENM";
BA_ "SignalLongName" SG_ 1139 FLRRTrk19DynProp "Front Long Range Radar Dynamic Property Track 19";
BA_ "VNSigAllNodes" SG_ 1139 FLRRTrk19DynProp 1;
BA_ "SignalType" SG_ 1139 FLRRTrk19Azimuth "SNM";
BA_ "SignalLongName" SG_ 1139 FLRRTrk19Azimuth "Front Long Range Radar Azimuth Track 19";
BA_ "VNSigAllNodes" SG_ 1139 FLRRTrk19Azimuth 1;
BA_ "SignalType" SG_ 1139 FLRRTrk19Width "UNM";
BA_ "SignalLongName" SG_ 1139 FLRRTrk19Width "Front Long Range Radar Track 19 Width";
BA_ "GenSigStartValue" SG_ 1139 FLRRTrk19Width 1;
BA_ "VNSigAllNodes" SG_ 1139 FLRRTrk19Width 1;
BA_ "SignalType" SG_ 1139 FLRRTrk19MeasStatus "ENM";
BA_ "SignalLongName" SG_ 1139 FLRRTrk19MeasStatus "Front Long Range Radar Measurement Status Track 19";
BA_ "VNSigAllNodes" SG_ 1139 FLRRTrk19MeasStatus 1;
BA_ "SignalType" SG_ 1139 FLRRTrk19ObjectID "UNM";
BA_ "SignalLongName" SG_ 1139 FLRRTrk19ObjectID "Front Long Range Radar Track 19 Object ID";
BA_ "VNSigAllNodes" SG_ 1139 FLRRTrk19ObjectID 1;
BA_ "SignalType" SG_ 1140 FLRRTrk20Conf "ENM";
BA_ "SignalLongName" SG_ 1140 FLRRTrk20Conf "Front Long Range Radar Track 20 Confidence";
BA_ "VNSigAllNodes" SG_ 1140 FLRRTrk20Conf 1;
BA_ "SignalType" SG_ 1140 FLRRTrk20BurstID "UNM";
BA_ "SignalLongName" SG_ 1140 FLRRTrk20BurstID "Front Long Range Radar Track 20 Burst ID";
BA_ "VNSigAllNodes" SG_ 1140 FLRRTrk20BurstID 1;
BA_ "SignalType" SG_ 1140 FLRRTrk20Range "UNM";
BA_ "SignalLongName" SG_ 1140 FLRRTrk20Range "Front Long Range Radar Track 20 Range";
BA_ "GenSigStartValue" SG_ 1140 FLRRTrk20Range 1;
BA_ "VNSigAllNodes" SG_ 1140 FLRRTrk20Range 1;
BA_ "SignalType" SG_ 1140 FLRRTrk20RangeRate "SNM";
BA_ "SignalLongName" SG_ 1140 FLRRTrk20RangeRate "Front Long Range Radar Track 20 Range Rate";
BA_ "VNSigAllNodes" SG_ 1140 FLRRTrk20RangeRate 1;
BA_ "SignalType" SG_ 1140 FLRRTrk20RangeAccel "SNM";
BA_ "SignalLongName" SG_ 1140 FLRRTrk20RangeAccel "Front Long Range Radar Track 20 Range Acceleration";
BA_ "VNSigAllNodes" SG_ 1140 FLRRTrk20RangeAccel 1;
BA_ "SignalType" SG_ 1140 FLRRTrk20DynProp "ENM";
BA_ "SignalLongName" SG_ 1140 FLRRTrk20DynProp "Front Long Range Radar Dynamic Property Track 20";
BA_ "VNSigAllNodes" SG_ 1140 FLRRTrk20DynProp 1;
BA_ "SignalType" SG_ 1140 FLRRTrk20Azimuth "SNM";
BA_ "SignalLongName" SG_ 1140 FLRRTrk20Azimuth "Front Long Range Radar Azimuth Track 20";
BA_ "VNSigAllNodes" SG_ 1140 FLRRTrk20Azimuth 1;
BA_ "SignalType" SG_ 1140 FLRRTrk20Width "UNM";
BA_ "SignalLongName" SG_ 1140 FLRRTrk20Width "Front Long Range Radar Track 20 Width";
BA_ "GenSigStartValue" SG_ 1140 FLRRTrk20Width 1;
BA_ "VNSigAllNodes" SG_ 1140 FLRRTrk20Width 1;
BA_ "SignalType" SG_ 1140 FLRRTrk20MeasStatus "ENM";
BA_ "SignalLongName" SG_ 1140 FLRRTrk20MeasStatus "Front Long Range Radar Measurement Status Track 20";
BA_ "VNSigAllNodes" SG_ 1140 FLRRTrk20MeasStatus 1;
BA_ "SignalType" SG_ 1140 FLRRTrk20ObjectID "UNM";
BA_ "SignalLongName" SG_ 1140 FLRRTrk20ObjectID "Front Long Range Radar Track 20 Object ID";
BA_ "VNSigAllNodes" SG_ 1140 FLRRTrk20ObjectID 1;
BA_ "SignalType" SG_ 1141 FLRRAddInfo1BurstID "UNM";
BA_ "SignalLongName" SG_ 1141 FLRRAddInfo1BurstID "Front Long Range Radar Additional Information 1 Burst ID";
BA_ "VNSigAllNodes" SG_ 1141 FLRRAddInfo1BurstID 1;
BA_ "SignalType" SG_ 1141 Cut_In_Out_Pot_Objtrk1 "UNM";
BA_ "SignalLongName" SG_ 1141 Cut_In_Out_Pot_Objtrk1 "Cut In Cut Out Potential Object Track 1";
BA_ "VNSigAllNodes" SG_ 1141 Cut_In_Out_Pot_Objtrk1 1;
BA_ "SignalType" SG_ 1141 ObjLossInfoObjTrk1 "ENM";
BA_ "SignalLongName" SG_ 1141 ObjLossInfoObjTrk1 "Object Loss Information Object Track 1";
BA_ "VNSigAllNodes" SG_ 1141 ObjLossInfoObjTrk1 1;
BA_ "SignalType" SG_ 1141 Cut_In_Out_Pot_Objtrk2 "UNM";
BA_ "SignalLongName" SG_ 1141 Cut_In_Out_Pot_Objtrk2 "Cut In Cut Out Potential Object Track 2";
BA_ "VNSigAllNodes" SG_ 1141 Cut_In_Out_Pot_Objtrk2 1;
BA_ "SignalType" SG_ 1141 ObjLossInfoObjTrk2 "ENM";
BA_ "SignalLongName" SG_ 1141 ObjLossInfoObjTrk2 "Object Loss Information Object Track 2";
BA_ "VNSigAllNodes" SG_ 1141 ObjLossInfoObjTrk2 1;
BA_ "SignalType" SG_ 1141 Cut_In_Out_Pot_Objtrk3 "UNM";
BA_ "SignalLongName" SG_ 1141 Cut_In_Out_Pot_Objtrk3 "Cut In Cut Out Potential Object Track 3";
BA_ "VNSigAllNodes" SG_ 1141 Cut_In_Out_Pot_Objtrk3 1;
BA_ "SignalType" SG_ 1141 ObjLossInfoObjTrk3 "ENM";
BA_ "SignalLongName" SG_ 1141 ObjLossInfoObjTrk3 "Object Loss Information Object Track 3";
BA_ "VNSigAllNodes" SG_ 1141 ObjLossInfoObjTrk3 1;
BA_ "SignalType" SG_ 1141 Cut_In_Out_Pot_Objtrk4 "UNM";
BA_ "SignalLongName" SG_ 1141 Cut_In_Out_Pot_Objtrk4 "Cut In Cut Out Potential Object Track 4";
BA_ "VNSigAllNodes" SG_ 1141 Cut_In_Out_Pot_Objtrk4 1;
BA_ "SignalType" SG_ 1141 ObjLossInfoObjTrk4 "ENM";
BA_ "SignalLongName" SG_ 1141 ObjLossInfoObjTrk4 "Object Loss Information Object Track 4";
BA_ "VNSigAllNodes" SG_ 1141 ObjLossInfoObjTrk4 1;
BA_ "SignalType" SG_ 1141 Cut_In_Out_Pot_Objtrk5 "UNM";
BA_ "SignalLongName" SG_ 1141 Cut_In_Out_Pot_Objtrk5 "Cut In Cut Out Potential Object Track 5";
BA_ "VNSigAllNodes" SG_ 1141 Cut_In_Out_Pot_Objtrk5 1;
BA_ "SignalType" SG_ 1141 ObjLossInfoObjTrk5 "ENM";
BA_ "SignalLongName" SG_ 1141 ObjLossInfoObjTrk5 "Object Loss Information Object Track 5";
BA_ "VNSigAllNodes" SG_ 1141 ObjLossInfoObjTrk5 1;
BA_ "SignalType" SG_ 1141 Cut_In_Out_Pot_Objtrk6 "UNM";
BA_ "SignalLongName" SG_ 1141 Cut_In_Out_Pot_Objtrk6 "Cut In Cut Out Potential Object Track 6";
BA_ "VNSigAllNodes" SG_ 1141 Cut_In_Out_Pot_Objtrk6 1;
BA_ "SignalType" SG_ 1141 ObjLossInfoObjTrk6 "ENM";
BA_ "SignalLongName" SG_ 1141 ObjLossInfoObjTrk6 "Object Loss Information Object Track 6";
BA_ "VNSigAllNodes" SG_ 1141 ObjLossInfoObjTrk6 1;
BA_ "SignalType" SG_ 1321 FwdFusTrkBAnlgRlLn9 "SNM";
BA_ "SignalLongName" SG_ 1321 FwdFusTrkBAnlgRlLn9 "Fwd Fusion Track B Analog relative Lane 9";
BA_ "VNSigAllNodes" SG_ 1321 FwdFusTrkBAnlgRlLn9 1;
BA_ "SignalType" SG_ 1321 FwdFusTrkB9RollingCnt "UNM";
BA_ "SignalLongName" SG_ 1321 FwdFusTrkB9RollingCnt "Forward Fusion Track B9 Rolling Count";
BA_ "VNSigAllNodes" SG_ 1321 FwdFusTrkB9RollingCnt 1;
BA_ "SignalType" SG_ 1321 FwdFusTrkB9Width "UNM";
BA_ "SignalLongName" SG_ 1321 FwdFusTrkB9Width "Forward Fusion Track B9 Width";
BA_ "GenSigStartValue" SG_ 1321 FwdFusTrkB9Width 1;
BA_ "VNSigAllNodes" SG_ 1321 FwdFusTrkB9Width 1;
BA_ "SignalType" SG_ 1321 FwdFusTrkB9MsgIndex "UNM";
BA_ "SignalLongName" SG_ 1321 FwdFusTrkB9MsgIndex "Forward Fusion Track B9 Message Index";
BA_ "VNSigAllNodes" SG_ 1321 FwdFusTrkB9MsgIndex 1;
BA_ "SignalType" SG_ 1321 FwdFusTrkB9DynProp "ENM";
BA_ "SignalLongName" SG_ 1321 FwdFusTrkB9DynProp "Forward Fusion Track B9 Dynamic Property";
BA_ "VNSigAllNodes" SG_ 1321 FwdFusTrkB9DynProp 1;
BA_ "SignalType" SG_ 1321 FwdFusTrkB9RelLnAccl "SNM";
BA_ "SignalLongName" SG_ 1321 FwdFusTrkB9RelLnAccl "Forward Fusion Track B9 Relative Lane Acceleration";
BA_ "VNSigAllNodes" SG_ 1321 FwdFusTrkB9RelLnAccl 1;
BA_ "SignalType" SG_ 1321 FwdFusTrkB9RelLane "ENM";
BA_ "SignalLongName" SG_ 1321 FwdFusTrkB9RelLane "Forward Fusion Track B9 Relative Lane";
BA_ "VNSigAllNodes" SG_ 1321 FwdFusTrkB9RelLane 1;
BA_ "SignalType" SG_ 1321 FwdFusTrkB9Height "UNM";
BA_ "SignalLongName" SG_ 1321 FwdFusTrkB9Height "Forward Fusion Track B9 Height";
BA_ "GenSigStartValue" SG_ 1321 FwdFusTrkB9Height 1;
BA_ "VNSigAllNodes" SG_ 1321 FwdFusTrkB9Height 1;
BA_ "SignalType" SG_ 1321 FFusTrkB9ObjSrcLFSrr "ENM";
BA_ "SignalLongName" SG_ 1321 FFusTrkB9ObjSrcLFSrr "Forward Fusion Track B9 Object Source LFSRR";
BA_ "VNSigAllNodes" SG_ 1321 FFusTrkB9ObjSrcLFSrr 1;
BA_ "SignalType" SG_ 1321 FFusTrkB9ObjSrcLCSrr "ENM";
BA_ "SignalLongName" SG_ 1321 FFusTrkB9ObjSrcLCSrr "Forward Fusion Track B9 Object Source LCSRR";
BA_ "VNSigAllNodes" SG_ 1321 FFusTrkB9ObjSrcLCSrr 1;
BA_ "SignalType" SG_ 1321 FFusTrkB9ObjSrcRCSrr "ENM";
BA_ "SignalLongName" SG_ 1321 FFusTrkB9ObjSrcRCSrr "Forward Fusion Track B9 Object Source RCSRR";
BA_ "VNSigAllNodes" SG_ 1321 FFusTrkB9ObjSrcRCSrr 1;
BA_ "SignalType" SG_ 1321 FFusTrkB9ObjSrcRFSrr "ENM";
BA_ "SignalLongName" SG_ 1321 FFusTrkB9ObjSrcRFSrr "Forward Fusion Track B9 Object Source RFSRR";
BA_ "VNSigAllNodes" SG_ 1321 FFusTrkB9ObjSrcRFSrr 1;
BA_ "SignalType" SG_ 1321 FFusTrkB9ObjSrcVIs "ENM";
BA_ "SignalLongName" SG_ 1321 FFusTrkB9ObjSrcVIs "Forward Fusion Track B9 Object Source VIS";
BA_ "VNSigAllNodes" SG_ 1321 FFusTrkB9ObjSrcVIs 1;
BA_ "SignalType" SG_ 1321 FwdFusTrkB9ObjSrcLrr "ENM";
BA_ "SignalLongName" SG_ 1321 FwdFusTrkB9ObjSrcLrr "Forward Fusion Track B9 Object Source LRR";
BA_ "VNSigAllNodes" SG_ 1321 FwdFusTrkB9ObjSrcLrr 1;
BA_ "SignalType" SG_ 1321 FwdFusTrkB9NmCycTrkd "UNM";
BA_ "SignalLongName" SG_ 1321 FwdFusTrkB9NmCycTrkd "Forward Fusion Track B9 Number of Cycles Tracked";
BA_ "VNSigAllNodes" SG_ 1321 FwdFusTrkB9NmCycTrkd 1;
BA_ "SignalType" SG_ 1321 FwdFusTrkB9LatPosDev "UNM";
BA_ "SignalLongName" SG_ 1321 FwdFusTrkB9LatPosDev "Forward Fusion Track B9 Lateral Positiion Deviation";
BA_ "VNSigAllNodes" SG_ 1321 FwdFusTrkB9LatPosDev 1;
BA_ "SignalType" SG_ 1321 FwdFusTrkB9LngPosDev "UNM";
BA_ "SignalLongName" SG_ 1321 FwdFusTrkB9LngPosDev "Forward Fusion Track B9 Longitudinal Position Deviation";
BA_ "VNSigAllNodes" SG_ 1321 FwdFusTrkB9LngPosDev 1;
BA_ "SignalType" SG_ 1320 FwdFusTrkBAnlgRlLn8 "SNM";
BA_ "SignalLongName" SG_ 1320 FwdFusTrkBAnlgRlLn8 "Fwd Fusion Track B Analog relative Lane 8";
BA_ "VNSigAllNodes" SG_ 1320 FwdFusTrkBAnlgRlLn8 1;
BA_ "SignalType" SG_ 1320 FwdFusTrkB8RollingCnt "UNM";
BA_ "SignalLongName" SG_ 1320 FwdFusTrkB8RollingCnt "Forward Fusion Track B8 Rolling Count";
BA_ "VNSigAllNodes" SG_ 1320 FwdFusTrkB8RollingCnt 1;
BA_ "SignalType" SG_ 1320 FwdFusTrkB8Width "UNM";
BA_ "SignalLongName" SG_ 1320 FwdFusTrkB8Width "Forward Fusion Track B8 Width";
BA_ "GenSigStartValue" SG_ 1320 FwdFusTrkB8Width 1;
BA_ "VNSigAllNodes" SG_ 1320 FwdFusTrkB8Width 1;
BA_ "SignalType" SG_ 1320 FwdFusTrkB8MsgIndex "UNM";
BA_ "SignalLongName" SG_ 1320 FwdFusTrkB8MsgIndex "Forward Fusion Track B8 Message Index";
BA_ "VNSigAllNodes" SG_ 1320 FwdFusTrkB8MsgIndex 1;
BA_ "SignalType" SG_ 1320 FwdFusTrkB8DynProp "ENM";
BA_ "SignalLongName" SG_ 1320 FwdFusTrkB8DynProp "Forward Fusion Track 8 Dynamic Property";
BA_ "VNSigAllNodes" SG_ 1320 FwdFusTrkB8DynProp 1;
BA_ "SignalType" SG_ 1320 FwdFusTrkB8RelLnAccl "SNM";
BA_ "SignalLongName" SG_ 1320 FwdFusTrkB8RelLnAccl "Forward Fusion Track B8 Relative Lane Acceleration";
BA_ "VNSigAllNodes" SG_ 1320 FwdFusTrkB8RelLnAccl 1;
BA_ "SignalType" SG_ 1320 FwdFusTrkB8RelLane "ENM";
BA_ "SignalLongName" SG_ 1320 FwdFusTrkB8RelLane "Forward Fusion Track B8 Relative Lane";
BA_ "VNSigAllNodes" SG_ 1320 FwdFusTrkB8RelLane 1;
BA_ "SignalType" SG_ 1320 FwdFusTrkB8Height "UNM";
BA_ "SignalLongName" SG_ 1320 FwdFusTrkB8Height "Forward Fusion Track B8 Height";
BA_ "GenSigStartValue" SG_ 1320 FwdFusTrkB8Height 1;
BA_ "VNSigAllNodes" SG_ 1320 FwdFusTrkB8Height 1;
BA_ "SignalType" SG_ 1320 FFusTrkB8ObjSrcLFSrr "ENM";
BA_ "SignalLongName" SG_ 1320 FFusTrkB8ObjSrcLFSrr "Forward Fusion Track B8 Object Source LFSRR";
BA_ "VNSigAllNodes" SG_ 1320 FFusTrkB8ObjSrcLFSrr 1;
BA_ "SignalType" SG_ 1320 FFusTrkB8ObjSrcLCSrr "ENM";
BA_ "SignalLongName" SG_ 1320 FFusTrkB8ObjSrcLCSrr "Forward Fusion Track B8 Object Source LCSRR";
BA_ "VNSigAllNodes" SG_ 1320 FFusTrkB8ObjSrcLCSrr 1;
BA_ "SignalType" SG_ 1320 FFusTrkB8ObjSrcRCSrr "ENM";
BA_ "SignalLongName" SG_ 1320 FFusTrkB8ObjSrcRCSrr "Forward Fusion Track B8 Object Source RCSRR";
BA_ "VNSigAllNodes" SG_ 1320 FFusTrkB8ObjSrcRCSrr 1;
BA_ "SignalType" SG_ 1320 FFusTrkB8ObjSrcRFSrr "ENM";
BA_ "SignalLongName" SG_ 1320 FFusTrkB8ObjSrcRFSrr "Forward Fusion Track B8 Object Source RFSRR";
BA_ "VNSigAllNodes" SG_ 1320 FFusTrkB8ObjSrcRFSrr 1;
BA_ "SignalType" SG_ 1320 FFusTrkB8ObjSrcVIs "ENM";
BA_ "SignalLongName" SG_ 1320 FFusTrkB8ObjSrcVIs "Forward Fusion Track B8 Object Source VIS";
BA_ "VNSigAllNodes" SG_ 1320 FFusTrkB8ObjSrcVIs 1;
BA_ "SignalType" SG_ 1320 FwdFusTrkB8ObjSrcLrr "ENM";
BA_ "SignalLongName" SG_ 1320 FwdFusTrkB8ObjSrcLrr "Forward Fusion Track B8 Object Source LRR";
BA_ "VNSigAllNodes" SG_ 1320 FwdFusTrkB8ObjSrcLrr 1;
BA_ "SignalType" SG_ 1320 FwdFusTrkB8NmCycTrkd "UNM";
BA_ "SignalLongName" SG_ 1320 FwdFusTrkB8NmCycTrkd "Forward Fusion Track B8 Number of Cycles Tracked";
BA_ "VNSigAllNodes" SG_ 1320 FwdFusTrkB8NmCycTrkd 1;
BA_ "SignalType" SG_ 1320 FwdFusTrkB8LatPosDev "UNM";
BA_ "SignalLongName" SG_ 1320 FwdFusTrkB8LatPosDev "Forward Fusion Track B8 Lateral Positiion Deviation";
BA_ "VNSigAllNodes" SG_ 1320 FwdFusTrkB8LatPosDev 1;
BA_ "SignalType" SG_ 1320 FwdFusTrkB8LngPosDev "UNM";
BA_ "SignalLongName" SG_ 1320 FwdFusTrkB8LngPosDev "Forward Fusion Track B8 Longitudinal Position Deviation";
BA_ "VNSigAllNodes" SG_ 1320 FwdFusTrkB8LngPosDev 1;
BA_ "SignalType" SG_ 1319 FwdFusTrkBAnlgRlLn7 "SNM";
BA_ "SignalLongName" SG_ 1319 FwdFusTrkBAnlgRlLn7 "Fwd Fusion Track B Analog relative Lane 7";
BA_ "VNSigAllNodes" SG_ 1319 FwdFusTrkBAnlgRlLn7 1;
BA_ "SignalType" SG_ 1319 FwdFusTrkB7RollingCnt "UNM";
BA_ "SignalLongName" SG_ 1319 FwdFusTrkB7RollingCnt "Forward Fusion Track B7 Rolling Count";
BA_ "VNSigAllNodes" SG_ 1319 FwdFusTrkB7RollingCnt 1;
BA_ "SignalType" SG_ 1319 FwdFusTrkB7Width "UNM";
BA_ "SignalLongName" SG_ 1319 FwdFusTrkB7Width "Forward Fusion Track B7 Width";
BA_ "GenSigStartValue" SG_ 1319 FwdFusTrkB7Width 1;
BA_ "VNSigAllNodes" SG_ 1319 FwdFusTrkB7Width 1;
BA_ "SignalType" SG_ 1319 FwdFusTrkB7MsgIndex "UNM";
BA_ "SignalLongName" SG_ 1319 FwdFusTrkB7MsgIndex "Forward Fusion Track B7 Message Index";
BA_ "VNSigAllNodes" SG_ 1319 FwdFusTrkB7MsgIndex 1;
BA_ "SignalType" SG_ 1319 FwdFusTrkB7DynProp "ENM";
BA_ "SignalLongName" SG_ 1319 FwdFusTrkB7DynProp "Forward Fusion Track B7 Dynamic Property";
BA_ "VNSigAllNodes" SG_ 1319 FwdFusTrkB7DynProp 1;
BA_ "SignalType" SG_ 1319 FwdFusTrkB7RelLnAccl "SNM";
BA_ "SignalLongName" SG_ 1319 FwdFusTrkB7RelLnAccl "Forward Fusion Track B7 Relative Lane Acceleration";
BA_ "VNSigAllNodes" SG_ 1319 FwdFusTrkB7RelLnAccl 1;
BA_ "SignalType" SG_ 1319 FwdFusTrkB7RelLane "ENM";
BA_ "SignalLongName" SG_ 1319 FwdFusTrkB7RelLane "Forward Fusion Track B7 Relative Lane";
BA_ "VNSigAllNodes" SG_ 1319 FwdFusTrkB7RelLane 1;
BA_ "SignalType" SG_ 1319 FwdFusTrkB7Height "UNM";
BA_ "SignalLongName" SG_ 1319 FwdFusTrkB7Height "Forward Fusion Track B7 Height";
BA_ "GenSigStartValue" SG_ 1319 FwdFusTrkB7Height 1;
BA_ "VNSigAllNodes" SG_ 1319 FwdFusTrkB7Height 1;
BA_ "SignalType" SG_ 1319 FFusTrkB7ObjSrcLFSrr "ENM";
BA_ "SignalLongName" SG_ 1319 FFusTrkB7ObjSrcLFSrr "Forward Fusion Track B7 Object Source LFSRR";
BA_ "VNSigAllNodes" SG_ 1319 FFusTrkB7ObjSrcLFSrr 1;
BA_ "SignalType" SG_ 1319 FFusTrkB7ObjSrcLCSrr "ENM";
BA_ "SignalLongName" SG_ 1319 FFusTrkB7ObjSrcLCSrr "Forward Fusion Track B7 Object Source LCSRR";
BA_ "VNSigAllNodes" SG_ 1319 FFusTrkB7ObjSrcLCSrr 1;
BA_ "SignalType" SG_ 1319 FFusTrkB7ObjSrcRCSrr "ENM";
BA_ "SignalLongName" SG_ 1319 FFusTrkB7ObjSrcRCSrr "Forward Fusion Track B7 Object Source RCSRR";
BA_ "VNSigAllNodes" SG_ 1319 FFusTrkB7ObjSrcRCSrr 1;
BA_ "SignalType" SG_ 1319 FFusTrkB7ObjSrcRFSrr "ENM";
BA_ "SignalLongName" SG_ 1319 FFusTrkB7ObjSrcRFSrr "Forward Fusion Track B7 Object Source RFSRR";
BA_ "VNSigAllNodes" SG_ 1319 FFusTrkB7ObjSrcRFSrr 1;
BA_ "SignalType" SG_ 1319 FFusTrkB7ObjSrcVIs "ENM";
BA_ "SignalLongName" SG_ 1319 FFusTrkB7ObjSrcVIs "Forward Fusion Track B7 Object Source VIS";
BA_ "VNSigAllNodes" SG_ 1319 FFusTrkB7ObjSrcVIs 1;
BA_ "SignalType" SG_ 1319 FwdFusTrkB7ObjSrcLrr "ENM";
BA_ "SignalLongName" SG_ 1319 FwdFusTrkB7ObjSrcLrr "Forward Fusion Track B7 Object Source LRR";
BA_ "VNSigAllNodes" SG_ 1319 FwdFusTrkB7ObjSrcLrr 1;
BA_ "SignalType" SG_ 1319 FwdFusTrkB7NmCycTrkd "UNM";
BA_ "SignalLongName" SG_ 1319 FwdFusTrkB7NmCycTrkd "Forward Fusion Track B7 Number of Cycles Tracked";
BA_ "VNSigAllNodes" SG_ 1319 FwdFusTrkB7NmCycTrkd 1;
BA_ "SignalType" SG_ 1319 FwdFusTrkB7LatPosDev "UNM";
BA_ "SignalLongName" SG_ 1319 FwdFusTrkB7LatPosDev "Forward Fusion Track B7 Lateral Positiion Deviation";
BA_ "VNSigAllNodes" SG_ 1319 FwdFusTrkB7LatPosDev 1;
BA_ "SignalType" SG_ 1319 FwdFusTrkB7LngPosDev "UNM";
BA_ "SignalLongName" SG_ 1319 FwdFusTrkB7LngPosDev "Forward Fusion Track B7 Longitudinal Position Deviation";
BA_ "VNSigAllNodes" SG_ 1319 FwdFusTrkB7LngPosDev 1;
BA_ "SignalType" SG_ 1318 FwdFusTrkBAnlgRlLn6 "SNM";
BA_ "SignalLongName" SG_ 1318 FwdFusTrkBAnlgRlLn6 "Fwd Fusion Track B Analog relative Lane 6";
BA_ "VNSigAllNodes" SG_ 1318 FwdFusTrkBAnlgRlLn6 1;
BA_ "SignalType" SG_ 1318 FwdFusTrkB6RollingCnt "UNM";
BA_ "SignalLongName" SG_ 1318 FwdFusTrkB6RollingCnt "Forward Fusion Track B6 Rolling Count";
BA_ "VNSigAllNodes" SG_ 1318 FwdFusTrkB6RollingCnt 1;
BA_ "SignalType" SG_ 1318 FwdFusTrkB6Width "UNM";
BA_ "SignalLongName" SG_ 1318 FwdFusTrkB6Width "Forward Fusion Track B6 Width";
BA_ "GenSigStartValue" SG_ 1318 FwdFusTrkB6Width 1;
BA_ "VNSigAllNodes" SG_ 1318 FwdFusTrkB6Width 1;
BA_ "SignalType" SG_ 1318 FwdFusTrkB6MsgIndex "UNM";
BA_ "SignalLongName" SG_ 1318 FwdFusTrkB6MsgIndex "Forward Fusion Track B6 Message Index";
BA_ "VNSigAllNodes" SG_ 1318 FwdFusTrkB6MsgIndex 1;
BA_ "SignalType" SG_ 1318 FwdFusTrkB6DynProp "ENM";
BA_ "SignalLongName" SG_ 1318 FwdFusTrkB6DynProp "Forward Fusion Track B6 Dynamic Property";
BA_ "VNSigAllNodes" SG_ 1318 FwdFusTrkB6DynProp 1;
BA_ "SignalType" SG_ 1318 FwdFusTrkB6RelLnAccl "SNM";
BA_ "SignalLongName" SG_ 1318 FwdFusTrkB6RelLnAccl "Forward Fusion Track B6 Relative Lane Acceleration";
BA_ "VNSigAllNodes" SG_ 1318 FwdFusTrkB6RelLnAccl 1;
BA_ "SignalType" SG_ 1318 FwdFusTrkB6RelLane "ENM";
BA_ "SignalLongName" SG_ 1318 FwdFusTrkB6RelLane "Forward Fusion Track B6 Relative Lane";
BA_ "VNSigAllNodes" SG_ 1318 FwdFusTrkB6RelLane 1;
BA_ "SignalType" SG_ 1318 FwdFusTrkB6Height "UNM";
BA_ "SignalLongName" SG_ 1318 FwdFusTrkB6Height "Forward Fusion Track B6 Height";
BA_ "GenSigStartValue" SG_ 1318 FwdFusTrkB6Height 1;
BA_ "VNSigAllNodes" SG_ 1318 FwdFusTrkB6Height 1;
BA_ "SignalType" SG_ 1318 FFusTrkB6ObjSrcLFSrr "ENM";
BA_ "SignalLongName" SG_ 1318 FFusTrkB6ObjSrcLFSrr "Forward Fusion Track B6 Object Source LFSRR";
BA_ "VNSigAllNodes" SG_ 1318 FFusTrkB6ObjSrcLFSrr 1;
BA_ "SignalType" SG_ 1318 FFusTrkB6ObjSrcLCSrr "ENM";
BA_ "SignalLongName" SG_ 1318 FFusTrkB6ObjSrcLCSrr "Forward Fusion Track B6 Object Source LCSRR";
BA_ "VNSigAllNodes" SG_ 1318 FFusTrkB6ObjSrcLCSrr 1;
BA_ "SignalType" SG_ 1318 FFusTrkB6ObjSrcRCSrr "ENM";
BA_ "SignalLongName" SG_ 1318 FFusTrkB6ObjSrcRCSrr "Forward Fusion Track B6 Object Source RCSRR";
BA_ "VNSigAllNodes" SG_ 1318 FFusTrkB6ObjSrcRCSrr 1;
BA_ "SignalType" SG_ 1318 FFusTrkB6ObjSrcRFSrr "ENM";
BA_ "SignalLongName" SG_ 1318 FFusTrkB6ObjSrcRFSrr "Forward Fusion Track B6 Object Source RFSRR";
BA_ "VNSigAllNodes" SG_ 1318 FFusTrkB6ObjSrcRFSrr 1;
BA_ "SignalType" SG_ 1318 FFusTrkB6ObjSrcVIs "ENM";
BA_ "SignalLongName" SG_ 1318 FFusTrkB6ObjSrcVIs "Forward Fusion Track B6 Object Source VIS";
BA_ "VNSigAllNodes" SG_ 1318 FFusTrkB6ObjSrcVIs 1;
BA_ "SignalType" SG_ 1318 FwdFusTrkB6ObjSrcLrr "ENM";
BA_ "SignalLongName" SG_ 1318 FwdFusTrkB6ObjSrcLrr "Forward Fusion Track B6 Object Source LRR";
BA_ "VNSigAllNodes" SG_ 1318 FwdFusTrkB6ObjSrcLrr 1;
BA_ "SignalType" SG_ 1318 FwdFusTrkB6NmCycTrkd "UNM";
BA_ "SignalLongName" SG_ 1318 FwdFusTrkB6NmCycTrkd "Forward Fusion Track B6 Number of Cycles Tracked";
BA_ "VNSigAllNodes" SG_ 1318 FwdFusTrkB6NmCycTrkd 1;
BA_ "SignalType" SG_ 1318 FwdFusTrkB6LatPosDev "UNM";
BA_ "SignalLongName" SG_ 1318 FwdFusTrkB6LatPosDev "Forward Fusion Track B6 Lateral Positiion Deviation";
BA_ "VNSigAllNodes" SG_ 1318 FwdFusTrkB6LatPosDev 1;
BA_ "SignalType" SG_ 1318 FwdFusTrkB6LngPosDev "UNM";
BA_ "SignalLongName" SG_ 1318 FwdFusTrkB6LngPosDev "Forward Fusion Track B6 Longitudinal Position Deviation";
BA_ "VNSigAllNodes" SG_ 1318 FwdFusTrkB6LngPosDev 1;
BA_ "SignalType" SG_ 1317 FwdFusTrkBAnlgRlLn5 "SNM";
BA_ "SignalLongName" SG_ 1317 FwdFusTrkBAnlgRlLn5 "Fwd Fusion Track B Analog relative Lane 5";
BA_ "VNSigAllNodes" SG_ 1317 FwdFusTrkBAnlgRlLn5 1;
BA_ "SignalType" SG_ 1317 FwdFusTrkB5RollingCnt "UNM";
BA_ "SignalLongName" SG_ 1317 FwdFusTrkB5RollingCnt "Forward Fusion Track B5 Rolling Count";
BA_ "VNSigAllNodes" SG_ 1317 FwdFusTrkB5RollingCnt 1;
BA_ "SignalType" SG_ 1317 FwdFusTrkB5Width "UNM";
BA_ "SignalLongName" SG_ 1317 FwdFusTrkB5Width "Forward Fusion Track B5 Width";
BA_ "GenSigStartValue" SG_ 1317 FwdFusTrkB5Width 1;
BA_ "VNSigAllNodes" SG_ 1317 FwdFusTrkB5Width 1;
BA_ "SignalType" SG_ 1317 FwdFusTrkB5MsgIndex "UNM";
BA_ "SignalLongName" SG_ 1317 FwdFusTrkB5MsgIndex "Forward Fusion Track B5 Message Index";
BA_ "VNSigAllNodes" SG_ 1317 FwdFusTrkB5MsgIndex 1;
BA_ "SignalType" SG_ 1317 FwdFusTrkB5DynProp "ENM";
BA_ "SignalLongName" SG_ 1317 FwdFusTrkB5DynProp "Forward Fusion Track B5 Dynamic Property";
BA_ "VNSigAllNodes" SG_ 1317 FwdFusTrkB5DynProp 1;
BA_ "SignalType" SG_ 1317 FwdFusTrkB5RelLnAccl "SNM";
BA_ "SignalLongName" SG_ 1317 FwdFusTrkB5RelLnAccl "Forward Fusion Track B5 Relative Lane Acceleration";
BA_ "VNSigAllNodes" SG_ 1317 FwdFusTrkB5RelLnAccl 1;
BA_ "SignalType" SG_ 1317 FwdFusTrkB5RelLane "ENM";
BA_ "SignalLongName" SG_ 1317 FwdFusTrkB5RelLane "Forward Fusion Track B5 Relative Lane";
BA_ "VNSigAllNodes" SG_ 1317 FwdFusTrkB5RelLane 1;
BA_ "SignalType" SG_ 1317 FwdFusTrkB5Height "UNM";
BA_ "SignalLongName" SG_ 1317 FwdFusTrkB5Height "Forward Fusion Track B5 Height";
BA_ "GenSigStartValue" SG_ 1317 FwdFusTrkB5Height 1;
BA_ "VNSigAllNodes" SG_ 1317 FwdFusTrkB5Height 1;
BA_ "SignalType" SG_ 1317 FFusTrkB5ObjSrcLFSrr "ENM";
BA_ "SignalLongName" SG_ 1317 FFusTrkB5ObjSrcLFSrr "Forward Fusion Track B5 Object Source LFSRR";
BA_ "VNSigAllNodes" SG_ 1317 FFusTrkB5ObjSrcLFSrr 1;
BA_ "SignalType" SG_ 1317 FFusTrkB5ObjSrcLCSrr "ENM";
BA_ "SignalLongName" SG_ 1317 FFusTrkB5ObjSrcLCSrr "Forward Fusion Track B5 Object Source LCSRR";
BA_ "VNSigAllNodes" SG_ 1317 FFusTrkB5ObjSrcLCSrr 1;
BA_ "SignalType" SG_ 1317 FFusTrkB5ObjSrcRCSrr "ENM";
BA_ "SignalLongName" SG_ 1317 FFusTrkB5ObjSrcRCSrr "Forward Fusion Track B5 Object Source RCSRR";
BA_ "VNSigAllNodes" SG_ 1317 FFusTrkB5ObjSrcRCSrr 1;
BA_ "SignalType" SG_ 1317 FFusTrkB5ObjSrcRFSrr "ENM";
BA_ "SignalLongName" SG_ 1317 FFusTrkB5ObjSrcRFSrr "Forward Fusion Track B5 Object Source RFSRR";
BA_ "VNSigAllNodes" SG_ 1317 FFusTrkB5ObjSrcRFSrr 1;
BA_ "SignalType" SG_ 1317 FFusTrkB5ObjSrcVIs "ENM";
BA_ "SignalLongName" SG_ 1317 FFusTrkB5ObjSrcVIs "Forward Fusion Track B5 Object Source VIS";
BA_ "VNSigAllNodes" SG_ 1317 FFusTrkB5ObjSrcVIs 1;
BA_ "SignalType" SG_ 1317 FwdFusTrkB5ObjSrcLrr "ENM";
BA_ "SignalLongName" SG_ 1317 FwdFusTrkB5ObjSrcLrr "Forward Fusion Track B5 Object Source LRR";
BA_ "VNSigAllNodes" SG_ 1317 FwdFusTrkB5ObjSrcLrr 1;
BA_ "SignalType" SG_ 1317 FwdFusTrkB5NmCycTrkd "UNM";
BA_ "SignalLongName" SG_ 1317 FwdFusTrkB5NmCycTrkd "Forward Fusion Track B5 Number of Cycles Tracked";
BA_ "VNSigAllNodes" SG_ 1317 FwdFusTrkB5NmCycTrkd 1;
BA_ "SignalType" SG_ 1317 FwdFusTrkB5LatPosDev "UNM";
BA_ "SignalLongName" SG_ 1317 FwdFusTrkB5LatPosDev "Forward Fusion Track B5 Lateral Positiion Deviation";
BA_ "VNSigAllNodes" SG_ 1317 FwdFusTrkB5LatPosDev 1;
BA_ "SignalType" SG_ 1317 FwdFusTrkB5LngPosDev "UNM";
BA_ "SignalLongName" SG_ 1317 FwdFusTrkB5LngPosDev "Forward Fusion Track B5 Longitudinal Position Deviation";
BA_ "VNSigAllNodes" SG_ 1317 FwdFusTrkB5LngPosDev 1;
BA_ "SignalType" SG_ 1316 FwdFusTrkBAnlgRlLn4 "SNM";
BA_ "SignalLongName" SG_ 1316 FwdFusTrkBAnlgRlLn4 "Fwd Fusion Track B Analog relative Lane 4";
BA_ "VNSigAllNodes" SG_ 1316 FwdFusTrkBAnlgRlLn4 1;
BA_ "SignalType" SG_ 1316 FwdFusTrkB4RollingCnt "UNM";
BA_ "SignalLongName" SG_ 1316 FwdFusTrkB4RollingCnt "Forward Fusion Track B4 Rolling Count";
BA_ "VNSigAllNodes" SG_ 1316 FwdFusTrkB4RollingCnt 1;
BA_ "SignalType" SG_ 1316 FwdFusTrkB4Width "UNM";
BA_ "SignalLongName" SG_ 1316 FwdFusTrkB4Width "Forward Fusion Track B4 Width";
BA_ "GenSigStartValue" SG_ 1316 FwdFusTrkB4Width 1;
BA_ "VNSigAllNodes" SG_ 1316 FwdFusTrkB4Width 1;
BA_ "SignalType" SG_ 1316 FwdFusTrkB4MsgIndex "UNM";
BA_ "SignalLongName" SG_ 1316 FwdFusTrkB4MsgIndex "Forward Fusion Track B4 Message Index";
BA_ "VNSigAllNodes" SG_ 1316 FwdFusTrkB4MsgIndex 1;
BA_ "SignalType" SG_ 1316 FwdFusTrkB4DynProp "ENM";
BA_ "SignalLongName" SG_ 1316 FwdFusTrkB4DynProp "Forward Fusion Track B4 Dynamic Property";
BA_ "VNSigAllNodes" SG_ 1316 FwdFusTrkB4DynProp 1;
BA_ "SignalType" SG_ 1316 FwdFusTrkB4RelLnAccl "SNM";
BA_ "SignalLongName" SG_ 1316 FwdFusTrkB4RelLnAccl "Forward Fusion Track B4 Relative Lane Acceleration";
BA_ "VNSigAllNodes" SG_ 1316 FwdFusTrkB4RelLnAccl 1;
BA_ "SignalType" SG_ 1316 FwdFusTrkB4RelLane "ENM";
BA_ "SignalLongName" SG_ 1316 FwdFusTrkB4RelLane "Forward Fusion Track B4 Relative Lane";
BA_ "VNSigAllNodes" SG_ 1316 FwdFusTrkB4RelLane 1;
BA_ "SignalType" SG_ 1316 FwdFusTrkB4Height "UNM";
BA_ "SignalLongName" SG_ 1316 FwdFusTrkB4Height "Forward Fusion Track B4 Height";
BA_ "GenSigStartValue" SG_ 1316 FwdFusTrkB4Height 1;
BA_ "VNSigAllNodes" SG_ 1316 FwdFusTrkB4Height 1;
BA_ "SignalType" SG_ 1316 FFusTrkB4ObjSrcLFSrr "ENM";
BA_ "SignalLongName" SG_ 1316 FFusTrkB4ObjSrcLFSrr "Forward Fusion Track B4 Object Source LFSRR";
BA_ "VNSigAllNodes" SG_ 1316 FFusTrkB4ObjSrcLFSrr 1;
BA_ "SignalType" SG_ 1316 FFusTrkB4ObjSrcLCSrr "ENM";
BA_ "SignalLongName" SG_ 1316 FFusTrkB4ObjSrcLCSrr "Forward Fusion Track B4 Object Source LCSRR";
BA_ "VNSigAllNodes" SG_ 1316 FFusTrkB4ObjSrcLCSrr 1;
BA_ "SignalType" SG_ 1316 FFusTrkB4ObjSrcRCSrr "ENM";
BA_ "SignalLongName" SG_ 1316 FFusTrkB4ObjSrcRCSrr "Forward Fusion Track B4 Object Source RCSRR";
BA_ "VNSigAllNodes" SG_ 1316 FFusTrkB4ObjSrcRCSrr 1;
BA_ "SignalType" SG_ 1316 FFusTrkB4ObjSrcRFSrr "ENM";
BA_ "SignalLongName" SG_ 1316 FFusTrkB4ObjSrcRFSrr "Forward Fusion Track B4 Object Source RFSRR";
BA_ "VNSigAllNodes" SG_ 1316 FFusTrkB4ObjSrcRFSrr 1;
BA_ "SignalType" SG_ 1316 FFusTrkB4ObjSrcVIs "ENM";
BA_ "SignalLongName" SG_ 1316 FFusTrkB4ObjSrcVIs "Forward Fusion Track B4 Object Source VIS";
BA_ "VNSigAllNodes" SG_ 1316 FFusTrkB4ObjSrcVIs 1;
BA_ "SignalType" SG_ 1316 FwdFusTrkB4ObjSrcLrr "ENM";
BA_ "SignalLongName" SG_ 1316 FwdFusTrkB4ObjSrcLrr "Forward Fusion Track B4 Object Source LRR";
BA_ "VNSigAllNodes" SG_ 1316 FwdFusTrkB4ObjSrcLrr 1;
BA_ "SignalType" SG_ 1316 FwdFusTrkB4NmCycTrkd "UNM";
BA_ "SignalLongName" SG_ 1316 FwdFusTrkB4NmCycTrkd "Forward Fusion Track B4 Number of Cycles Tracked";
BA_ "VNSigAllNodes" SG_ 1316 FwdFusTrkB4NmCycTrkd 1;
BA_ "SignalType" SG_ 1316 FwdFusTrkB4LatPosDev "UNM";
BA_ "SignalLongName" SG_ 1316 FwdFusTrkB4LatPosDev "Forward Fusion Track B4 Lateral Positiion Deviation";
BA_ "VNSigAllNodes" SG_ 1316 FwdFusTrkB4LatPosDev 1;
BA_ "SignalType" SG_ 1316 FwdFusTrkB4LngPosDev "UNM";
BA_ "SignalLongName" SG_ 1316 FwdFusTrkB4LngPosDev "Forward Fusion Track B4 Longitudinal Position Deviation";
BA_ "VNSigAllNodes" SG_ 1316 FwdFusTrkB4LngPosDev 1;
BA_ "SignalType" SG_ 1315 FwdFusTrkBAnlgRlLn3 "SNM";
BA_ "SignalLongName" SG_ 1315 FwdFusTrkBAnlgRlLn3 "Fwd Fusion Track B Analog relative Lane 3";
BA_ "VNSigAllNodes" SG_ 1315 FwdFusTrkBAnlgRlLn3 1;
BA_ "SignalType" SG_ 1315 FwdFusTrkB3RollingCnt "UNM";
BA_ "SignalLongName" SG_ 1315 FwdFusTrkB3RollingCnt "Forward Fusion Track B3 Rolling Count";
BA_ "VNSigAllNodes" SG_ 1315 FwdFusTrkB3RollingCnt 1;
BA_ "SignalType" SG_ 1315 FwdFusTrkB3Width "UNM";
BA_ "SignalLongName" SG_ 1315 FwdFusTrkB3Width "Forward Fusion Track B3 Width";
BA_ "GenSigStartValue" SG_ 1315 FwdFusTrkB3Width 1;
BA_ "VNSigAllNodes" SG_ 1315 FwdFusTrkB3Width 1;
BA_ "SignalType" SG_ 1315 FwdFusTrkB3MsgIndex "UNM";
BA_ "SignalLongName" SG_ 1315 FwdFusTrkB3MsgIndex "Forward Fusion Track B3 Message Index";
BA_ "VNSigAllNodes" SG_ 1315 FwdFusTrkB3MsgIndex 1;
BA_ "SignalType" SG_ 1315 FwdFusTrkB3DynProp "ENM";
BA_ "SignalLongName" SG_ 1315 FwdFusTrkB3DynProp "Forward Fusion Track B3 Dynamic Property";
BA_ "VNSigAllNodes" SG_ 1315 FwdFusTrkB3DynProp 1;
BA_ "SignalType" SG_ 1315 FwdFusTrkB3RelLnAccl "SNM";
BA_ "SignalLongName" SG_ 1315 FwdFusTrkB3RelLnAccl "Forward Fusion Track B3 Relative Lane Acceleration";
BA_ "VNSigAllNodes" SG_ 1315 FwdFusTrkB3RelLnAccl 1;
BA_ "SignalType" SG_ 1315 FwdFusTrkB3RelLane "ENM";
BA_ "SignalLongName" SG_ 1315 FwdFusTrkB3RelLane "Forward Fusion Track B3 Relative Lane";
BA_ "VNSigAllNodes" SG_ 1315 FwdFusTrkB3RelLane 1;
BA_ "SignalType" SG_ 1315 FwdFusTrkB3Height "UNM";
BA_ "SignalLongName" SG_ 1315 FwdFusTrkB3Height "Forward Fusion Track B3 Height";
BA_ "GenSigStartValue" SG_ 1315 FwdFusTrkB3Height 1;
BA_ "VNSigAllNodes" SG_ 1315 FwdFusTrkB3Height 1;
BA_ "SignalType" SG_ 1315 FFusTrkB3ObjSrcLFSrr "ENM";
BA_ "SignalLongName" SG_ 1315 FFusTrkB3ObjSrcLFSrr "Forward Fusion Track B3 Object Source LFSRR";
BA_ "VNSigAllNodes" SG_ 1315 FFusTrkB3ObjSrcLFSrr 1;
BA_ "SignalType" SG_ 1315 FFusTrkB3ObjSrcLCSrr "ENM";
BA_ "SignalLongName" SG_ 1315 FFusTrkB3ObjSrcLCSrr "Forward Fusion Track B3 Object Source LCSRR";
BA_ "VNSigAllNodes" SG_ 1315 FFusTrkB3ObjSrcLCSrr 1;
BA_ "SignalType" SG_ 1315 FFusTrkB3ObjSrcRCSrr "ENM";
BA_ "SignalLongName" SG_ 1315 FFusTrkB3ObjSrcRCSrr "Forward Fusion Track B3 Object Source RCSRR";
BA_ "VNSigAllNodes" SG_ 1315 FFusTrkB3ObjSrcRCSrr 1;
BA_ "SignalType" SG_ 1315 FFusTrkB3ObjSrcRFSrr "ENM";
BA_ "SignalLongName" SG_ 1315 FFusTrkB3ObjSrcRFSrr "Forward Fusion Track B3 Object Source RFSRR";
BA_ "VNSigAllNodes" SG_ 1315 FFusTrkB3ObjSrcRFSrr 1;
BA_ "SignalType" SG_ 1315 FFusTrkB3ObjSrcVIs "ENM";
BA_ "SignalLongName" SG_ 1315 FFusTrkB3ObjSrcVIs "Forward Fusion Track B3 Object Source VIS";
BA_ "VNSigAllNodes" SG_ 1315 FFusTrkB3ObjSrcVIs 1;
BA_ "SignalType" SG_ 1315 FwdFusTrkB3ObjSrcLrr "ENM";
BA_ "SignalLongName" SG_ 1315 FwdFusTrkB3ObjSrcLrr "Forward Fusion Track B3 Object Source LRR";
BA_ "VNSigAllNodes" SG_ 1315 FwdFusTrkB3ObjSrcLrr 1;
BA_ "SignalType" SG_ 1315 FwdFusTrkB3NmCycTrkd "UNM";
BA_ "SignalLongName" SG_ 1315 FwdFusTrkB3NmCycTrkd "Forward Fusion Track B3 Number of Cycles Tracked";
BA_ "VNSigAllNodes" SG_ 1315 FwdFusTrkB3NmCycTrkd 1;
BA_ "SignalType" SG_ 1315 FwdFusTrkB3LatPosDev "UNM";
BA_ "SignalLongName" SG_ 1315 FwdFusTrkB3LatPosDev "Forward Fusion Track B3 Lateral Positiion Deviation";
BA_ "VNSigAllNodes" SG_ 1315 FwdFusTrkB3LatPosDev 1;
BA_ "SignalType" SG_ 1315 FwdFusTrkB3LngPosDev "UNM";
BA_ "SignalLongName" SG_ 1315 FwdFusTrkB3LngPosDev "Forward Fusion Track B3 Longitudinal Position Deviation";
BA_ "VNSigAllNodes" SG_ 1315 FwdFusTrkB3LngPosDev 1;
BA_ "SignalType" SG_ 1314 FwdFusTrkBAnlgRlLn2 "SNM";
BA_ "SignalLongName" SG_ 1314 FwdFusTrkBAnlgRlLn2 "Fwd Fusion Track B Analog relative Lane 2";
BA_ "VNSigAllNodes" SG_ 1314 FwdFusTrkBAnlgRlLn2 1;
BA_ "SignalType" SG_ 1314 FwdFusTrkB2RollingCnt "UNM";
BA_ "SignalLongName" SG_ 1314 FwdFusTrkB2RollingCnt "Forward Fusion Track B2 Rolling Count";
BA_ "VNSigAllNodes" SG_ 1314 FwdFusTrkB2RollingCnt 1;
BA_ "SignalType" SG_ 1314 FwdFusTrkB2Width "UNM";
BA_ "SignalLongName" SG_ 1314 FwdFusTrkB2Width "Forward Fusion Track B2 Width";
BA_ "GenSigStartValue" SG_ 1314 FwdFusTrkB2Width 1;
BA_ "VNSigAllNodes" SG_ 1314 FwdFusTrkB2Width 1;
BA_ "SignalType" SG_ 1314 FwdFusTrkB2MsgIndex "UNM";
BA_ "SignalLongName" SG_ 1314 FwdFusTrkB2MsgIndex "Forward Fusion Track B2 Message Index";
BA_ "VNSigAllNodes" SG_ 1314 FwdFusTrkB2MsgIndex 1;
BA_ "SignalType" SG_ 1314 FwdFusTrkB2DynProp "ENM";
BA_ "SignalLongName" SG_ 1314 FwdFusTrkB2DynProp "Forward Fusion Track B2 Dynamic Property";
BA_ "VNSigAllNodes" SG_ 1314 FwdFusTrkB2DynProp 1;
BA_ "SignalType" SG_ 1314 FwdFusTrkB2RelLnAccl "SNM";
BA_ "SignalLongName" SG_ 1314 FwdFusTrkB2RelLnAccl "Forward Fusion Track B2 Relative Lane Acceleration";
BA_ "VNSigAllNodes" SG_ 1314 FwdFusTrkB2RelLnAccl 1;
BA_ "SignalType" SG_ 1314 FwdFusTrkB2RelLane "ENM";
BA_ "SignalLongName" SG_ 1314 FwdFusTrkB2RelLane "Forward Fusion Track B2 Relative Lane";
BA_ "VNSigAllNodes" SG_ 1314 FwdFusTrkB2RelLane 1;
BA_ "SignalType" SG_ 1314 FwdFusTrkB2Height "UNM";
BA_ "SignalLongName" SG_ 1314 FwdFusTrkB2Height "Forward Fusion Track B2 Height";
BA_ "GenSigStartValue" SG_ 1314 FwdFusTrkB2Height 1;
BA_ "VNSigAllNodes" SG_ 1314 FwdFusTrkB2Height 1;
BA_ "SignalType" SG_ 1314 FFusTrkB2ObjSrcLFSrr "ENM";
BA_ "SignalLongName" SG_ 1314 FFusTrkB2ObjSrcLFSrr "Forward Fusion Track B2 Object Source LFSRR";
BA_ "VNSigAllNodes" SG_ 1314 FFusTrkB2ObjSrcLFSrr 1;
BA_ "SignalType" SG_ 1314 FFusTrkB2ObjSrcLCSrr "ENM";
BA_ "SignalLongName" SG_ 1314 FFusTrkB2ObjSrcLCSrr "Forward Fusion Track B2 Object Source LCSRR";
BA_ "VNSigAllNodes" SG_ 1314 FFusTrkB2ObjSrcLCSrr 1;
BA_ "SignalType" SG_ 1314 FFusTrkB2ObjSrcRCSrr "ENM";
BA_ "SignalLongName" SG_ 1314 FFusTrkB2ObjSrcRCSrr "Forward Fusion Track B2 Object Source RCSRR";
BA_ "VNSigAllNodes" SG_ 1314 FFusTrkB2ObjSrcRCSrr 1;
BA_ "SignalType" SG_ 1314 FFusTrkB2ObjSrcRFSrr "ENM";
BA_ "SignalLongName" SG_ 1314 FFusTrkB2ObjSrcRFSrr "Forward Fusion Track B2 Object Source RFSRR";
BA_ "VNSigAllNodes" SG_ 1314 FFusTrkB2ObjSrcRFSrr 1;
BA_ "SignalType" SG_ 1314 FFusTrkB2ObjSrcVIs "ENM";
BA_ "SignalLongName" SG_ 1314 FFusTrkB2ObjSrcVIs "Forward Fusion Track B2 Object Source VIS";
BA_ "VNSigAllNodes" SG_ 1314 FFusTrkB2ObjSrcVIs 1;
BA_ "SignalType" SG_ 1314 FwdFusTrkB2ObjSrcLrr "ENM";
BA_ "SignalLongName" SG_ 1314 FwdFusTrkB2ObjSrcLrr "Forward Fusion Track B2 Object Source LRR";
BA_ "VNSigAllNodes" SG_ 1314 FwdFusTrkB2ObjSrcLrr 1;
BA_ "SignalType" SG_ 1314 FwdFusTrkB2NmCycTrkd "UNM";
BA_ "SignalLongName" SG_ 1314 FwdFusTrkB2NmCycTrkd "Forward Fusion Track B2 Number of Cycles Tracked";
BA_ "VNSigAllNodes" SG_ 1314 FwdFusTrkB2NmCycTrkd 1;
BA_ "SignalType" SG_ 1314 FwdFusTrkB2LatPosDev "UNM";
BA_ "SignalLongName" SG_ 1314 FwdFusTrkB2LatPosDev "Forward Fusion Track B2 Lateral Positiion Deviation";
BA_ "VNSigAllNodes" SG_ 1314 FwdFusTrkB2LatPosDev 1;
BA_ "SignalType" SG_ 1314 FwdFusTrkB2LngPosDev "UNM";
BA_ "SignalLongName" SG_ 1314 FwdFusTrkB2LngPosDev "Forward Fusion Track B2 Longitudinal Position Deviation";
BA_ "VNSigAllNodes" SG_ 1314 FwdFusTrkB2LngPosDev 1;
BA_ "SignalType" SG_ 1327 FwdFusTrkBAnlgRlLn15 "SNM";
BA_ "SignalLongName" SG_ 1327 FwdFusTrkBAnlgRlLn15 "Fwd Fusion Track B Analog relative Lane 15";
BA_ "VNSigAllNodes" SG_ 1327 FwdFusTrkBAnlgRlLn15 1;
BA_ "SignalType" SG_ 1327 FwdFusTrkB15RollingCnt "UNM";
BA_ "SignalLongName" SG_ 1327 FwdFusTrkB15RollingCnt "Forward Fusion Track B15 Rolling Count";
BA_ "VNSigAllNodes" SG_ 1327 FwdFusTrkB15RollingCnt 1;
BA_ "SignalType" SG_ 1327 FwdFusTrkB15Width "UNM";
BA_ "SignalLongName" SG_ 1327 FwdFusTrkB15Width "Forward Fusion Track B15 Width";
BA_ "GenSigStartValue" SG_ 1327 FwdFusTrkB15Width 1;
BA_ "VNSigAllNodes" SG_ 1327 FwdFusTrkB15Width 1;
BA_ "SignalType" SG_ 1327 FwdFusTrkB15MsgIndex "UNM";
BA_ "SignalLongName" SG_ 1327 FwdFusTrkB15MsgIndex "Forward Fusion Track B15 Message Index";
BA_ "VNSigAllNodes" SG_ 1327 FwdFusTrkB15MsgIndex 1;
BA_ "SignalType" SG_ 1327 FwdFusTrkB15DynProp "ENM";
BA_ "SignalLongName" SG_ 1327 FwdFusTrkB15DynProp "Forward Fusion Track B15 Dynamic Property";
BA_ "VNSigAllNodes" SG_ 1327 FwdFusTrkB15DynProp 1;
BA_ "SignalType" SG_ 1327 FwdFusTrkB15RelLnAccl "SNM";
BA_ "SignalLongName" SG_ 1327 FwdFusTrkB15RelLnAccl "Forward Fusion Track B15 Relative Lane Acceleration";
BA_ "VNSigAllNodes" SG_ 1327 FwdFusTrkB15RelLnAccl 1;
BA_ "SignalType" SG_ 1327 FwdFusTrkB15RelLane "ENM";
BA_ "SignalLongName" SG_ 1327 FwdFusTrkB15RelLane "Forward Fusion Track B15 Relative Lane";
BA_ "VNSigAllNodes" SG_ 1327 FwdFusTrkB15RelLane 1;
BA_ "SignalType" SG_ 1327 FwdFusTrkB15Height "UNM";
BA_ "SignalLongName" SG_ 1327 FwdFusTrkB15Height "Forward Fusion Track B15 Height";
BA_ "GenSigStartValue" SG_ 1327 FwdFusTrkB15Height 1;
BA_ "VNSigAllNodes" SG_ 1327 FwdFusTrkB15Height 1;
BA_ "SignalType" SG_ 1327 FFusTrkB15ObjSrcLFSrr "ENM";
BA_ "SignalLongName" SG_ 1327 FFusTrkB15ObjSrcLFSrr "Forward Fusion Track B15 Object Source LFSRR";
BA_ "VNSigAllNodes" SG_ 1327 FFusTrkB15ObjSrcLFSrr 1;
BA_ "SignalType" SG_ 1327 FFusTrkB15ObjSrcLCSrr "ENM";
BA_ "SignalLongName" SG_ 1327 FFusTrkB15ObjSrcLCSrr "Forward Fusion Track B15 Object Source LCSRR";
BA_ "VNSigAllNodes" SG_ 1327 FFusTrkB15ObjSrcLCSrr 1;
BA_ "SignalType" SG_ 1327 FFusTrkB15ObjSrcRCSrr "ENM";
BA_ "SignalLongName" SG_ 1327 FFusTrkB15ObjSrcRCSrr "Forward Fusion Track B15 Object Source RCSRR";
BA_ "VNSigAllNodes" SG_ 1327 FFusTrkB15ObjSrcRCSrr 1;
BA_ "SignalType" SG_ 1327 FFusTrkB15ObjSrcRFSrr "ENM";
BA_ "SignalLongName" SG_ 1327 FFusTrkB15ObjSrcRFSrr "Forward Fusion Track B15 Object Source RFSRR";
BA_ "VNSigAllNodes" SG_ 1327 FFusTrkB15ObjSrcRFSrr 1;
BA_ "SignalType" SG_ 1327 FFusTkB15ObjSrcVIs "ENM";
BA_ "SignalLongName" SG_ 1327 FFusTkB15ObjSrcVIs "Forward Fusion Track B15 Object Source VIS";
BA_ "VNSigAllNodes" SG_ 1327 FFusTkB15ObjSrcVIs 1;
BA_ "SignalType" SG_ 1327 FwdFusTrkB15ObjSrcLrr "ENM";
BA_ "SignalLongName" SG_ 1327 FwdFusTrkB15ObjSrcLrr "Forward Fusion Track B15 Object Source LRR";
BA_ "VNSigAllNodes" SG_ 1327 FwdFusTrkB15ObjSrcLrr 1;
BA_ "SignalType" SG_ 1327 FwdFusTrkB15NmCycTrkd "UNM";
BA_ "SignalLongName" SG_ 1327 FwdFusTrkB15NmCycTrkd "Forward Fusion Track B15 Number of Cycles Tracked";
BA_ "VNSigAllNodes" SG_ 1327 FwdFusTrkB15NmCycTrkd 1;
BA_ "SignalType" SG_ 1327 FwdFusTrkB15LatPosDev "UNM";
BA_ "SignalLongName" SG_ 1327 FwdFusTrkB15LatPosDev "Forward Fusion Track B15 Lateral Positiion Deviation";
BA_ "VNSigAllNodes" SG_ 1327 FwdFusTrkB15LatPosDev 1;
BA_ "SignalType" SG_ 1327 FwdFusTrkB15LngPosDev "UNM";
BA_ "SignalLongName" SG_ 1327 FwdFusTrkB15LngPosDev "Forward Fusion Track B15 Longitudinal Position Deviation";
BA_ "VNSigAllNodes" SG_ 1327 FwdFusTrkB15LngPosDev 1;
BA_ "SignalType" SG_ 1326 FwdFusTrkBAnlgRlLn14 "SNM";
BA_ "SignalLongName" SG_ 1326 FwdFusTrkBAnlgRlLn14 "Fwd Fusion Track B Analog relative Lane 14";
BA_ "VNSigAllNodes" SG_ 1326 FwdFusTrkBAnlgRlLn14 1;
BA_ "SignalType" SG_ 1326 FwdFusTrkB14RollingCnt "UNM";
BA_ "SignalLongName" SG_ 1326 FwdFusTrkB14RollingCnt "Forward Fusion Track B14 Rolling Count";
BA_ "VNSigAllNodes" SG_ 1326 FwdFusTrkB14RollingCnt 1;
BA_ "SignalType" SG_ 1326 FwdFusTrkB14Width "UNM";
BA_ "SignalLongName" SG_ 1326 FwdFusTrkB14Width "Forward Fusion Track B14 Width";
BA_ "GenSigStartValue" SG_ 1326 FwdFusTrkB14Width 1;
BA_ "VNSigAllNodes" SG_ 1326 FwdFusTrkB14Width 1;
BA_ "SignalType" SG_ 1326 FwdFusTrkB14MsgIndex "UNM";
BA_ "SignalLongName" SG_ 1326 FwdFusTrkB14MsgIndex "Forward Fusion Track B14 Message Index";
BA_ "VNSigAllNodes" SG_ 1326 FwdFusTrkB14MsgIndex 1;
BA_ "SignalType" SG_ 1326 FwdFusTrkB14DynProp "ENM";
BA_ "SignalLongName" SG_ 1326 FwdFusTrkB14DynProp "Forward Fusion Track B14 Dynamic Property";
BA_ "VNSigAllNodes" SG_ 1326 FwdFusTrkB14DynProp 1;
BA_ "SignalType" SG_ 1326 FwdFusTrkB14RelLnAccl "SNM";
BA_ "SignalLongName" SG_ 1326 FwdFusTrkB14RelLnAccl "Forward Fusion Track B14 Relative Lane Acceleration";
BA_ "VNSigAllNodes" SG_ 1326 FwdFusTrkB14RelLnAccl 1;
BA_ "SignalType" SG_ 1326 FwdFusTrkB14RelLane "ENM";
BA_ "SignalLongName" SG_ 1326 FwdFusTrkB14RelLane "Forward Fusion Track B14 Relative Lane";
BA_ "VNSigAllNodes" SG_ 1326 FwdFusTrkB14RelLane 1;
BA_ "SignalType" SG_ 1326 FwdFusTrkB14Height "UNM";
BA_ "SignalLongName" SG_ 1326 FwdFusTrkB14Height "Forward Fusion Track B14 Height";
BA_ "GenSigStartValue" SG_ 1326 FwdFusTrkB14Height 1;
BA_ "VNSigAllNodes" SG_ 1326 FwdFusTrkB14Height 1;
BA_ "SignalType" SG_ 1326 FFusTrkB14ObjSrcLFSrr "ENM";
BA_ "SignalLongName" SG_ 1326 FFusTrkB14ObjSrcLFSrr "Forward Fusion Track B14 Object Source LFSRR";
BA_ "VNSigAllNodes" SG_ 1326 FFusTrkB14ObjSrcLFSrr 1;
BA_ "SignalType" SG_ 1326 FFusTrkB14ObjSrcLCSrr "ENM";
BA_ "SignalLongName" SG_ 1326 FFusTrkB14ObjSrcLCSrr "Forward Fusion Track B14 Object Source LCSRR";
BA_ "VNSigAllNodes" SG_ 1326 FFusTrkB14ObjSrcLCSrr 1;
BA_ "SignalType" SG_ 1326 FFusTrkB14ObjSrcRCSrr "ENM";
BA_ "SignalLongName" SG_ 1326 FFusTrkB14ObjSrcRCSrr "Forward Fusion Track B14 Object Source RCSRR";
BA_ "VNSigAllNodes" SG_ 1326 FFusTrkB14ObjSrcRCSrr 1;
BA_ "SignalType" SG_ 1326 FFusTrkB14ObjSrcRFSrr "ENM";
BA_ "SignalLongName" SG_ 1326 FFusTrkB14ObjSrcRFSrr "Forward Fusion Track B14 Object Source RFSRR";
BA_ "VNSigAllNodes" SG_ 1326 FFusTrkB14ObjSrcRFSrr 1;
BA_ "SignalType" SG_ 1326 FFusTrkB14ObjSrcVIs "ENM";
BA_ "SignalLongName" SG_ 1326 FFusTrkB14ObjSrcVIs "Forward Fusion Track B14 Object Source VIS";
BA_ "VNSigAllNodes" SG_ 1326 FFusTrkB14ObjSrcVIs 1;
BA_ "SignalType" SG_ 1326 FwdFusTrkB14ObjSrcLrr "ENM";
BA_ "SignalLongName" SG_ 1326 FwdFusTrkB14ObjSrcLrr "Forward Fusion Track B14 Object Source LRR";
BA_ "VNSigAllNodes" SG_ 1326 FwdFusTrkB14ObjSrcLrr 1;
BA_ "SignalType" SG_ 1326 FwdFusTrkB14NmCycTrkd "UNM";
BA_ "SignalLongName" SG_ 1326 FwdFusTrkB14NmCycTrkd "Forward Fusion Track B14 Number of Cycles Tracked";
BA_ "VNSigAllNodes" SG_ 1326 FwdFusTrkB14NmCycTrkd 1;
BA_ "SignalType" SG_ 1326 FwdFusTrkB14LatPosDev "UNM";
BA_ "SignalLongName" SG_ 1326 FwdFusTrkB14LatPosDev "Forward Fusion Track B14 Lateral Positiion Deviation";
BA_ "VNSigAllNodes" SG_ 1326 FwdFusTrkB14LatPosDev 1;
BA_ "SignalType" SG_ 1326 FwdFusTrkB14LngPosDev "UNM";
BA_ "SignalLongName" SG_ 1326 FwdFusTrkB14LngPosDev "Forward Fusion Track B14 Longitudinal Position Deviation";
BA_ "VNSigAllNodes" SG_ 1326 FwdFusTrkB14LngPosDev 1;
BA_ "SignalType" SG_ 1325 FwdFusTrkBAnlgRlLn13 "SNM";
BA_ "SignalLongName" SG_ 1325 FwdFusTrkBAnlgRlLn13 "Fwd Fusion Track B Analog relative Lane13";
BA_ "VNSigAllNodes" SG_ 1325 FwdFusTrkBAnlgRlLn13 1;
BA_ "SignalType" SG_ 1325 FwdFusTrkB13RollingCnt "UNM";
BA_ "SignalLongName" SG_ 1325 FwdFusTrkB13RollingCnt "Forward Fusion Track B13 Rolling Count";
BA_ "VNSigAllNodes" SG_ 1325 FwdFusTrkB13RollingCnt 1;
BA_ "SignalType" SG_ 1325 FwdFusTrkB13Width "UNM";
BA_ "SignalLongName" SG_ 1325 FwdFusTrkB13Width "Forward Fusion Track B13 Width";
BA_ "GenSigStartValue" SG_ 1325 FwdFusTrkB13Width 1;
BA_ "VNSigAllNodes" SG_ 1325 FwdFusTrkB13Width 1;
BA_ "SignalType" SG_ 1325 FwdFusTrkB13MsgIndex "UNM";
BA_ "SignalLongName" SG_ 1325 FwdFusTrkB13MsgIndex "Forward Fusion Track B13 Message Index";
BA_ "VNSigAllNodes" SG_ 1325 FwdFusTrkB13MsgIndex 1;
BA_ "SignalType" SG_ 1325 FwdFusTrkB13DynProp "ENM";
BA_ "SignalLongName" SG_ 1325 FwdFusTrkB13DynProp "Forward Fusion Track B13 Dynamic Property";
BA_ "VNSigAllNodes" SG_ 1325 FwdFusTrkB13DynProp 1;
BA_ "SignalType" SG_ 1325 FwdFusTrkB13RelLnAccl "SNM";
BA_ "SignalLongName" SG_ 1325 FwdFusTrkB13RelLnAccl "Forward Fusion Track B13 Relative Lane Acceleration";
BA_ "VNSigAllNodes" SG_ 1325 FwdFusTrkB13RelLnAccl 1;
BA_ "SignalType" SG_ 1325 FwdFusTrkB13RelLane "ENM";
BA_ "SignalLongName" SG_ 1325 FwdFusTrkB13RelLane "Forward Fusion Track B13 Relative Lane";
BA_ "VNSigAllNodes" SG_ 1325 FwdFusTrkB13RelLane 1;
BA_ "SignalType" SG_ 1325 FwdFusTrkB13Height "UNM";
BA_ "SignalLongName" SG_ 1325 FwdFusTrkB13Height "Forward Fusion Track B13 Height";
BA_ "GenSigStartValue" SG_ 1325 FwdFusTrkB13Height 1;
BA_ "VNSigAllNodes" SG_ 1325 FwdFusTrkB13Height 1;
BA_ "SignalType" SG_ 1325 FFusTrkB13ObjSrcLFSrr "ENM";
BA_ "SignalLongName" SG_ 1325 FFusTrkB13ObjSrcLFSrr "Forward Fusion Track B13 Object Source LFSRR";
BA_ "VNSigAllNodes" SG_ 1325 FFusTrkB13ObjSrcLFSrr 1;
BA_ "SignalType" SG_ 1325 FFusTrkB13ObjSrcLCSrr "ENM";
BA_ "SignalLongName" SG_ 1325 FFusTrkB13ObjSrcLCSrr "Forward Fusion Track B13 Object Source LCSRR";
BA_ "VNSigAllNodes" SG_ 1325 FFusTrkB13ObjSrcLCSrr 1;
BA_ "SignalType" SG_ 1325 FFusTrkB13ObjSrcRCSrr "ENM";
BA_ "SignalLongName" SG_ 1325 FFusTrkB13ObjSrcRCSrr "Forward Fusion Track B13 Object Source RCSRR";
BA_ "VNSigAllNodes" SG_ 1325 FFusTrkB13ObjSrcRCSrr 1;
BA_ "SignalType" SG_ 1325 FFusTrkB13ObjSrcRFSrr "ENM";
BA_ "SignalLongName" SG_ 1325 FFusTrkB13ObjSrcRFSrr "Forward Fusion Track B13 Object Source RFSRR";
BA_ "VNSigAllNodes" SG_ 1325 FFusTrkB13ObjSrcRFSrr 1;
BA_ "SignalType" SG_ 1325 FFusTrkB13ObjSrcVIs "ENM";
BA_ "SignalLongName" SG_ 1325 FFusTrkB13ObjSrcVIs "Forward Fusion Track B13 Object Source VIS";
BA_ "VNSigAllNodes" SG_ 1325 FFusTrkB13ObjSrcVIs 1;
BA_ "SignalType" SG_ 1325 FwdFusTrkB13ObjSrcLrr "ENM";
BA_ "SignalLongName" SG_ 1325 FwdFusTrkB13ObjSrcLrr "Forward Fusion Track B13 Object Source LRR";
BA_ "VNSigAllNodes" SG_ 1325 FwdFusTrkB13ObjSrcLrr 1;
BA_ "SignalType" SG_ 1325 FwdFusTrkB13NmCycTrkd "UNM";
BA_ "SignalLongName" SG_ 1325 FwdFusTrkB13NmCycTrkd "Forward Fusion Track B13 Number of Cycles Tracked";
BA_ "VNSigAllNodes" SG_ 1325 FwdFusTrkB13NmCycTrkd 1;
BA_ "SignalType" SG_ 1325 FwdFusTrkB13LatPosDev "UNM";
BA_ "SignalLongName" SG_ 1325 FwdFusTrkB13LatPosDev "Forward Fusion Track B13 Lateral Positiion Deviation";
BA_ "VNSigAllNodes" SG_ 1325 FwdFusTrkB13LatPosDev 1;
BA_ "SignalType" SG_ 1325 FwdFusTrkB13LngPosDev "UNM";
BA_ "SignalLongName" SG_ 1325 FwdFusTrkB13LngPosDev "Forward Fusion Track B13 Longitudinal Position Deviation";
BA_ "VNSigAllNodes" SG_ 1325 FwdFusTrkB13LngPosDev 1;
BA_ "SignalType" SG_ 1324 FwdFusTrkBAnlgRlLn12 "SNM";
BA_ "SignalLongName" SG_ 1324 FwdFusTrkBAnlgRlLn12 "Fwd Fusion Track B Analog relative Lane 12";
BA_ "VNSigAllNodes" SG_ 1324 FwdFusTrkBAnlgRlLn12 1;
BA_ "SignalType" SG_ 1324 FwdFusTrkB12RollingCnt "UNM";
BA_ "SignalLongName" SG_ 1324 FwdFusTrkB12RollingCnt "Forward Fusion Track B12 Rolling Count";
BA_ "VNSigAllNodes" SG_ 1324 FwdFusTrkB12RollingCnt 1;
BA_ "SignalType" SG_ 1324 FwdFusTrkB12Width "UNM";
BA_ "SignalLongName" SG_ 1324 FwdFusTrkB12Width "Forward Fusion Track B12 Width";
BA_ "GenSigStartValue" SG_ 1324 FwdFusTrkB12Width 1;
BA_ "VNSigAllNodes" SG_ 1324 FwdFusTrkB12Width 1;
BA_ "SignalType" SG_ 1324 FwdFusTrkB12MsgIndex "UNM";
BA_ "SignalLongName" SG_ 1324 FwdFusTrkB12MsgIndex "Forward Fusion Track B12 Message Index";
BA_ "VNSigAllNodes" SG_ 1324 FwdFusTrkB12MsgIndex 1;
BA_ "SignalType" SG_ 1324 FwdFusTrkB12DynProp "ENM";
BA_ "SignalLongName" SG_ 1324 FwdFusTrkB12DynProp "Forward Fusion Track B12 Dynamic Property";
BA_ "VNSigAllNodes" SG_ 1324 FwdFusTrkB12DynProp 1;
BA_ "SignalType" SG_ 1324 FwdFusTrkB12RelLnAccl "SNM";
BA_ "SignalLongName" SG_ 1324 FwdFusTrkB12RelLnAccl "Forward Fusion Track B12 Relative Lane Acceleration";
BA_ "VNSigAllNodes" SG_ 1324 FwdFusTrkB12RelLnAccl 1;
BA_ "SignalType" SG_ 1324 FwdFusTrkB12RelLane "ENM";
BA_ "SignalLongName" SG_ 1324 FwdFusTrkB12RelLane "Forward Fusion Track B12 Relative Lane";
BA_ "VNSigAllNodes" SG_ 1324 FwdFusTrkB12RelLane 1;
BA_ "SignalType" SG_ 1324 FwdFusTrkB12Height "UNM";
BA_ "SignalLongName" SG_ 1324 FwdFusTrkB12Height "Forward Fusion Track B12 Height";
BA_ "GenSigStartValue" SG_ 1324 FwdFusTrkB12Height 1;
BA_ "VNSigAllNodes" SG_ 1324 FwdFusTrkB12Height 1;
BA_ "SignalType" SG_ 1324 FFusTrkB12ObjSrcLFSrr "ENM";
BA_ "SignalLongName" SG_ 1324 FFusTrkB12ObjSrcLFSrr "Forward Fusion Track B12 Object Source LFSRR";
BA_ "VNSigAllNodes" SG_ 1324 FFusTrkB12ObjSrcLFSrr 1;
BA_ "SignalType" SG_ 1324 FFusTrkB12ObjSrcLCSrr "ENM";
BA_ "SignalLongName" SG_ 1324 FFusTrkB12ObjSrcLCSrr "Forward Fusion Track B12 Object Source LCSRR";
BA_ "VNSigAllNodes" SG_ 1324 FFusTrkB12ObjSrcLCSrr 1;
BA_ "SignalType" SG_ 1324 FFusTrkB12ObjSrcRCSrr "ENM";
BA_ "SignalLongName" SG_ 1324 FFusTrkB12ObjSrcRCSrr "Forward Fusion Track B12 Object Source RCSRR";
BA_ "VNSigAllNodes" SG_ 1324 FFusTrkB12ObjSrcRCSrr 1;
BA_ "SignalType" SG_ 1324 FFusTrkB12ObjSrcRFSrr "ENM";
BA_ "SignalLongName" SG_ 1324 FFusTrkB12ObjSrcRFSrr "Forward Fusion Track B12 Object Source RFSRR";
BA_ "VNSigAllNodes" SG_ 1324 FFusTrkB12ObjSrcRFSrr 1;
BA_ "SignalType" SG_ 1324 FFusTrkB12ObjSrcVIs "ENM";
BA_ "SignalLongName" SG_ 1324 FFusTrkB12ObjSrcVIs "Forward Fusion Track B12 Object Source VIS";
BA_ "VNSigAllNodes" SG_ 1324 FFusTrkB12ObjSrcVIs 1;
BA_ "SignalType" SG_ 1324 FwdFusTrkB12ObjSrcLrr "ENM";
BA_ "SignalLongName" SG_ 1324 FwdFusTrkB12ObjSrcLrr "Forward Fusion Track B12 Object Source LRR";
BA_ "VNSigAllNodes" SG_ 1324 FwdFusTrkB12ObjSrcLrr 1;
BA_ "SignalType" SG_ 1324 FwdFusTrkB12NmCycTrkd "UNM";
BA_ "SignalLongName" SG_ 1324 FwdFusTrkB12NmCycTrkd "Forward Fusion Track B12 Number of Cycles Tracked";
BA_ "VNSigAllNodes" SG_ 1324 FwdFusTrkB12NmCycTrkd 1;
BA_ "SignalType" SG_ 1324 FwdFusTrkB12LatPosDev "UNM";
BA_ "SignalLongName" SG_ 1324 FwdFusTrkB12LatPosDev "Forward Fusion Track B12 Lateral Positiion Deviation";
BA_ "VNSigAllNodes" SG_ 1324 FwdFusTrkB12LatPosDev 1;
BA_ "SignalType" SG_ 1324 FwdFusTrkB12LngPosDev "UNM";
BA_ "SignalLongName" SG_ 1324 FwdFusTrkB12LngPosDev "Forward Fusion Track B12 Longitudinal Position Deviation";
BA_ "VNSigAllNodes" SG_ 1324 FwdFusTrkB12LngPosDev 1;
BA_REL_ "GenSigSuprvResp" BU_SG_REL_ EOCM_F_FO SG_ 1538 LFSRRYear 1;
BA_REL_ "GenSigTimeoutTime" BU_SG_REL_ EOCM_F_FO SG_ 1538 LFSRRYear 120;
BA_REL_ "GenSigSuprvResp" BU_SG_REL_ EOCM_F_FO SG_ 1538 LFSRRSerialNmbr 1;
BA_REL_ "GenSigTimeoutTime" BU_SG_REL_ EOCM_F_FO SG_ 1538 LFSRRSerialNmbr 120;
BA_REL_ "GenSigSuprvResp" BU_SG_REL_ EOCM_F_FO SG_ 1538 LFSRRJulianDate 1;
BA_REL_ "GenSigTimeoutTime" BU_SG_REL_ EOCM_F_FO SG_ 1538 LFSRRJulianDate 120;
BA_REL_ "GenSigSuprvResp" BU_SG_REL_ EOCM_F_FO SG_ 1537 RSRRYear 1;
BA_REL_ "GenSigTimeoutTime" BU_SG_REL_ EOCM_F_FO SG_ 1537 RSRRYear 120;
BA_REL_ "GenSigSuprvResp" BU_SG_REL_ EOCM_F_FO SG_ 1537 RSRRSerialNmbr 1;
BA_REL_ "GenSigTimeoutTime" BU_SG_REL_ EOCM_F_FO SG_ 1537 RSRRSerialNmbr 120;
BA_REL_ "GenSigSuprvResp" BU_SG_REL_ EOCM_F_FO SG_ 1537 RSRRJulianDate 1;
BA_REL_ "GenSigTimeoutTime" BU_SG_REL_ EOCM_F_FO SG_ 1537 RSRRJulianDate 120;
BA_REL_ "GenSigSuprvResp" BU_SG_REL_ EOCM_F_FO SG_ 1120 FLRRRollingCount 1;
BA_REL_ "GenSigTimeoutMsg" BU_SG_REL_ EOCM_F_FO SG_ 1120 FLRRRollingCount 1120;
BA_REL_ "GenSigTimeoutTime" BU_SG_REL_ EOCM_F_FO SG_ 1120 FLRRRollingCount 170;
BA_REL_ "GenSigSuprvResp" BU_SG_REL_ EOCM_F_FO SG_ 1120 FLRRRollingCount 1;
BA_REL_ "GenSigTimeoutMsg" BU_SG_REL_ EOCM_F_FO SG_ 1120 FLRRRollingCount 1120;
BA_REL_ "GenSigTimeoutTime" BU_SG_REL_ EOCM_F_FO SG_ 1120 FLRRRollingCount 170;
BA_REL_ "GenSigVBitResp" BU_SG_REL_ EOCM_F_FO SG_ 1120 FLRRTimeStamp 1;
VAL_ 1091 FVisionObjectTypeTrk3 7 "no object present" 6 "fixed roadside object" 5 "fixed overhead object" 4 "pedestrian" 3 "motocycle  / bicycle" 2 "Large vehicle (semi)" 1 "4 Wheel Vehicle (car, small trk)" 0 "Unknown" ;
VAL_ 1091 FVisionConfTrk3 3 "confident" 2 "speculative" 1 "highly speculative" 0 "invalid" ;
VAL_ 1091 FVisionRelLaneTrk3 3 "Left Lane" 2 "Right Lane" 1 "Host Lane" 0 "Unknown" ;
VAL_ 1091 FVisionMeasStatTrk3 3 "Measured this cycle" 2 "Latent track not detctd this cyc" 1 "New Object" 0 "No Object" ;
VAL_ 1092 FVisionMeasStatTrk4 3 "Measured this cycle" 2 "Latent track not detctd this cyc" 1 "New Object" 0 "No Object" ;
VAL_ 1092 FVisionObjectTypeTrk4 7 "no object present" 6 "fixed roadside object" 5 "fixed overhead object" 4 "pedestrian" 3 "motocycle  / bicycle" 2 "Large vehicle (semi)" 1 "4 Wheel Vehicle (car, small trk)" 0 "Unknown" ;
VAL_ 1092 FVisionConfTrk4 3 "confident" 2 "speculative" 1 "highly speculative" 0 "invalid" ;
VAL_ 1092 FVisionRelLaneTrk4 3 "Left Lane" 2 "Right Lane" 1 "Host Lane" 0 "Unknown" ;
VAL_ 1093 FVisionObjectTypeTrk5 7 "no object present" 6 "fixed roadside object" 5 "fixed overhead object" 4 "pedestrian" 3 "motocycle  / bicycle" 2 "Large vehicle (semi)" 1 "4 Wheel Vehicle (car, small trk)" 0 "Unknown" ;
VAL_ 1093 FVisionConfTrk5 3 "confident" 2 "speculative" 1 "highly speculative" 0 "invalid" ;
VAL_ 1093 FVisionRelLaneTrk5 3 "Left Lane" 2 "Right Lane" 1 "Host Lane" 0 "Unknown" ;
VAL_ 1093 FVisionMeasStatTrk5 3 "Measured this cycle" 2 "Latent track not detctd this cyc" 1 "New Object" 0 "No Object" ;
VAL_ 1094 FVisionObjectTypeTrk6 7 "no object present" 6 "fixed roadside object" 5 "fixed overhead object" 4 "pedestrian" 3 "motocycle  / bicycle" 2 "Large vehicle (semi)" 1 "4 Wheel Vehicle (car, small trk)" 0 "Unknown" ;
VAL_ 1094 FVisionConfTrk6 3 "confident" 2 "speculative" 1 "highly speculative" 0 "invalid" ;
VAL_ 1094 FVisionRelLaneTrk6 3 "Left Lane" 2 "Right Lane" 1 "Host Lane" 0 "Unknown" ;
VAL_ 1094 FVisionMeasStatTrk6 3 "Measured this cycle" 2 "Latent track not detctd this cyc" 1 "New Object" 0 "No Object" ;
VAL_ 1095 FVisionObjectTypeTrk7 7 "no object present" 6 "fixed roadside object" 5 "fixed overhead object" 4 "pedestrian" 3 "motocycle  / bicycle" 2 "Large vehicle (semi)" 1 "4 Wheel Vehicle (car, small trk)" 0 "Unknown" ;
VAL_ 1095 FVisionConfTrk7 3 "confident" 2 "speculative" 1 "highly speculative" 0 "invalid" ;
VAL_ 1095 FVisionRelLaneTrk7 3 "Left Lane" 2 "Right Lane" 1 "Host Lane" 0 "Unknown" ;
VAL_ 1095 FVisionMeasStatTrk7 3 "Measured this cycle" 2 "Latent track not detctd this cyc" 1 "New Object" 0 "No Object" ;
VAL_ 1096 FVisionObjectTypeTrk8 7 "no object present" 6 "fixed roadside object" 5 "fixed overhead object" 4 "pedestrian" 3 "motocycle  / bicycle" 2 "Large vehicle (semi)" 1 "4 Wheel Vehicle (car, small trk)" 0 "Unknown" ;
VAL_ 1096 FVisionConfTrk8 3 "confident" 2 "speculative" 1 "highly speculative" 0 "invalid" ;
VAL_ 1096 FVisionRelLaneTrk8 3 "Left Lane" 2 "Right Lane" 1 "Host Lane" 0 "Unknown" ;
VAL_ 1096 FVisionMeasStatTrk8 3 "Measured this cycle" 2 "Latent track not detctd this cyc" 1 "New Object" 0 "No Object" ;
VAL_ 1097 FVisionObjectTypeTrk9 7 "no object present" 6 "fixed roadside object" 5 "fixed overhead object" 4 "pedestrian" 3 "motocycle  / bicycle" 2 "Large vehicle (semi)" 1 "4 Wheel Vehicle (car, small trk)" 0 "Unknown" ;
VAL_ 1097 FVisionConfTrk9 3 "confident" 2 "speculative" 1 "highly speculative" 0 "invalid" ;
VAL_ 1097 FVisionRelLaneTrk9 3 "Left Lane" 2 "Right Lane" 1 "Host Lane" 0 "Unknown" ;
VAL_ 1097 FVisionMeasStatTrk9 3 "Measured this cycle" 2 "Latent track not detctd this cyc" 1 "New Object" 0 "No Object" ;
VAL_ 1098 FVisionObjectTypeTrk10 7 "no object present" 6 "fixed roadside object" 5 "fixed overhead object" 4 "pedestrian" 3 "motocycle  / bicycle" 2 "Large vehicle (semi)" 1 "4 Wheel Vehicle (car, small trk)" 0 "Unknown" ;
VAL_ 1098 FVisionConfTrk10 3 "confident" 2 "speculative" 1 "highly speculative" 0 "invalid" ;
VAL_ 1098 FVisionRelLaneTrk10 3 "Left Lane" 2 "Right Lane" 1 "Host Lane" 0 "Unknown" ;
VAL_ 1098 FVisionMeasStatTrk10 3 "Measured this cycle" 2 "Latent track not detctd this cyc" 1 "New Object" 0 "No Object" ;
VAL_ 1120 FLRRModeCmdFdbk 5 "Sensing with reduced power" 4 "Undefined" 3 "Radio Silent" 2 "Sensing" 1 "Not Sensing" 0 "Undefined" ;
VAL_ 1120 FLRRTimeStampV 1 "Invalid" 0 "Valid" ;
VAL_ 1120 FLRRRoadTypeInfo 5 "Constiction Zone Exit" 4 "Construction Zone Entry" 3 "Highway" 2 "Secondary Road" 1 "City" 0 "Unknown" ;
VAL_ 1120 FLRRDiagSpare 1 "true" 0 "false" ;
VAL_ 1120 FLRRVltgOutRngLo 1 "true" 0 "false" ;
VAL_ 1120 FLRRVltgOutRngHi 1 "true" 0 "false" ;
VAL_ 1120 FLRRSvcAlgnInPrcs 1 "true" 0 "false" ;
VAL_ 1120 FLRRSnsrBlckd 1 "true" 0 "false" ;
VAL_ 1120 FLRRSnstvFltPrsntInt 1 "true" 0 "false" ;
VAL_ 1120 FLRRPlntAlgnInProc 1 "true" 0 "false" ;
VAL_ 1120 FLRRMsalgnYawRt 1 "true" 0 "false" ;
VAL_ 1120 FLRRMsalgnYawLt 1 "true" 0 "false" ;
VAL_ 1120 FLRRMsalgnRllRt 1 "true" 0 "false" ;
VAL_ 1120 FLRRMsalgnRllLt 1 "true" 0 "false" ;
VAL_ 1120 FLRRMsalgnPtchUp 1 "true" 0 "false" ;
VAL_ 1120 FLRRMsalgnPtchDn 1 "true" 0 "false" ;
VAL_ 1120 FLRRInitDiagCmplt 1 "true" 0 "false" ;
VAL_ 1120 FLRRHWFltPrsntInt 1 "true" 0 "false" ;
VAL_ 1120 FLRRExtIntrfrnc 1 "true" 0 "false" ;
VAL_ 1120 FLRRCANSgnlSpvFld 1 "true" 0 "false" ;
VAL_ 1120 FLRRCANRxErr 1 "true" 0 "false" ;
VAL_ 1120 FLRRCANIDAddrsUnsbl 1 "true" 0 "false" ;
VAL_ 1120 FLRRAmbTmpOutRngLw 1 "true" 0 "false" ;
VAL_ 1120 FLRRAmbTmpOutRngHi 1 "true" 0 "false" ;
VAL_ 1120 FLRRAntTngFltPrsnt 1 "true" 0 "false" ;
VAL_ 1120 FLRRAlgnFltPrsnt 1 "true" 0 "false" ;
VAL_ 1121 FLRRTrk1DynProp 4 "Moving in opposite direction" 3 "Moving in same direction as host" 2 "Has moved but currently stopped" 1 "Has never moved" 0 "Unknown" ;
VAL_ 1121 FLRRTrk1MeasStatus 3 "Measured this cycle" 2 "Latent track not detctd this cyc" 1 "New Object" 0 "No Object" ;
VAL_ 1121 FLRRTrk1Conf 3 "confident" 2 "speculative" 1 "highly speculative" 0 "invalid" ;
VAL_ 1122 FLRRTrk2DynProp 4 "Moving in opposite direction" 3 "Moving in same direction as host" 2 "Has moved but currently stopped" 1 "Has never moved" 0 "Unknown" ;
VAL_ 1122 FLRRTrk2MeasStatus 3 "Measured this cycle" 2 "Latent track not detctd this cyc" 1 "New Object" 0 "No Object" ;
VAL_ 1122 FLRRTrk2Conf 3 "confident" 2 "speculative" 1 "highly speculative" 0 "invalid" ;
VAL_ 1123 FLRRTrk3DynProp 4 "Moving in opposite direction" 3 "Moving in same direction as host" 2 "Has moved but currently stopped" 1 "Has never moved" 0 "Unknown" ;
VAL_ 1123 FLRRTrk3MeasStatus 3 "Measured this cycle" 2 "Latent track not detctd this cyc" 1 "New Object" 0 "No Object" ;
VAL_ 1123 FLRRTrk3Conf 3 "confident" 2 "speculative" 1 "highly speculative" 0 "invalid" ;
VAL_ 1124 FLRRTrk4DynProp 4 "Moving in opposite direction" 3 "Moving in same direction as host" 2 "Has moved but currently stopped" 1 "Has never moved" 0 "Unknown" ;
VAL_ 1124 FLRRTrk4MeasStatus 3 "Measured this cycle" 2 "Latent track not detctd this cyc" 1 "New Object" 0 "No Object" ;
VAL_ 1124 FLRRTrk4Conf 3 "confident" 2 "speculative" 1 "highly speculative" 0 "invalid" ;
VAL_ 1125 FLRRTrk5DynProp 4 "Moving in opposite direction" 3 "Moving in same direction as host" 2 "Has moved but currently stopped" 1 "Has never moved" 0 "Unknown" ;
VAL_ 1125 FLRRTrk5MeasStatus 3 "Measured this cycle" 2 "Latent track not detctd this cyc" 1 "New Object" 0 "No Object" ;
VAL_ 1125 FLRRTrk5Conf 3 "confident" 2 "speculative" 1 "highly speculative" 0 "invalid" ;
VAL_ 1126 FLRRTrk6Conf 3 "confident" 2 "speculative" 1 "highly speculative" 0 "invalid" ;
VAL_ 1126 FLRRTrk6DynProp 4 "Moving in opposite direction" 3 "Moving in same direction as host" 2 "Has moved but currently stopped" 1 "Has never moved" 0 "Unknown" ;
VAL_ 1126 FLRRTrk6MeasStatus 3 "Measured this cycle" 2 "Latent track not detctd this cyc" 1 "New Object" 0 "No Object" ;
VAL_ 1127 FLRRTrk7Conf 3 "confident" 2 "speculative" 1 "highly speculative" 0 "invalid" ;
VAL_ 1127 FLRRTrk7DynProp 4 "Moving in opposite direction" 3 "Moving in same direction as host" 2 "Has moved but currently stopped" 1 "Has never moved" 0 "Unknown" ;
VAL_ 1127 FLRRTrk7MeasStatus 3 "Measured this cycle" 2 "Latent track not detctd this cyc" 1 "New Object" 0 "No Object" ;
VAL_ 1128 FLRRTrk8Conf 3 "confident" 2 "speculative" 1 "highly speculative" 0 "invalid" ;
VAL_ 1128 FLRRTrk8DynProp 4 "Moving in opposite direction" 3 "Moving in same direction as host" 2 "Has moved but currently stopped" 1 "Has never moved" 0 "Unknown" ;
VAL_ 1128 FLRRTrk8MeasStatus 3 "Measured this cycle" 2 "Latent track not detctd this cyc" 1 "New Object" 0 "No Object" ;
VAL_ 1129 FLRRTrk9Conf 3 "confident" 2 "speculative" 1 "highly speculative" 0 "invalid" ;
VAL_ 1129 FLRRTrk9DynProp 4 "Moving in opposite direction" 3 "Moving in same direction as host" 2 "Has moved but currently stopped" 1 "Has never moved" 0 "Unknown" ;
VAL_ 1129 FLRRTrk9MeasStatus 3 "Measured this cycle" 2 "Latent track not detctd this cyc" 1 "New Object" 0 "No Object" ;
VAL_ 1130 FLRRTrk10Conf 3 "confident" 2 "speculative" 1 "highly speculative" 0 "invalid" ;
VAL_ 1130 FLRRTrk10DynProp 4 "Moving in opposite direction" 3 "Moving in same direction as host" 2 "Has moved but currently stopped" 1 "Has never moved" 0 "Unknown" ;
VAL_ 1130 FLRRTrk10MeasStatus 3 "Measured this cycle" 2 "Latent track not detctd this cyc" 1 "New Object" 0 "No Object" ;
VAL_ 1131 FLRRTrk11Conf 3 "confident" 2 "speculative" 1 "highly speculative" 0 "invalid" ;
VAL_ 1131 FLRRTrk11DynProp 4 "Moving in opposite direction" 3 "Moving in same direction as host" 2 "Has moved but currently stopped" 1 "Has never moved" 0 "Unknown" ;
VAL_ 1131 FLRRTrk11MeasStatus 3 "Measured this cycle" 2 "Latent track not detctd this cyc" 1 "New Object" 0 "No Object" ;
VAL_ 1132 FLRRTrk12Conf 3 "confident" 2 "speculative" 1 "highly speculative" 0 "invalid" ;
VAL_ 1132 FLRRTrk12DynProp 4 "Moving in opposite direction" 3 "Moving in same direction as host" 2 "Has moved but currently stopped" 1 "Has never moved" 0 "Unknown" ;
VAL_ 1132 FLRRTrk12MeasStatus 3 "Measured this cycle" 2 "Latent track not detctd this cyc" 1 "New Object" 0 "No Object" ;
VAL_ 1133 FLRRTrk13Conf 3 "confident" 2 "speculative" 1 "highly speculative" 0 "invalid" ;
VAL_ 1133 FLRRTrk13DynProp 4 "Moving in opposite direction" 3 "Moving in same direction as host" 2 "Has moved but currently stopped" 1 "Has never moved" 0 "Unknown" ;
VAL_ 1133 FLRRTrk13MeasStatus 3 "Measured this cycle" 2 "Latent track not detctd this cyc" 1 "New Object" 0 "No Object" ;
VAL_ 1134 FLRRTrk14Conf 3 "confident" 2 "speculative" 1 "highly speculative" 0 "invalid" ;
VAL_ 1134 FLRRTrk14DynProp 4 "Moving in opposite direction" 3 "Moving in same direction as host" 2 "Has moved but currently stopped" 1 "Has never moved" 0 "Unknown" ;
VAL_ 1134 FLRRTrk14MeasStatus 3 "Measured this cycle" 2 "Latent track not detctd this cyc" 1 "New Object" 0 "No Object" ;
VAL_ 1135 FLRRTrk15MeasStatus 3 "Measured this cycle" 2 "Latent track not detctd this cyc" 1 "New Object" 0 "No Object" ;
VAL_ 1135 FLRRTrk15Conf 3 "confident" 2 "speculative" 1 "highly speculative" 0 "invalid" ;
VAL_ 1135 FLRRTrk15DynProp 4 "Moving in opposite direction" 3 "Moving in same direction as host" 2 "Has moved but currently stopped" 1 "Has never moved" 0 "Unknown" ;
VAL_ 1136 FLRRTrk16Conf 3 "confident" 2 "speculative" 1 "highly speculative" 0 "invalid" ;
VAL_ 1136 FLRRTrk16DynProp 4 "Moving in opposite direction" 3 "Moving in same direction as host" 2 "Has moved but currently stopped" 1 "Has never moved" 0 "Unknown" ;
VAL_ 1136 FLRRTrk16MeasStatus 3 "Measured this cycle" 2 "Latent track not detctd this cyc" 1 "New Object" 0 "No Object" ;
VAL_ 1137 FLRRTrk17Conf 3 "confident" 2 "speculative" 1 "highly speculative" 0 "invalid" ;
VAL_ 1137 FLRRTrk17DynProp 4 "Moving in opposite direction" 3 "Moving in same direction as host" 2 "Has moved but currently stopped" 1 "Has never moved" 0 "Unknown" ;
VAL_ 1137 FLRRTrk17MeasStatus 3 "Measured this cycle" 2 "Latent track not detctd this cyc" 1 "New Object" 0 "No Object" ;
VAL_ 1138 FLRRTrk18Conf 3 "confident" 2 "speculative" 1 "highly speculative" 0 "invalid" ;
VAL_ 1138 FLRRTrk18DynProp 4 "Moving in opposite direction" 3 "Moving in same direction as host" 2 "Has moved but currently stopped" 1 "Has never moved" 0 "Unknown" ;
VAL_ 1138 FLRRTrk18MeasStatus 3 "Measured this cycle" 2 "Latent track not detctd this cyc" 1 "New Object" 0 "No Object" ;
VAL_ 1139 FLRRTrk19Conf 3 "confident" 2 "speculative" 1 "highly speculative" 0 "invalid" ;
VAL_ 1139 FLRRTrk19DynProp 4 "Moving in opposite direction" 3 "Moving in same direction as host" 2 "Has moved but currently stopped" 1 "Has never moved" 0 "Unknown" ;
VAL_ 1139 FLRRTrk19MeasStatus 3 "Measured this cycle" 2 "Latent track not detctd this cyc" 1 "New Object" 0 "No Object" ;
VAL_ 1140 FLRRTrk20Conf 3 "confident" 2 "speculative" 1 "highly speculative" 0 "invalid" ;
VAL_ 1140 FLRRTrk20DynProp 4 "Moving in opposite direction" 3 "Moving in same direction as host" 2 "Has moved but currently stopped" 1 "Has never moved" 0 "Unknown" ;
VAL_ 1140 FLRRTrk20MeasStatus 3 "Measured this cycle" 2 "Latent track not detctd this cyc" 1 "New Object" 0 "No Object" ;
VAL_ 1141 ObjLossInfoObjTrk1 2 "elevation conditions" 1 "tight curve" 0 "not lost" ;
VAL_ 1141 ObjLossInfoObjTrk2 2 "elevation conditions" 1 "tight curve" 0 "not lost" ;
VAL_ 1141 ObjLossInfoObjTrk3 2 "elevation conditions" 1 "tight curve" 0 "not lost" ;
VAL_ 1141 ObjLossInfoObjTrk4 2 "elevation conditions" 1 "tight curve" 0 "not lost" ;
VAL_ 1141 ObjLossInfoObjTrk5 2 "elevation conditions" 1 "tight curve" 0 "not lost" ;
VAL_ 1141 ObjLossInfoObjTrk6 2 "elevation conditions" 1 "tight curve" 0 "not lost" ;
VAL_ 1321 FwdFusTrkB9DynProp 4 "Moving in opposite direction" 3 "Moving in same direction as host" 2 "Has moved but currently stopped" 1 "Has never moved" 0 "Unknown" ;
VAL_ 1321 FwdFusTrkB9RelLane 0 "Unknown" 3 "Left Lane" 2 "Right Lane" 1 "Host Lane" ;
VAL_ 1321 FFusTrkB9ObjSrcLFSrr 1 "true" 0 "false" ;
VAL_ 1321 FFusTrkB9ObjSrcLCSrr 1 "true" 0 "false" ;
VAL_ 1321 FFusTrkB9ObjSrcRCSrr 1 "true" 0 "false" ;
VAL_ 1321 FFusTrkB9ObjSrcRFSrr 1 "true" 0 "false" ;
VAL_ 1321 FFusTrkB9ObjSrcVIs 1 "true" 0 "false" ;
VAL_ 1321 FwdFusTrkB9ObjSrcLrr 1 "true" 0 "false" ;
VAL_ 1320 FwdFusTrkB8DynProp 4 "Moving in opposite direction" 3 "Moving in same direction as host" 2 "Has moved but currently stopped" 1 "Has never moved" 0 "Unknown" ;
VAL_ 1320 FwdFusTrkB8RelLane 3 "Left Lane" 2 "Right Lane" 1 "Host Lane" 0 "Unknown" ;
VAL_ 1320 FFusTrkB8ObjSrcLFSrr 1 "true" 0 "false" ;
VAL_ 1320 FFusTrkB8ObjSrcLCSrr 1 "true" 0 "false" ;
VAL_ 1320 FFusTrkB8ObjSrcRCSrr 1 "true" 0 "false" ;
VAL_ 1320 FFusTrkB8ObjSrcRFSrr 1 "true" 0 "false" ;
VAL_ 1320 FFusTrkB8ObjSrcVIs 1 "true" 0 "false" ;
VAL_ 1320 FwdFusTrkB8ObjSrcLrr 1 "true" 0 "false" ;
VAL_ 1319 FwdFusTrkB7DynProp 4 "Moving in opposite direction" 3 "Moving in same direction as host" 2 "Has moved but currently stopped" 1 "Has never moved" 0 "Unknown" ;
VAL_ 1319 FwdFusTrkB7RelLane 3 "Left Lane" 2 "Right Lane" 1 "Host Lane" 0 "Unknown" ;
VAL_ 1319 FFusTrkB7ObjSrcLFSrr 1 "true" 0 "false" ;
VAL_ 1319 FFusTrkB7ObjSrcLCSrr 1 "true" 0 "false" ;
VAL_ 1319 FFusTrkB7ObjSrcRCSrr 1 "true" 0 "false" ;
VAL_ 1319 FFusTrkB7ObjSrcRFSrr 1 "true" 0 "false" ;
VAL_ 1319 FFusTrkB7ObjSrcVIs 1 "true" 0 "false" ;
VAL_ 1319 FwdFusTrkB7ObjSrcLrr 1 "true" 0 "false" ;
VAL_ 1318 FwdFusTrkB6DynProp 4 "Moving in opposite direction" 3 "Moving in same direction as host" 2 "Has moved but currently stopped" 1 "Has never moved" 0 "Unknown" ;
VAL_ 1318 FwdFusTrkB6RelLane 3 "Left Lane" 2 "Right Lane" 1 "Host Lane" 0 "Unknown" ;
VAL_ 1318 FFusTrkB6ObjSrcLFSrr 1 "true" 0 "false" ;
VAL_ 1318 FFusTrkB6ObjSrcLCSrr 1 "true" 0 "false" ;
VAL_ 1318 FFusTrkB6ObjSrcRCSrr 1 "true" 0 "false" ;
VAL_ 1318 FFusTrkB6ObjSrcRFSrr 1 "true" 0 "false" ;
VAL_ 1318 FFusTrkB6ObjSrcVIs 1 "true" 0 "false" ;
VAL_ 1318 FwdFusTrkB6ObjSrcLrr 1 "true" 0 "false" ;
VAL_ 1317 FwdFusTrkB5DynProp 4 "Moving in opposite direction" 3 "Moving in same direction as host" 2 "Has moved but currently stopped" 1 "Has never moved" 0 "Unknown" ;
VAL_ 1317 FwdFusTrkB5RelLane 3 "Left Lane" 2 "Right Lane" 1 "Host Lane" 0 "Unknown" ;
VAL_ 1317 FFusTrkB5ObjSrcLFSrr 1 "true" 0 "false" ;
VAL_ 1317 FFusTrkB5ObjSrcLCSrr 1 "true" 0 "false" ;
VAL_ 1317 FFusTrkB5ObjSrcRCSrr 1 "true" 0 "false" ;
VAL_ 1317 FFusTrkB5ObjSrcRFSrr 1 "true" 0 "false" ;
VAL_ 1317 FFusTrkB5ObjSrcVIs 1 "true" 0 "false" ;
VAL_ 1317 FwdFusTrkB5ObjSrcLrr 1 "true" 0 "false" ;
VAL_ 1316 FwdFusTrkB4DynProp 4 "Moving in opposite direction" 3 "Moving in same direction as host" 2 "Has moved but currently stopped" 1 "Has never moved" 0 "Unknown" ;
VAL_ 1316 FwdFusTrkB4RelLane 3 "Left Lane" 2 "Right Lane" 1 "Host Lane" 0 "Unknown" ;
VAL_ 1316 FFusTrkB4ObjSrcLFSrr 1 "true" 0 "false" ;
VAL_ 1316 FFusTrkB4ObjSrcLCSrr 1 "true" 0 "false" ;
VAL_ 1316 FFusTrkB4ObjSrcRCSrr 1 "true" 0 "false" ;
VAL_ 1316 FFusTrkB4ObjSrcRFSrr 1 "true" 0 "false" ;
VAL_ 1316 FFusTrkB4ObjSrcVIs 1 "true" 0 "false" ;
VAL_ 1316 FwdFusTrkB4ObjSrcLrr 1 "true" 0 "false" ;
VAL_ 1315 FwdFusTrkB3DynProp 4 "Moving in opposite direction" 3 "Moving in same direction as host" 2 "Has moved but currently stopped" 1 "Has never moved" 0 "Unknown" ;
VAL_ 1315 FwdFusTrkB3RelLane 3 "Left Lane" 2 "Right Lane" 1 "Host Lane" 0 "Unknown" ;
VAL_ 1315 FFusTrkB3ObjSrcLFSrr 1 "true" 0 "false" ;
VAL_ 1315 FFusTrkB3ObjSrcLCSrr 1 "true" 0 "false" ;
VAL_ 1315 FFusTrkB3ObjSrcRCSrr 1 "true" 0 "false" ;
VAL_ 1315 FFusTrkB3ObjSrcRFSrr 1 "true" 0 "false" ;
VAL_ 1315 FFusTrkB3ObjSrcVIs 1 "true" 0 "false" ;
VAL_ 1315 FwdFusTrkB3ObjSrcLrr 1 "true" 0 "false" ;
VAL_ 1314 FwdFusTrkB2DynProp 4 "Moving in opposite direction" 3 "Moving in same direction as host" 2 "Has moved but currently stopped" 1 "Has never moved" 0 "Unknown" ;
VAL_ 1314 FwdFusTrkB2RelLane 3 "Left Lane" 2 "Right Lane" 1 "Host Lane" 0 "Unknown" ;
VAL_ 1314 FFusTrkB2ObjSrcLFSrr 1 "true" 0 "false" ;
VAL_ 1314 FFusTrkB2ObjSrcLCSrr 1 "true" 0 "false" ;
VAL_ 1314 FFusTrkB2ObjSrcRCSrr 1 "true" 0 "false" ;
VAL_ 1314 FFusTrkB2ObjSrcRFSrr 1 "true" 0 "false" ;
VAL_ 1314 FFusTrkB2ObjSrcVIs 1 "true" 0 "false" ;
VAL_ 1314 FwdFusTrkB2ObjSrcLrr 1 "true" 0 "false" ;
VAL_ 1327 FwdFusTrkB15DynProp 4 "Moving in opposite direction" 3 "Moving in same direction as host" 2 "Has moved but currently stopped" 1 "Has never moved" 0 "Unknown" ;
VAL_ 1327 FwdFusTrkB15RelLane 3 "Left Lane" 2 "Right Lane" 1 "Host Lane" 0 "Unknown" ;
VAL_ 1327 FFusTrkB15ObjSrcLFSrr 1 "true" 0 "false" ;
VAL_ 1327 FFusTrkB15ObjSrcLCSrr 1 "true" 0 "false" ;
VAL_ 1327 FFusTrkB15ObjSrcRCSrr 1 "true" 0 "false" ;
VAL_ 1327 FFusTrkB15ObjSrcRFSrr 1 "true" 0 "false" ;
VAL_ 1327 FFusTkB15ObjSrcVIs 1 "true" 0 "false" ;
VAL_ 1327 FwdFusTrkB15ObjSrcLrr 1 "true" 0 "false" ;
VAL_ 1326 FwdFusTrkB14DynProp 4 "Moving in opposite direction" 3 "Moving in same direction as host" 2 "Has moved but currently stopped" 1 "Has never moved" 0 "Unknown" ;
VAL_ 1326 FwdFusTrkB14RelLane 3 "Left Lane" 2 "Right Lane" 1 "Host Lane" 0 "Unknown" ;
VAL_ 1326 FFusTrkB14ObjSrcLFSrr 1 "true" 0 "false" ;
VAL_ 1326 FFusTrkB14ObjSrcLCSrr 1 "true" 0 "false" ;
VAL_ 1326 FFusTrkB14ObjSrcRCSrr 1 "true" 0 "false" ;
VAL_ 1326 FFusTrkB14ObjSrcRFSrr 1 "true" 0 "false" ;
VAL_ 1326 FFusTrkB14ObjSrcVIs 1 "true" 0 "false" ;
VAL_ 1326 FwdFusTrkB14ObjSrcLrr 1 "true" 0 "false" ;
VAL_ 1325 FwdFusTrkB13DynProp 4 "Moving in opposite direction" 3 "Moving in same direction as host" 2 "Has moved but currently stopped" 1 "Has never moved" 0 "Unknown" ;
VAL_ 1325 FwdFusTrkB13RelLane 3 "Left Lane" 2 "Right Lane" 1 "Host Lane" 0 "Unknown" ;
VAL_ 1325 FFusTrkB13ObjSrcLFSrr 1 "true" 0 "false" ;
VAL_ 1325 FFusTrkB13ObjSrcLCSrr 1 "true" 0 "false" ;
VAL_ 1325 FFusTrkB13ObjSrcRCSrr 1 "true" 0 "false" ;
VAL_ 1325 FFusTrkB13ObjSrcRFSrr 1 "true" 0 "false" ;
VAL_ 1325 FFusTrkB13ObjSrcVIs 1 "true" 0 "false" ;
VAL_ 1325 FwdFusTrkB13ObjSrcLrr 1 "true" 0 "false" ;
VAL_ 1324 FwdFusTrkB12DynProp 4 "Moving in opposite direction" 3 "Moving in same direction as host" 2 "Has moved but currently stopped" 1 "Has never moved" 0 "Unknown" ;
VAL_ 1324 FwdFusTrkB12RelLane 3 "Left Lane" 2 "Right Lane" 1 "Host Lane" 0 "Unknown" ;
VAL_ 1324 FFusTrkB12ObjSrcLFSrr 1 "true" 0 "false" ;
VAL_ 1324 FFusTrkB12ObjSrcLCSrr 1 "true" 0 "false" ;
VAL_ 1324 FFusTrkB12ObjSrcRCSrr 1 "true" 0 "false" ;
VAL_ 1324 FFusTrkB12ObjSrcRFSrr 1 "true" 0 "false" ;
VAL_ 1324 FFusTrkB12ObjSrcVIs 1 "true" 0 "false" ;
VAL_ 1324 FwdFusTrkB12ObjSrcLrr 1 "true" 0 "false" ;
SIG_GROUP_ 1120 FLRRDiagStatus 1 : FLRRDiagSpare FLRRVltgOutRngLo FLRRVltgOutRngHi FLRRSvcAlgnInPrcs FLRRSnsrBlckd FLRRSnstvFltPrsntInt FLRRPlntAlgnInProc FLRRMsalgnYawRt FLRRMsalgnYawLt FLRRMsalgnRllRt FLRRMsalgnRllLt FLRRMsalgnPtchUp FLRRMsalgnPtchDn FLRRInitDiagCmplt FLRRHWFltPrsntInt FLRRExtIntrfrnc FLRRCANSgnlSpvFld FLRRCANRxErr FLRRCANIDAddrsUnsbl FLRRAmbTmpOutRngLw FLRRAmbTmpOutRngHi FLRRAntTngFltPrsnt FLRRAlgnFltPrsnt;
